[part 2 of 2: packages /E40_Platform_System_SystemPackage/Components to /E40_Platform_System_SystemPackage/Types/DataConstrs]
AUTOSAR XML (schema 4-2-1)
package /E40_Platform_System_SystemPackage/Components  (continued)
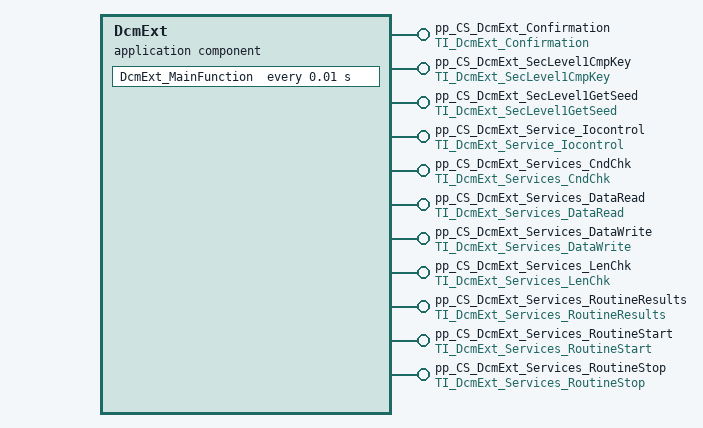
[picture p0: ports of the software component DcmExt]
  application sw component type DcmExt
    11 x provide port:
      pp_CS_DcmExt_Confirmation: server-com-spec{operation=DcmExt_Confirmation, queue-length=1}, provided-interface=TI_DcmExt_Confirmation
      pp_CS_DcmExt_SecLevel1CmpKey: server-com-spec{operation=DcmExt_SecLevel1CmpKey, queue-length=1}, provided-interface=TI_DcmExt_SecLevel1CmpKey
      pp_CS_DcmExt_SecLevel1GetSeed: server-com-spec{operation=DcmExt_SecLevel1GetSeed, queue-length=1}, provided-interface=TI_DcmExt_SecLevel1GetSeed
      pp_CS_DcmExt_Service_Iocontrol: server-com-spec{operation=DcmExt_Service_Iocontrol, queue-length=1}, provided-interface=TI_DcmExt_Service_Iocontrol
      pp_CS_DcmExt_Services_CndChk: server-com-spec{operation=DcmExt_Services_CndChk, queue-length=1}, provided-interface=TI_DcmExt_Services_CndChk
      pp_CS_DcmExt_Services_DataRead: server-com-spec{operation=DcmExt_Services_DataRead, queue-length=1}, provided-interface=TI_DcmExt_Services_DataRead
      pp_CS_DcmExt_Services_DataWrite: server-com-spec{operation=DcmExt_Services_DataWrite, queue-length=1}, provided-interface=TI_DcmExt_Services_DataWrite
      pp_CS_DcmExt_Services_LenChk: server-com-spec{operation=DcmExt_Services_LenChk, queue-length=1}, provided-interface=TI_DcmExt_Services_LenChk
      pp_CS_DcmExt_Services_RoutineResults: server-com-spec{operation=DcmExt_Services_RoutineResults, queue-length=1}, provided-interface=TI_DcmExt_Services_RoutineResults
      pp_CS_DcmExt_Services_RoutineStart: server-com-spec{operation=DcmExt_Services_RoutineStart, queue-length=1}, provided-interface=TI_DcmExt_Services_RoutineStart
      pp_CS_DcmExt_Services_RoutineStop: server-com-spec{operation=DcmExt_Services_RoutineStop, queue-length=1}, provided-interface=TI_DcmExt_Services_RoutineStop
    behavior IB_DcmExt
      11 x operation invoked event:
        OIE_pp_CS_DcmExt_Confirmation_DcmExt_ConfirmationTrigByDcmExt_Confirmation: start-on-event=DcmExt_Confirmation, operation=pp_CS_DcmExt_Confirmation.DcmExt_Confirmation
        OIE_pp_CS_DcmExt_SecLevel1CmpKey_DcmExt_SecLevel1CmpKeyTrigByDcmExt_SecLevel1CmpKey: start-on-event=DcmExt_SecLevel1CmpKey, operation=pp_CS_DcmExt_SecLevel1CmpKey.DcmExt_SecLevel1CmpKey
        OIE_pp_CS_DcmExt_SecLevel1GetSeed_DcmExt_SecLevel1GetSeedTrigByDcmExt_SecLevel1GetSeed: start-on-event=DcmExt_SecLevel1GetSeed, operation=pp_CS_DcmExt_SecLevel1GetSeed.DcmExt_SecLevel1GetSeed
        OIE_pp_CS_DcmExt_Service_Iocontrol_DcmExt_Service_IocontrolTrigByDcmExt_Service_Iocontrol: start-on-event=DcmExt_Service_Iocontrol, operation=pp_CS_DcmExt_Service_Iocontrol.DcmExt_Service_Iocontrol
        OIE_pp_CS_DcmExt_Services_CndChk_DcmExt_Services_CndChkTrigByDcmExt_Services_CndChk: start-on-event=DcmExt_Services_CndChk, operation=pp_CS_DcmExt_Services_CndChk.DcmExt_Services_CndChk
        OIE_pp_CS_DcmExt_Services_DataRead_DcmExt_Services_DataReadTrigByDcmExt_Services_DataRead: start-on-event=DcmExt_Services_DataRead, operation=pp_CS_DcmExt_Services_DataRead.DcmExt_Services_DataRead
        OIE_pp_CS_DcmExt_Services_DataWrite_DcmExt_Services_DataWriteTrigByDcmExt_Services_DataWrite: start-on-event=DcmExt_Services_DataWrite, operation=pp_CS_DcmExt_Services_DataWrite.DcmExt_Services_DataWrite
        OIE_pp_CS_DcmExt_Services_LenChk_DcmExt_Services_LenChkTrigByDcmExt_Services_LenChk: start-on-event=DcmExt_Services_LenChk, operation=pp_CS_DcmExt_Services_LenChk.DcmExt_Services_LenChk
        OIE_pp_CS_DcmExt_Services_RoutineResults_DcmExt_Services_RoutineResultsTrigByDcmExt_Services_RoutineResults: start-on-event=DcmExt_Services_RoutineResults, operation=pp_CS_DcmExt_Services_RoutineResults.DcmExt_Services_RoutineResults
        OIE_pp_CS_DcmExt_Services_RoutineStart_DcmExt_Services_RoutineStartTrigByDcmExt_Services_RoutineStart: start-on-event=DcmExt_Services_RoutineStart, operation=pp_CS_DcmExt_Services_RoutineStart.DcmExt_Services_RoutineStart
        OIE_pp_CS_DcmExt_Services_RoutineStop_DcmExt_Services_RoutineStopTrigByDcmExt_Services_RoutineStop: start-on-event=DcmExt_Services_RoutineStop, operation=pp_CS_DcmExt_Services_RoutineStop.DcmExt_Services_RoutineStop
      timing event TEDcmExt_MainFunction: start-on-event=DcmExt_MainFunction, period=0.01
      port-api-options:
        enable-take-address=false, indirect-api=false, port=pp_CS_DcmExt_Confirmation
        enable-take-address=false, indirect-api=false, port=pp_CS_DcmExt_SecLevel1CmpKey
        enable-take-address=false, indirect-api=false, port=pp_CS_DcmExt_SecLevel1GetSeed
        enable-take-address=false, indirect-api=false, port=pp_CS_DcmExt_Service_Iocontrol
        enable-take-address=false, indirect-api=false, port=pp_CS_DcmExt_Services_CndChk
        enable-take-address=false, indirect-api=false, port=pp_CS_DcmExt_Services_DataRead
        enable-take-address=false, indirect-api=false, port=pp_CS_DcmExt_Services_DataWrite
        enable-take-address=false, indirect-api=false, port=pp_CS_DcmExt_Services_LenChk
        enable-take-address=false, indirect-api=false, port=pp_CS_DcmExt_Services_RoutineResults
        enable-take-address=false, indirect-api=false, port=pp_CS_DcmExt_Services_RoutineStart
        enable-take-address=false, indirect-api=false, port=pp_CS_DcmExt_Services_RoutineStop
      12 x runnable, all with can-be-invoked-concurrently=true:
        DcmExt_Confirmation
        DcmExt_SecLevel1CmpKey
        DcmExt_SecLevel1GetSeed
        DcmExt_Service_Iocontrol
        DcmExt_Services_CndChk
        DcmExt_Services_DataRead
        DcmExt_Services_DataWrite
        DcmExt_Services_LenChk
        DcmExt_Services_RoutineResults
        DcmExt_Services_RoutineStart
        DcmExt_Services_RoutineStop
        DcmExt_MainFunction
  swc implementation IMPL_DcmExt: programming-language=C, behavior=IB_DcmExt
    code-descriptors:
      code CodeDescriptor
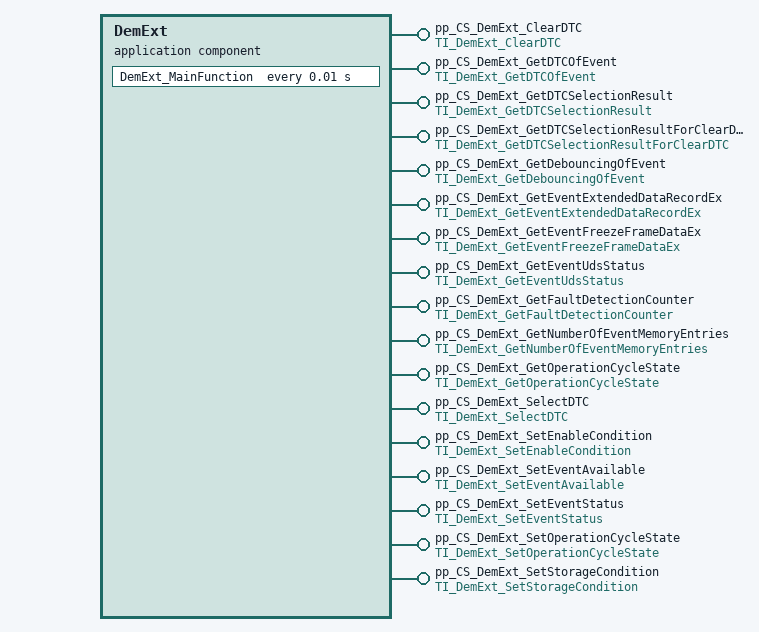
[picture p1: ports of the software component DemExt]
  application sw component type DemExt
    17 x provide port:
      pp_CS_DemExt_ClearDTC: server-com-spec{operation=DemExt_ClearDTC, queue-length=1}, provided-interface=TI_DemExt_ClearDTC
      pp_CS_DemExt_GetDTCOfEvent: server-com-spec{operation=DemExt_GetDTCOfEvent, queue-length=1}, provided-interface=TI_DemExt_GetDTCOfEvent
      pp_CS_DemExt_GetDTCSelectionResult: server-com-spec{operation=DemExt_GetDTCSelectionResult, queue-length=1}, provided-interface=TI_DemExt_GetDTCSelectionResult
      pp_CS_DemExt_GetDTCSelectionResultForClearDTC: server-com-spec{operation=DemExt_GetDTCSelectionResultForClearDTC, queue-length=1}, provided-interface=TI_DemExt_GetDTCSelectionResultForClearDTC
      pp_CS_DemExt_GetDebouncingOfEvent: server-com-spec{operation=DemExt_GetDebouncingOfEvent, queue-length=1}, provided-interface=TI_DemExt_GetDebouncingOfEvent
      pp_CS_DemExt_GetEventExtendedDataRecordEx: server-com-spec{operation=DemExt_GetEventExtendedDataRecordEx, queue-length=1}, provided-interface=TI_DemExt_GetEventExtendedDataRecordEx
      pp_CS_DemExt_GetEventFreezeFrameDataEx: server-com-spec{operation=DemExt_GetEventFreezeFrameDataEx, queue-length=1}, provided-interface=TI_DemExt_GetEventFreezeFrameDataEx
      pp_CS_DemExt_GetEventUdsStatus: server-com-spec{operation=DemExt_GetEventUdsStatus, queue-length=1}, provided-interface=TI_DemExt_GetEventUdsStatus
      pp_CS_DemExt_GetFaultDetectionCounter: server-com-spec{operation=DemExt_GetFaultDetectionCounter, queue-length=1}, provided-interface=TI_DemExt_GetFaultDetectionCounter
      pp_CS_DemExt_GetNumberOfEventMemoryEntries: server-com-spec{operation=DemExt_GetNumberOfEventMemoryEntries, queue-length=1}, provided-interface=TI_DemExt_GetNumberOfEventMemoryEntries
      pp_CS_DemExt_GetOperationCycleState: server-com-spec{operation=DemExt_GetOperationCycleState, queue-length=1}, provided-interface=TI_DemExt_GetOperationCycleState
      pp_CS_DemExt_SelectDTC: server-com-spec{operation=DemExt_SelectDTC, queue-length=1}, provided-interface=TI_DemExt_SelectDTC
      pp_CS_DemExt_SetEnableCondition: server-com-spec{operation=DemExt_SetEnableCondition, queue-length=1}, provided-interface=TI_DemExt_SetEnableCondition
      pp_CS_DemExt_SetEventAvailable: server-com-spec{operation=DemExt_SetEventAvailable, queue-length=1}, provided-interface=TI_DemExt_SetEventAvailable
      pp_CS_DemExt_SetEventStatus: server-com-spec{operation=DemExt_SetEventStatus, queue-length=1}, provided-interface=TI_DemExt_SetEventStatus
      pp_CS_DemExt_SetOperationCycleState: server-com-spec{operation=DemExt_SetOperationCycleState, queue-length=1}, provided-interface=TI_DemExt_SetOperationCycleState
      pp_CS_DemExt_SetStorageCondition: server-com-spec{operation=DemExt_SetStorageCondition, queue-length=1}, provided-interface=TI_DemExt_SetStorageCondition
    behavior IB_DemExt
      17 x operation invoked event:
        OIE_pp_CS_DemExt_ClearDTC_DemExt_ClearDTCTrigByDemExt_ClearDTC: start-on-event=DemExt_ClearDTC, operation=pp_CS_DemExt_ClearDTC.DemExt_ClearDTC
        OIE_pp_CS_DemExt_GetDTCOfEvent_DemExt_GetDTCOfEventTrigByDemExt_GetDTCOfEvent: start-on-event=DemExt_GetDTCOfEvent, operation=pp_CS_DemExt_GetDTCOfEvent.DemExt_GetDTCOfEvent
        OIE_pp_CS_DemExt_GetDTCSelectionResult_DemExt_GetDTCSelectionResultTrigByDemExt_GetDTCSelectionResult: start-on-event=DemExt_GetDTCSelectionResult, operation=pp_CS_DemExt_GetDTCSelectionResult.DemExt_GetDTCSelectionResult
        OperationInvokeEvent_1: start-on-event=DemExt_GetDTCSelectionResultForClearDTC, operation=pp_CS_DemExt_GetDTCSelectionResultForClearDTC.DemExt_GetDTCSelectionResultForClearDTC
        OIE_pp_CS_DemExt_GetDebouncingOfEvent_DemExt_GetDebouncingOfEventTrigByDemExt_GetDebouncingOfEvent: start-on-event=DemExt_GetDebouncingOfEvent, operation=pp_CS_DemExt_GetDebouncingOfEvent.DemExt_GetDebouncingOfEvent
        OIE_pp_CS_DemExt_GetEventExtendedDataRecordEx_DemExt_GetEventExtendedDataRecordExTrigByDemExt_GetEventExtendedDataRecordEx: start-on-event=DemExt_GetEventExtendedDataRecordEx, operation=pp_CS_DemExt_GetEventExtendedDataRecordEx.DemExt_GetEventExtendedDataRecordEx
        OIE_pp_CS_DemExt_GetEventFreezeFrameDataEx_DemExt_GetEventFreezeFrameDataExTrigByDemExt_GetEventFreezeFrameDataEx: start-on-event=DemExt_GetEventFreezeFrameDataEx, operation=pp_CS_DemExt_GetEventFreezeFrameDataEx.DemExt_GetEventFreezeFrameDataEx
        OIE_pp_CS_DemExt_GetEventUdsStatus_DemExt_GetEventUdsStatusTrigByDemExt_GetEventUdsStatus: start-on-event=DemExt_GetEventUdsStatus, operation=pp_CS_DemExt_GetEventUdsStatus.DemExt_GetEventUdsStatus
        OIE_pp_CS_DemExt_GetFaultDetectionCounter_DemExt_GetFaultDetectionCounterTrigByDemExt_GetFaultDetectionCounter: start-on-event=DemExt_GetFaultDetectionCounter, operation=pp_CS_DemExt_GetFaultDetectionCounter.DemExt_GetFaultDetectionCounter
        OIE_pp_CS_DemExt_GetNumberOfEventMemoryEntries_DemExt_GetNumberOfEventMemoryEntriesTrigByDemExt_GetNumberOfEventMemoryEntries: start-on-event=DemExt_GetNumberOfEventMemoryEntries, operation=pp_CS_DemExt_GetNumberOfEventMemoryEntries.DemExt_GetNumberOfEventMemoryEntries
        OIE_pp_CS_DemExt_GetOperationCycleState_DemExt_GetOperationCycleStateTrigByDemExt_GetOperationCycleState: start-on-event=DemExt_GetOperationCycleState, operation=pp_CS_DemExt_GetOperationCycleState.DemExt_GetOperationCycleState
        OIE_pp_CS_DemExt_SelectDTC_DemExt_SelectDTCTrigByDemExt_SelectDTC: start-on-event=DemExt_SelectDTC, operation=pp_CS_DemExt_SelectDTC.DemExt_SelectDTC
        OIE_pp_CS_DemExt_SetEnableCondition_DemExt_SetEnableConditionTrigByDemExt_SetEnableCondition: start-on-event=DemExt_SetEnableCondition, operation=pp_CS_DemExt_SetEnableCondition.DemExt_SetEnableCondition
        OIE_pp_CS_DemExt_SetEventAvailable_DemExt_SetEventAvailableTrigByDemExt_SetEventAvailable: start-on-event=DemExt_SetEventAvailable, operation=pp_CS_DemExt_SetEventAvailable.DemExt_SetEventAvailable
        OIE_pp_CS_DemExt_SetEventStatus_DemExt_SetEventStatusTrigByDemExt_SetEventStatus: start-on-event=DemExt_SetEventStatus, operation=pp_CS_DemExt_SetEventStatus.DemExt_SetEventStatus
        OIE_pp_CS_DemExt_SetOperationCycleState_DemExt_SetOperationCycleStateTrigByDemExt_SetOperationCycleState: start-on-event=DemExt_SetOperationCycleState, operation=pp_CS_DemExt_SetOperationCycleState.DemExt_SetOperationCycleState
        OIE_pp_CS_DemExt_SetStorageCondition_DemExt_SetStorageConditionTrigByDemExt_SetStorageCondition: start-on-event=DemExt_SetStorageCondition, operation=pp_CS_DemExt_SetStorageCondition.DemExt_SetStorageCondition
      timing event TEDemExt_MainFunction: start-on-event=DemExt_MainFunction, period=0.01
      port-api-options:
        enable-take-address=false, indirect-api=false, port=pp_CS_DemExt_ClearDTC
        enable-take-address=false, indirect-api=false, port=pp_CS_DemExt_GetDTCOfEvent
        enable-take-address=false, indirect-api=false, port=pp_CS_DemExt_GetDTCSelectionResult
        enable-take-address=false, indirect-api=false, port=pp_CS_DemExt_GetDTCSelectionResultForClearDTC
        enable-take-address=false, indirect-api=false, port=pp_CS_DemExt_GetDebouncingOfEvent
        enable-take-address=false, indirect-api=false, port=pp_CS_DemExt_GetEventExtendedDataRecordEx
        enable-take-address=false, indirect-api=false, port=pp_CS_DemExt_GetEventFreezeFrameDataEx
        enable-take-address=false, indirect-api=false, port=pp_CS_DemExt_GetEventUdsStatus
        enable-take-address=false, indirect-api=false, port=pp_CS_DemExt_GetFaultDetectionCounter
        enable-take-address=false, indirect-api=false, port=pp_CS_DemExt_GetNumberOfEventMemoryEntries
        enable-take-address=false, indirect-api=false, port=pp_CS_DemExt_GetOperationCycleState
        enable-take-address=false, indirect-api=false, port=pp_CS_DemExt_SelectDTC
        enable-take-address=false, indirect-api=false, port=pp_CS_DemExt_SetEnableCondition
        enable-take-address=false, indirect-api=false, port=pp_CS_DemExt_SetEventAvailable
        enable-take-address=false, indirect-api=false, port=pp_CS_DemExt_SetEventStatus
        enable-take-address=false, indirect-api=false, port=pp_CS_DemExt_SetOperationCycleState
        enable-take-address=false, indirect-api=false, port=pp_CS_DemExt_SetStorageCondition
      18 x runnable, all with can-be-invoked-concurrently=true:
        DemExt_ClearDTC
        DemExt_GetDTCOfEvent
        DemExt_GetDTCSelectionResult
        DemExt_GetDTCSelectionResultForClearDTC
        DemExt_GetDebouncingOfEvent
        DemExt_GetEventExtendedDataRecordEx
        DemExt_GetEventFreezeFrameDataEx
        DemExt_GetEventUdsStatus
        DemExt_GetFaultDetectionCounter
        DemExt_GetNumberOfEventMemoryEntries
        DemExt_GetOperationCycleState
        DemExt_SelectDTC
        DemExt_SetEnableCondition
        DemExt_SetEventAvailable
        DemExt_SetEventStatus
        DemExt_SetOperationCycleState
        DemExt_SetStorageCondition
        DemExt_MainFunction
  swc implementation IMPL_DemExt: programming-language=C, behavior=IB_DemExt
    code-descriptors:
      code CodeDescriptor
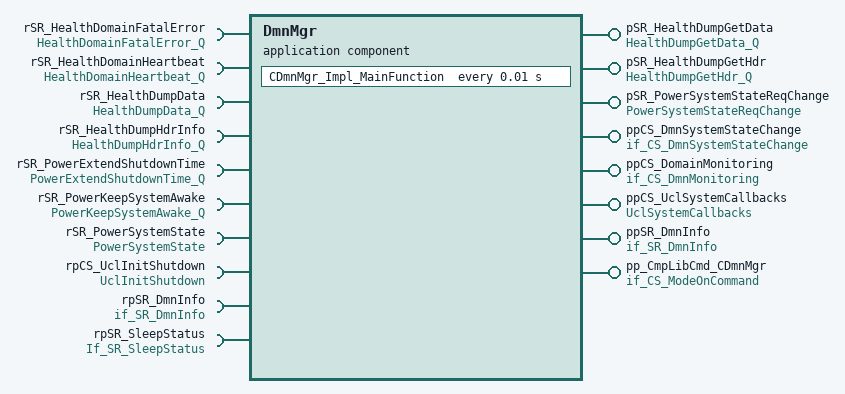
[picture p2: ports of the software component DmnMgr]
  application sw component type DmnMgr
    8 x provide port:
      pSR_HealthDumpGetData: queued-sender-com-spec=HealthDumpGetDataData, provided-interface=HealthDumpGetData_Q
      pSR_HealthDumpGetHdr: queued-sender-com-spec=HealthDumpGetHdrData, provided-interface=HealthDumpGetHdr_Q
      pSR_PowerSystemStateReqChange: nonqueued-sender-com-spec{data-element=PowerSystemStateReqChangeData, init-value=constant-reference=DmnMgrPowerSystemStateReqChangeDataValue0}, provided-interface=PowerSystemStateReqChange
      ppCS_DmnSystemStateChange: provided-interface=if_CS_DmnSystemStateChange
        provided-com-specs:
          operation=DmnSystemStateChangeReq, queue-length=1
          operation=DmnSystemStateChangeStatus, queue-length=1
      ppCS_DomainMonitoring: provided-com-specs=[{operation=StartDomainMonitoring, queue-length=1}, {operation=StopDomainMonitoring, queue-length=1}], provided-interface=if_CS_DmnMonitoring
      ppCS_UclSystemCallbacks: provided-com-specs=[{operation=ErrorNotification, queue-length=1}, {operation=LinkStatusChanged, queue-length=1}], provided-interface=UclSystemCallbacks
      ppSR_DmnInfo: nonqueued-sender-com-spec{data-element=SDmnStatus, init-value=constant-reference=DmnMgrSDmnStatusValue0}, provided-interface=if_SR_DmnInfo
      pp_CmpLibCmd_CDmnMgr: server-com-spec{operation=Impl_OnCommand, queue-length=1}, provided-interface=if_CS_ModeOnCommand
    10 x require port:
      rSR_HealthDomainFatalError: queued-receiver-com-spec{data-element=HealthDomainFatalErrorData, queue-length=2}, required-interface=HealthDomainFatalError_Q
      rSR_HealthDomainHeartbeat: queued-receiver-com-spec{data-element=HealthDomainHeartbeatData, queue-length=5}, required-interface=HealthDomainHeartbeat_Q
      rSR_HealthDumpData: queued-receiver-com-spec{data-element=HealthDumpDataData, queue-length=1}, required-interface=HealthDumpData_Q
      rSR_HealthDumpHdrInfo: queued-receiver-com-spec{data-element=HealthDumpHdrInfoData, queue-length=1}, required-interface=HealthDumpHdrInfo_Q
      rSR_PowerExtendShutdownTime: queued-receiver-com-spec{data-element=PowerExtendShutdownTimeData, queue-length=5}, required-interface=PowerExtendShutdownTime_Q
      rSR_PowerKeepSystemAwake: queued-receiver-com-spec{data-element=PowerKeepSystemAwakeData, queue-length=5}, required-interface=PowerKeepSystemAwake_Q
      rSR_PowerSystemState: nonqueued-receiver-com-spec{data-element=PowerSystemStateData, init-value=constant-reference=DmnMgrPowerSystemStateDataValue0}, required-interface=PowerSystemState
      rpCS_UclInitShutdown: required-interface=UclInitShutdown
      rpSR_DmnInfo: nonqueued-receiver-com-spec{data-element=SDmnStatus, init-value=constant-reference=DmnMgrSDmnStatusValue0}, required-interface=if_SR_DmnInfo
      rpSR_SleepStatus: nonqueued-receiver-com-spec{data-element=SleepManager_SleepStatus, init-value=constant-reference=DmnMgrSleepManager_SleepStatusValue0}, required-interface=If_SR_SleepStatus
    behavior IB_DmnMgr
      timing event TECDmnMgr_Impl_MainFunction: start-on-event=CDmnMgr_Impl_MainFunction, period=0.01
      5 x operation invoked event:
        OIE_pp_CmpLibCmd_CDmnMgr_CDmnMgr_Impl_OnCommandTrigByImpl_OnCommand: start-on-event=CDmnMgr_Impl_OnCommand, operation=pp_CmpLibCmd_CDmnMgr.Impl_OnCommand
        OIE_ppCS_DmnSystemStateChange_DmnMgr_DmnSystemStateChangeReqTrigByDmnSystemStateChangeReq: start-on-event=DmnMgr_DmnSystemStateChangeReq, operation=ppCS_DmnSystemStateChange.DmnSystemStateChangeReq
        OIE_ppCS_DmnSystemStateChange_DmnMgr_DmnSystemStateChangeStatusTrigByDmnSystemStateChangeStatus: start-on-event=DmnMgr_DmnSystemStateChangeStatus, operation=ppCS_DmnSystemStateChange.DmnSystemStateChangeStatus
        OIE_ppCS_UclSystemCallbacks_DmnMgr_ErrorNotificationTrigByErrorNotification: start-on-event=DmnMgr_ErrorNotification, operation=ppCS_UclSystemCallbacks.ErrorNotification
        OIE_ppCS_UclSystemCallbacks_DmnMgr_LinkStatusChangedTrigByLinkStatusChanged: start-on-event=DmnMgr_LinkStatusChanged, operation=ppCS_UclSystemCallbacks.LinkStatusChanged
      7 x data received event:
        DREDmnMgr_MonitorDmnExtendShutdownTimeTrigByPowerExtendShutdownTimeData: start-on-event=DmnMgr_MonitorDmnExtendShutdownTime, data=rSR_PowerExtendShutdownTime.PowerExtendShutdownTimeData
        DREDmnMgr_MonitorDmnHealthDumpDataTrigByHealthDumpDataData: start-on-event=DmnMgr_MonitorDmnHealthDumpData, data=rSR_HealthDumpData.HealthDumpDataData
        DREDmnMgr_MonitorDmnHealthDumpHdrInfoTrigByHealthDumpHdrInfoData: start-on-event=DmnMgr_MonitorDmnHealthDumpHdrInfo, data=rSR_HealthDumpHdrInfo.HealthDumpHdrInfoData
        DREDmnMgr_MonitorDmnHealthFatalErrorTrigByHealthDomainFatalErrorData: start-on-event=DmnMgr_MonitorDmnHealthFatalError, data=rSR_HealthDomainFatalError.HealthDomainFatalErrorData
        DREDmnMgr_MonitorDmnHeartBeatTrigByHealthDomainHeartbeatData: start-on-event=DmnMgr_MonitorDmnHeartBeat, data=rSR_HealthDomainHeartbeat.HealthDomainHeartbeatData
        DREDmnMgr_MonitorDmnKeepSystemAwakeTrigByPowerKeepSystemAwakeData: start-on-event=DmnMgr_MonitorDmnKeepSystemAwake, data=rSR_PowerKeepSystemAwake.PowerKeepSystemAwakeData
        DREDmnMgr_MonitorDmnPowerSystemStateTrigByPowerSystemStateData: start-on-event=DmnMgr_MonitorDmnPowerSystemState, data=rSR_PowerSystemState.PowerSystemStateData
      operation invoked event OIE_ppCS_DomainMonitoring_DmnMgr_StartDomainMonitoringTrigByStartDomainMonitoring: start-on-event=DmnMgr_StartDomainMonitoring, operation=ppCS_DomainMonitoring.StartDomainMonitoring
      operation invoked event OIE_ppCS_DomainMonitoring_DmnMgr_StopDomainMonitoringTrigByStopDomainMonitoring: start-on-event=DmnMgr_StopDomainMonitoring, operation=ppCS_DomainMonitoring.StopDomainMonitoring
      port-api-options:
        enable-take-address=false, indirect-api=false, port=pSR_HealthDumpGetData
        enable-take-address=false, indirect-api=false, port=pSR_HealthDumpGetHdr
        enable-take-address=false, indirect-api=false, port=pSR_PowerSystemStateReqChange
        enable-take-address=false, indirect-api=false, port=ppCS_DmnSystemStateChange
        enable-take-address=false, indirect-api=false, port=ppCS_DomainMonitoring
        enable-take-address=false, indirect-api=false, port=ppCS_UclSystemCallbacks
        enable-take-address=false, indirect-api=false, port=ppSR_DmnInfo
        enable-take-address=false, indirect-api=false, port=pp_CmpLibCmd_CDmnMgr
        enable-take-address=false, indirect-api=false, port=rSR_HealthDomainFatalError
        enable-take-address=false, indirect-api=false, port=rSR_HealthDomainHeartbeat
        enable-take-address=false, indirect-api=false, port=rSR_HealthDumpData
        enable-take-address=false, indirect-api=false, port=rSR_HealthDumpHdrInfo
        enable-take-address=false, indirect-api=false, port=rSR_PowerExtendShutdownTime
        enable-take-address=false, indirect-api=false, port=rSR_PowerKeepSystemAwake
        enable-take-address=false, indirect-api=false, port=rSR_PowerSystemState
        enable-take-address=false, indirect-api=false, port=rpCS_UclInitShutdown
        enable-take-address=false, indirect-api=false, port=rpSR_DmnInfo
        enable-take-address=false, indirect-api=false, port=DmnMgr/rpSR_SleepStatus
      15 x runnable, all with can-be-invoked-concurrently=true:
        CDmnMgr_Impl_MainFunction
          data-receive-point-by-arguments:
            9 x access:
              DRP_rSR_HealthDomainFatalError_HealthDomainFatalErrorData: accessed-variable=rSR_HealthDomainFatalError.HealthDomainFatalErrorData
              DRP_rSR_HealthDomainHeartbeat_HealthDomainHeartbeatData: accessed-variable=rSR_HealthDomainHeartbeat.HealthDomainHeartbeatData
              DRP_rSR_HealthDumpData_HealthDumpDataData: accessed-variable=rSR_HealthDumpData.HealthDumpDataData
              DRP_rSR_HealthDumpHdrInfo_HealthDumpHdrInfoData: accessed-variable=rSR_HealthDumpHdrInfo.HealthDumpHdrInfoData
              DRP_rSR_PowerExtendShutdownTime_PowerExtendShutdownTimeData: accessed-variable=rSR_PowerExtendShutdownTime.PowerExtendShutdownTimeData
              DRP_rSR_PowerKeepSystemAwake_PowerKeepSystemAwakeData: accessed-variable=rSR_PowerKeepSystemAwake.PowerKeepSystemAwakeData
              DRA_rSR_PowerSystemState_PowerSystemStateData: accessed-variable=rSR_PowerSystemState.PowerSystemStateData
              DRA_rpSR_DmnInfo_SDmnStatus: accessed-variable=rpSR_DmnInfo.SDmnStatus
              DRA_rpSR_SleepStatus_SleepManager_SleepStatus: accessed-variable=rpSR_SleepStatus.SleepManager_SleepStatus
          data-send-points:
            4 x access:
              DSP_pSR_HealthDumpGetData_HealthDumpGetDataData: accessed-variable=pSR_HealthDumpGetData.HealthDumpGetDataData
              DSP_pSR_HealthDumpGetHdr_HealthDumpGetHdrData: accessed-variable=pSR_HealthDumpGetHdr.HealthDumpGetHdrData
              DWA_pSR_PowerSystemStateReqChange_PowerSystemStateReqChangeData: accessed-variable=pSR_PowerSystemStateReqChange.PowerSystemStateReqChangeData
              DWA_ppSR_DmnInfo_SDmnStatus: accessed-variable=ppSR_DmnInfo.SDmnStatus
          sync call OA_rpCS_UclInitShutdown_Impl_Shutdown: operation=rpCS_UclInitShutdown.Impl_Shutdown, timeout=0.0
          sync call OA_rpCS_UclInitShutdown_Impl_Initialize: operation=rpCS_UclInitShutdown.Impl_Initialize, timeout=0.0
        CDmnMgr_Impl_OnCommand
        DmnMgr_DmnSystemStateChangeReq
        DmnMgr_DmnSystemStateChangeStatus
        DmnMgr_ErrorNotification
        DmnMgr_LinkStatusChanged
        DmnMgr_MonitorDmnExtendShutdownTime
        DmnMgr_MonitorDmnHealthDumpData
        DmnMgr_MonitorDmnHealthDumpHdrInfo
        DmnMgr_MonitorDmnHealthFatalError
        DmnMgr_MonitorDmnHeartBeat
        DmnMgr_MonitorDmnKeepSystemAwake
        DmnMgr_MonitorDmnPowerSystemState
        DmnMgr_StartDomainMonitoring
        DmnMgr_StopDomainMonitoring
  4 x constant specification:
    DmnMgrPowerSystemStateReqChangeDataValue0: value-spec={short-label=DmnMgrPowerSystemStateReqChangeDataValue0, fields=[DmnMgrPowerSystemStateReqChangeDataValue_0:0, DmnMgrPowerSystemStateReqChangeDataValue_1:0]}
    DmnMgrSDmnStatusValue0: value-spec={short-label=DmnMgrSDmnStatusValue0, fields=[DmnMgrSDmnStatusValue_0:0, DmnMgrSDmnStatusValue_1:0, DmnMgrSDmnStatusValue_2:0, DmnMgrSDmnStatusValue_3:0, DmnMgrSDmnStatusValue_4:0, DmnMgrSDmnStatusValue_5:0]}
    DmnMgrPowerSystemStateDataValue0: value-spec={short-label=DmnMgrPowerSystemStateDataValue0, fields=[DmnMgrPowerSystemStateDataValue_0:0, DmnMgrPowerSystemStateDataValue_1:0]}
    DmnMgrSleepManager_SleepStatusValue0: value-spec=DmnMgrSleepManager_SleepStatusValue0:0
  swc implementation IMPL_DmnMgr: programming-language=C, behavior=IB_DmnMgr
    code-descriptors:
      code CodeDescriptor
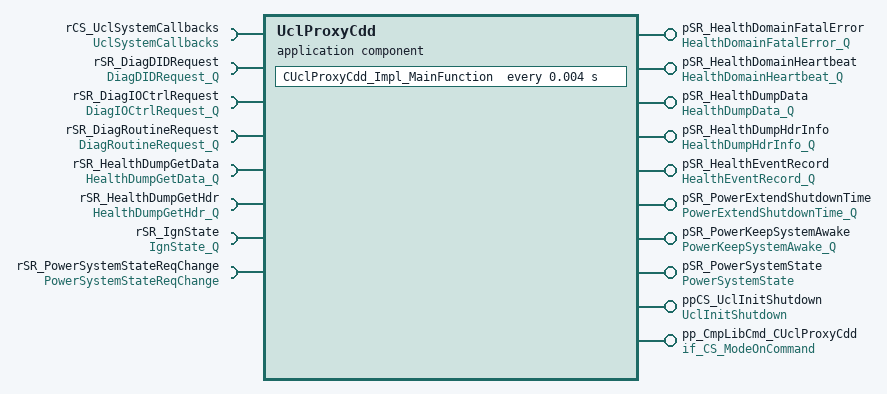
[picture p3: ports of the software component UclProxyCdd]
  application sw component type UclProxyCdd
    10 x provide port:
      pSR_HealthDomainFatalError: queued-sender-com-spec=HealthDomainFatalErrorData, provided-interface=HealthDomainFatalError_Q
      pSR_HealthDomainHeartbeat: queued-sender-com-spec=HealthDomainHeartbeatData, provided-interface=HealthDomainHeartbeat_Q
      pSR_HealthDumpData: queued-sender-com-spec=HealthDumpDataData, provided-interface=HealthDumpData_Q
      pSR_HealthDumpHdrInfo: queued-sender-com-spec=HealthDumpHdrInfoData, provided-interface=HealthDumpHdrInfo_Q
      pSR_HealthEventRecord: queued-sender-com-spec=HealthEventRecordData, provided-interface=HealthEventRecord_Q
      pSR_PowerExtendShutdownTime: queued-sender-com-spec=PowerExtendShutdownTimeData, provided-interface=PowerExtendShutdownTime_Q
      pSR_PowerKeepSystemAwake: queued-sender-com-spec=PowerKeepSystemAwakeData, provided-interface=PowerKeepSystemAwake_Q
      pSR_PowerSystemState: nonqueued-sender-com-spec{data-element=PowerSystemStateData, init-value=constant-reference=UclProxyCddPowerSystemStateDataValue0}, provided-interface=PowerSystemState
      ppCS_UclInitShutdown: provided-com-specs=[{operation=Impl_Initialize, queue-length=1}, {operation=Impl_Shutdown, queue-length=1}], provided-interface=UclInitShutdown
      pp_CmpLibCmd_CUclProxyCdd: server-com-spec{operation=Impl_OnCommand, queue-length=1}, provided-interface=if_CS_ModeOnCommand
    8 x require port:
      rCS_UclSystemCallbacks: required-interface=UclSystemCallbacks
      rSR_DiagDIDRequest: queued-receiver-com-spec{data-element=DiagDIDRequestData, queue-length=2}, required-interface=DiagDIDRequest_Q
      rSR_DiagIOCtrlRequest: queued-receiver-com-spec{data-element=DiagIOCtrlRequestData, queue-length=2}, required-interface=DiagIOCtrlRequest_Q
      rSR_DiagRoutineRequest: queued-receiver-com-spec{data-element=DiagRoutineRequestData, queue-length=2}, required-interface=DiagRoutineRequest_Q
      rSR_HealthDumpGetData: queued-receiver-com-spec{data-element=HealthDumpGetDataData, queue-length=1}, required-interface=HealthDumpGetData_Q
      rSR_HealthDumpGetHdr: queued-receiver-com-spec{data-element=HealthDumpGetHdrData, queue-length=1}, required-interface=HealthDumpGetHdr_Q
      rSR_IgnState: queued-receiver-com-spec{data-element=IgnStateData, queue-length=5}, required-interface=IgnState_Q
      rSR_PowerSystemStateReqChange: nonqueued-receiver-com-spec{data-element=PowerSystemStateReqChangeData, init-value=constant-reference=UclProxyCddPowerSystemStateReqChangeDataValue0}, required-interface=PowerSystemStateReqChange
    behavior IB_UclProxyCdd
      operation invoked event OIE_ppCS_UclInitShutdown_CUclProxyCdd_Impl_InitializeTrigByImpl_Initialize: start-on-event=CUclProxyCdd_Impl_Initialize, operation=ppCS_UclInitShutdown.Impl_Initialize
      timing event TECUclProxyCdd_Impl_MainFunction: start-on-event=CUclProxyCdd_Impl_MainFunction, period=0.004
      operation invoked event OIE_pp_CmpLibCmd_CUclProxyCdd_CUclProxyCdd_Impl_OnCommandTrigByImpl_OnCommand: start-on-event=CUclProxyCdd_Impl_OnCommand, operation=pp_CmpLibCmd_CUclProxyCdd.Impl_OnCommand
      operation invoked event OIE_ppCS_UclInitShutdown_CUclProxyCdd_Impl_ShutdownTrigByImpl_Shutdown: start-on-event=CUclProxyCdd_Impl_Shutdown, operation=ppCS_UclInitShutdown.Impl_Shutdown
      data received event DREOnDre_HealthDumpGetDataTrigByHealthDumpGetDataData: start-on-event=OnDre_HealthDumpGetData, data=rSR_HealthDumpGetData.HealthDumpGetDataData
      data received event DREOnDre_HealthDumpGetHdrTrigByHealthDumpGetHdrData: start-on-event=OnDre_HealthDumpGetHdr, data=rSR_HealthDumpGetHdr.HealthDumpGetHdrData
      data received event DREOnDre_PowerSystemStateReqChangeTrigByPowerSystemStateReqChangeData: start-on-event=OnDre_PowerSystemStateReqChange, data=rSR_PowerSystemStateReqChange.PowerSystemStateReqChangeData
      port-api-options:
        enable-take-address=false, indirect-api=false, port=pSR_HealthDomainFatalError
        enable-take-address=false, indirect-api=false, port=pSR_HealthDomainHeartbeat
        enable-take-address=false, indirect-api=false, port=pSR_HealthDumpData
        enable-take-address=false, indirect-api=false, port=pSR_HealthDumpHdrInfo
        enable-take-address=false, indirect-api=false, port=pSR_HealthEventRecord
        enable-take-address=false, indirect-api=false, port=pSR_PowerExtendShutdownTime
        enable-take-address=false, indirect-api=false, port=pSR_PowerKeepSystemAwake
        enable-take-address=false, indirect-api=false, port=pSR_PowerSystemState
        enable-take-address=false, indirect-api=false, port=ppCS_UclInitShutdown
        enable-take-address=false, indirect-api=false, port=pp_CmpLibCmd_CUclProxyCdd
        enable-take-address=false, indirect-api=false, port=rCS_UclSystemCallbacks
        enable-take-address=false, indirect-api=false, port=rSR_DiagDIDRequest
        enable-take-address=false, indirect-api=false, port=rSR_DiagIOCtrlRequest
        enable-take-address=false, indirect-api=false, port=rSR_DiagRoutineRequest
        enable-take-address=false, indirect-api=false, port=rSR_HealthDumpGetData
        enable-take-address=false, indirect-api=false, port=rSR_HealthDumpGetHdr
        enable-take-address=false, indirect-api=false, port=rSR_IgnState
        enable-take-address=false, indirect-api=false, port=rSR_PowerSystemStateReqChange
      7 x runnable, all with can-be-invoked-concurrently=true:
        CUclProxyCdd_Impl_Initialize
        CUclProxyCdd_Impl_MainFunction
          data-receive-point-by-arguments:
            7 x access:
              DRP_rSR_DiagDIDRequest_DiagDIDRequestData: accessed-variable=rSR_DiagDIDRequest.DiagDIDRequestData
              DRP_rSR_DiagIOCtrlRequest_DiagIOCtrlRequestData: accessed-variable=rSR_DiagIOCtrlRequest.DiagIOCtrlRequestData
              DRP_rSR_DiagRoutineRequest_DiagRoutineRequestData: accessed-variable=rSR_DiagRoutineRequest.DiagRoutineRequestData
              DRP_rSR_HealthDumpGetData_HealthDumpGetDataData: accessed-variable=rSR_HealthDumpGetData.HealthDumpGetDataData
              DRP_rSR_HealthDumpGetHdr_HealthDumpGetHdrData: accessed-variable=rSR_HealthDumpGetHdr.HealthDumpGetHdrData
              DRP_rSR_IgnState_IgnStateData: accessed-variable=rSR_IgnState.IgnStateData
              DRA_rSR_PowerSystemStateReqChange_PowerSystemStateReqChangeData: accessed-variable=rSR_PowerSystemStateReqChange.PowerSystemStateReqChangeData
          data-send-points:
            8 x access:
              DSP_pSR_HealthDomainFatalError_HealthDomainFatalErrorData: accessed-variable=pSR_HealthDomainFatalError.HealthDomainFatalErrorData
              DSP_pSR_HealthDomainHeartbeat_HealthDomainHeartbeatData: accessed-variable=pSR_HealthDomainHeartbeat.HealthDomainHeartbeatData
              DSP_pSR_HealthDumpData_HealthDumpDataData: accessed-variable=pSR_HealthDumpData.HealthDumpDataData
              DSP_pSR_HealthDumpHdrInfo_HealthDumpHdrInfoData: accessed-variable=pSR_HealthDumpHdrInfo.HealthDumpHdrInfoData
              DSP_pSR_HealthEventRecord_HealthEventRecordData: accessed-variable=pSR_HealthEventRecord.HealthEventRecordData
              DSP_pSR_PowerExtendShutdownTime_PowerExtendShutdownTimeData: accessed-variable=pSR_PowerExtendShutdownTime.PowerExtendShutdownTimeData
              DSP_pSR_PowerKeepSystemAwake_PowerKeepSystemAwakeData: accessed-variable=pSR_PowerKeepSystemAwake.PowerKeepSystemAwakeData
              DWA_pSR_PowerSystemState_PowerSystemStateData: accessed-variable=pSR_PowerSystemState.PowerSystemStateData
          sync call OA_rCS_UclSystemCallbacks_ErrorNotification: operation=rCS_UclSystemCallbacks.ErrorNotification, timeout=0.0
          sync call OA_rCS_UclSystemCallbacks_LinkStatusChanged: operation=rCS_UclSystemCallbacks.LinkStatusChanged, timeout=0.0
        CUclProxyCdd_Impl_OnCommand
        CUclProxyCdd_Impl_Shutdown
        OnDre_HealthDumpGetData
          data-receive-point-by-arguments:
            7 x access:
              DRP_rSR_DiagDIDRequest_DiagDIDRequestData: accessed-variable=rSR_DiagDIDRequest.DiagDIDRequestData
              DRP_rSR_DiagIOCtrlRequest_DiagIOCtrlRequestData: accessed-variable=rSR_DiagIOCtrlRequest.DiagIOCtrlRequestData
              DRP_rSR_DiagRoutineRequest_DiagRoutineRequestData: accessed-variable=rSR_DiagRoutineRequest.DiagRoutineRequestData
              DRP_rSR_HealthDumpGetData_HealthDumpGetDataData: accessed-variable=rSR_HealthDumpGetData.HealthDumpGetDataData
              DRP_rSR_HealthDumpGetHdr_HealthDumpGetHdrData: accessed-variable=rSR_HealthDumpGetHdr.HealthDumpGetHdrData
              DRP_rSR_IgnState_IgnStateData: accessed-variable=rSR_IgnState.IgnStateData
              DRA_rSR_PowerSystemStateReqChange_PowerSystemStateReqChangeData: accessed-variable=rSR_PowerSystemStateReqChange.PowerSystemStateReqChangeData
          data-send-points:
            8 x access:
              DSP_pSR_HealthDomainFatalError_HealthDomainFatalErrorData: accessed-variable=pSR_HealthDomainFatalError.HealthDomainFatalErrorData
              DSP_pSR_HealthDomainHeartbeat_HealthDomainHeartbeatData: accessed-variable=pSR_HealthDomainHeartbeat.HealthDomainHeartbeatData
              DSP_pSR_HealthDumpData_HealthDumpDataData: accessed-variable=pSR_HealthDumpData.HealthDumpDataData
              DSP_pSR_HealthDumpHdrInfo_HealthDumpHdrInfoData: accessed-variable=pSR_HealthDumpHdrInfo.HealthDumpHdrInfoData
              DSP_pSR_HealthEventRecord_HealthEventRecordData: accessed-variable=pSR_HealthEventRecord.HealthEventRecordData
              DSP_pSR_PowerExtendShutdownTime_PowerExtendShutdownTimeData: accessed-variable=pSR_PowerExtendShutdownTime.PowerExtendShutdownTimeData
              DSP_pSR_PowerKeepSystemAwake_PowerKeepSystemAwakeData: accessed-variable=pSR_PowerKeepSystemAwake.PowerKeepSystemAwakeData
              DWA_pSR_PowerSystemState_PowerSystemStateData: accessed-variable=pSR_PowerSystemState.PowerSystemStateData
          sync call OA_rCS_UclSystemCallbacks_ErrorNotification: operation=rCS_UclSystemCallbacks.ErrorNotification, timeout=0.0
          sync call OA_rCS_UclSystemCallbacks_LinkStatusChanged: operation=rCS_UclSystemCallbacks.LinkStatusChanged, timeout=0.0
        OnDre_HealthDumpGetHdr
          data-receive-point-by-arguments:
            7 x access:
              DRP_rSR_DiagDIDRequest_DiagDIDRequestData: accessed-variable=rSR_DiagDIDRequest.DiagDIDRequestData
              DRP_rSR_DiagIOCtrlRequest_DiagIOCtrlRequestData: accessed-variable=rSR_DiagIOCtrlRequest.DiagIOCtrlRequestData
              DRP_rSR_DiagRoutineRequest_DiagRoutineRequestData: accessed-variable=rSR_DiagRoutineRequest.DiagRoutineRequestData
              DRP_rSR_HealthDumpGetData_HealthDumpGetDataData: accessed-variable=rSR_HealthDumpGetData.HealthDumpGetDataData
              DRP_rSR_HealthDumpGetHdr_HealthDumpGetHdrData: accessed-variable=rSR_HealthDumpGetHdr.HealthDumpGetHdrData
              DRP_rSR_IgnState_IgnStateData: accessed-variable=rSR_IgnState.IgnStateData
              DRA_rSR_PowerSystemStateReqChange_PowerSystemStateReqChangeData: accessed-variable=rSR_PowerSystemStateReqChange.PowerSystemStateReqChangeData
          data-send-points:
            8 x access:
              DSP_pSR_HealthDomainFatalError_HealthDomainFatalErrorData: accessed-variable=pSR_HealthDomainFatalError.HealthDomainFatalErrorData
              DSP_pSR_HealthDomainHeartbeat_HealthDomainHeartbeatData: accessed-variable=pSR_HealthDomainHeartbeat.HealthDomainHeartbeatData
              DSP_pSR_HealthDumpData_HealthDumpDataData: accessed-variable=pSR_HealthDumpData.HealthDumpDataData
              DSP_pSR_HealthDumpHdrInfo_HealthDumpHdrInfoData: accessed-variable=pSR_HealthDumpHdrInfo.HealthDumpHdrInfoData
              DSP_pSR_HealthEventRecord_HealthEventRecordData: accessed-variable=pSR_HealthEventRecord.HealthEventRecordData
              DSP_pSR_PowerExtendShutdownTime_PowerExtendShutdownTimeData: accessed-variable=pSR_PowerExtendShutdownTime.PowerExtendShutdownTimeData
              DSP_pSR_PowerKeepSystemAwake_PowerKeepSystemAwakeData: accessed-variable=pSR_PowerKeepSystemAwake.PowerKeepSystemAwakeData
              DWA_pSR_PowerSystemState_PowerSystemStateData: accessed-variable=pSR_PowerSystemState.PowerSystemStateData
          sync call OA_rCS_UclSystemCallbacks_ErrorNotification: operation=rCS_UclSystemCallbacks.ErrorNotification, timeout=0.0
          sync call OA_rCS_UclSystemCallbacks_LinkStatusChanged: operation=rCS_UclSystemCallbacks.LinkStatusChanged, timeout=0.0
        OnDre_PowerSystemStateReqChange
          data-receive-point-by-arguments:
            7 x access:
              DRP_rSR_DiagDIDRequest_DiagDIDRequestData: accessed-variable=rSR_DiagDIDRequest.DiagDIDRequestData
              DRP_rSR_DiagIOCtrlRequest_DiagIOCtrlRequestData: accessed-variable=rSR_DiagIOCtrlRequest.DiagIOCtrlRequestData
              DRP_rSR_DiagRoutineRequest_DiagRoutineRequestData: accessed-variable=rSR_DiagRoutineRequest.DiagRoutineRequestData
              DRP_rSR_HealthDumpGetData_HealthDumpGetDataData: accessed-variable=rSR_HealthDumpGetData.HealthDumpGetDataData
              DRP_rSR_HealthDumpGetHdr_HealthDumpGetHdrData: accessed-variable=rSR_HealthDumpGetHdr.HealthDumpGetHdrData
              DRP_rSR_IgnState_IgnStateData: accessed-variable=rSR_IgnState.IgnStateData
              DRA_rSR_PowerSystemStateReqChange_PowerSystemStateReqChangeData: accessed-variable=rSR_PowerSystemStateReqChange.PowerSystemStateReqChangeData
          data-send-points:
            8 x access:
              DSP_pSR_HealthDomainFatalError_HealthDomainFatalErrorData: accessed-variable=pSR_HealthDomainFatalError.HealthDomainFatalErrorData
              DSP_pSR_HealthDomainHeartbeat_HealthDomainHeartbeatData: accessed-variable=pSR_HealthDomainHeartbeat.HealthDomainHeartbeatData
              DSP_pSR_HealthDumpData_HealthDumpDataData: accessed-variable=pSR_HealthDumpData.HealthDumpDataData
              DSP_pSR_HealthDumpHdrInfo_HealthDumpHdrInfoData: accessed-variable=pSR_HealthDumpHdrInfo.HealthDumpHdrInfoData
              DSP_pSR_HealthEventRecord_HealthEventRecordData: accessed-variable=pSR_HealthEventRecord.HealthEventRecordData
              DSP_pSR_PowerExtendShutdownTime_PowerExtendShutdownTimeData: accessed-variable=pSR_PowerExtendShutdownTime.PowerExtendShutdownTimeData
              DSP_pSR_PowerKeepSystemAwake_PowerKeepSystemAwakeData: accessed-variable=pSR_PowerKeepSystemAwake.PowerKeepSystemAwakeData
              DWA_pSR_PowerSystemState_PowerSystemStateData: accessed-variable=pSR_PowerSystemState.PowerSystemStateData
          sync call OA_rCS_UclSystemCallbacks_ErrorNotification: operation=rCS_UclSystemCallbacks.ErrorNotification, timeout=0.0
          sync call OA_rCS_UclSystemCallbacks_LinkStatusChanged: operation=rCS_UclSystemCallbacks.LinkStatusChanged, timeout=0.0
  constant specification UclProxyCddPowerSystemStateDataValue0: value-spec={short-label=UclProxyCddPowerSystemStateDataValue0, fields=[UclProxyCddPowerSystemStateDataValue_0:0, UclProxyCddPowerSystemStateDataValue_1:0]}
  constant specification UclProxyCddPowerSystemStateReqChangeDataValue0: value-spec={short-label=UclProxyCddPowerSystemStateReqChangeDataValue0, fields=[UclProxyCddPowerSystemStateReqChangeDataValue_0:0, UclProxyCddPowerSystemStateReqChangeDataValue_1:0]}
  swc implementation IMPL_UclProxyCdd: programming-language=C, behavior=IB_UclProxyCdd
    code-descriptors:
      code CodeDescriptor
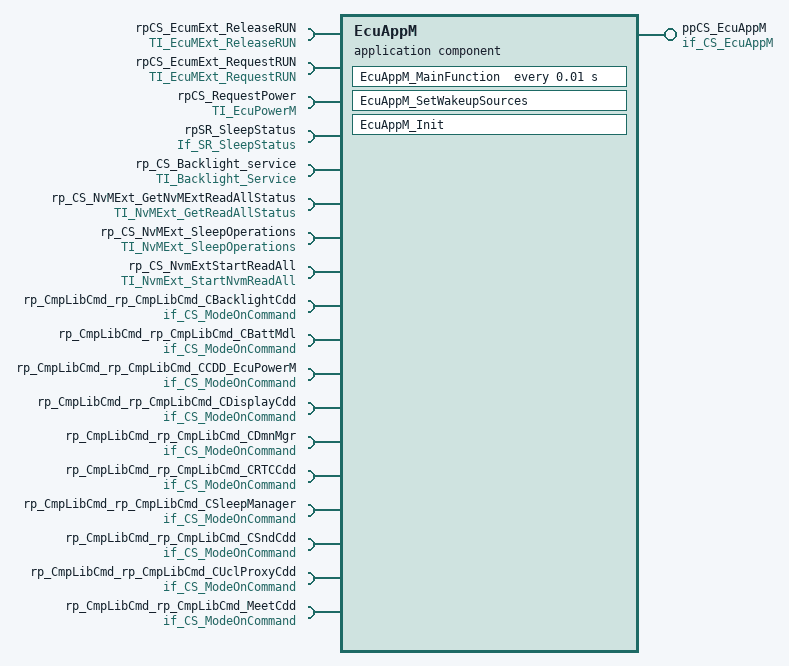
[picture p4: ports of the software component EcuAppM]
  application sw component type EcuAppM
    provide port ppCS_EcuAppM: provided-com-specs=[{operation=EcuAppM_SetWakeupSources, queue-length=1}, {operation=Init, queue-length=1}], provided-interface=if_CS_EcuAppM
    18 x require port:
      rpCS_EcumExt_ReleaseRUN: required-interface=TI_EcuMExt_ReleaseRUN
      rpCS_EcumExt_RequestRUN: required-interface=TI_EcuMExt_RequestRUN
      rpCS_RequestPower: required-interface=TI_EcuPowerM
      rpSR_SleepStatus: nonqueued-receiver-com-spec{data-element=SleepManager_SleepStatus, init-value=constant-reference=EcuAppMSleepManager_SleepStatusValue0}, required-interface=If_SR_SleepStatus
      rp_CS_Backlight_service: required-interface=TI_Backlight_Service
      rp_CS_NvMExt_GetNvMExtReadAllStatus: required-interface=TI_NvMExt_GetReadAllStatus
      rp_CS_NvMExt_SleepOperations: required-interface=TI_NvMExt_SleepOperations
      rp_CS_NvmExtStartReadAll: required-interface=TI_NvmExt_StartNvmReadAll
      rp_CmpLibCmd_rp_CmpLibCmd_CBacklightCdd: required-interface=if_CS_ModeOnCommand
      rp_CmpLibCmd_rp_CmpLibCmd_CBattMdl: required-interface=if_CS_ModeOnCommand
      rp_CmpLibCmd_rp_CmpLibCmd_CCDD_EcuPowerM: required-interface=if_CS_ModeOnCommand
      rp_CmpLibCmd_rp_CmpLibCmd_CDisplayCdd: required-interface=if_CS_ModeOnCommand
      rp_CmpLibCmd_rp_CmpLibCmd_CDmnMgr: required-interface=if_CS_ModeOnCommand
      rp_CmpLibCmd_rp_CmpLibCmd_CRTCCdd: required-interface=if_CS_ModeOnCommand
      rp_CmpLibCmd_rp_CmpLibCmd_CSleepManager: required-interface=if_CS_ModeOnCommand
      rp_CmpLibCmd_rp_CmpLibCmd_CSndCdd: required-interface=if_CS_ModeOnCommand
      rp_CmpLibCmd_rp_CmpLibCmd_CUclProxyCdd: required-interface=if_CS_ModeOnCommand
      rp_CmpLibCmd_rp_CmpLibCmd_MeetCdd: required-interface=if_CS_ModeOnCommand
    behavior IB_EcuAppM
      operation invoked event OIE_ppCS_EcuAppM_EcuAppM_SetWakeupSourcesTrigByEcuAppM_SetWakeupSources: start-on-event=EcuAppM_SetWakeupSources, operation=ppCS_EcuAppM.EcuAppM_SetWakeupSources
      operation invoked event OIE_ppCS_EcuAppM_EcuAppM_InitTrigByInit: start-on-event=EcuAppM_Init, operation=ppCS_EcuAppM.Init
      timing event TEEcuAppM_MainFunction: start-on-event=EcuAppM_MainFunction, period=0.01
      port-api-options:
        enable-take-address=false, indirect-api=false, port=ppCS_EcuAppM
        enable-take-address=false, indirect-api=false, port=rpCS_EcumExt_ReleaseRUN
        enable-take-address=false, indirect-api=false, port=rpCS_EcumExt_RequestRUN
        enable-take-address=false, indirect-api=false, port=rpCS_RequestPower
        enable-take-address=false, indirect-api=false, port=EcuAppM/rpSR_SleepStatus
        enable-take-address=false, indirect-api=false, port=rp_CS_Backlight_service
        enable-take-address=false, indirect-api=false, port=rp_CS_NvMExt_GetNvMExtReadAllStatus
        enable-take-address=false, indirect-api=false, port=rp_CS_NvMExt_SleepOperations
        enable-take-address=false, indirect-api=false, port=rp_CS_NvmExtStartReadAll
        enable-take-address=false, indirect-api=false, port=rp_CmpLibCmd_rp_CmpLibCmd_CBacklightCdd
        enable-take-address=false, indirect-api=false, port=rp_CmpLibCmd_rp_CmpLibCmd_CBattMdl
        enable-take-address=false, indirect-api=false, port=rp_CmpLibCmd_rp_CmpLibCmd_CCDD_EcuPowerM
        enable-take-address=false, indirect-api=false, port=rp_CmpLibCmd_rp_CmpLibCmd_CDisplayCdd
        enable-take-address=false, indirect-api=false, port=rp_CmpLibCmd_rp_CmpLibCmd_CDmnMgr
        enable-take-address=false, indirect-api=false, port=rp_CmpLibCmd_rp_CmpLibCmd_CRTCCdd
        enable-take-address=false, indirect-api=false, port=rp_CmpLibCmd_rp_CmpLibCmd_CSleepManager
        enable-take-address=false, indirect-api=false, port=rp_CmpLibCmd_rp_CmpLibCmd_CSndCdd
        enable-take-address=false, indirect-api=false, port=rp_CmpLibCmd_rp_CmpLibCmd_CUclProxyCdd
        enable-take-address=false, indirect-api=false, port=rp_CmpLibCmd_rp_CmpLibCmd_MeetCdd
      runnable EcuAppM_SetWakeupSources: can-be-invoked-concurrently=true
        data-receive-point-by-arguments:
          access DRA_rpSR_SleepStatus_SleepManager_SleepStatus: accessed-variable=rpSR_SleepStatus.SleepManager_SleepStatus
        22 x sync call, all with timeout=0.0:
          OA_rpCS_EcumExt_ReleaseRUN_ReleaseRUN: operation=rpCS_EcumExt_ReleaseRUN.ReleaseRUN
          OA_rpCS_EcumExt_RequestRUN_RequestRUN: operation=rpCS_EcumExt_RequestRUN.RequestRUN
          OA_rpCS_RequestPower_EcuPowerM_RequestPower: operation=rpCS_RequestPower.EcuPowerM_RequestPower
          OA_rpCS_RequestPower_EcuPowerM_GetDeviceStatus: operation=rpCS_RequestPower.EcuPowerM_GetDeviceStatus
          OA_rp_CS_Backlight_service_SetBrightnessValue: operation=rp_CS_Backlight_service.SetBrightnessValue
          OA_rp_CS_Backlight_service_GetBrightnessValue: operation=rp_CS_Backlight_service.GetBrightnessValue
          OA_rp_CS_Backlight_service_GetThermalValue: operation=rp_CS_Backlight_service.GetThermalValue
          OA_rp_CS_NvMExt_GetNvMExtReadAllStatus_NvmExt_GetNvMReadAllStatus: operation=rp_CS_NvMExt_GetNvMExtReadAllStatus.NvmExt_GetNvMReadAllStatus
          OA_rp_CS_NvMExt_SleepOperations_NvMExt_ReadytoSleep: operation=rp_CS_NvMExt_SleepOperations.NvMExt_ReadytoSleep
          OA_rp_CS_NvMExt_SleepOperations_NvMExt_RequestSleep: operation=rp_CS_NvMExt_SleepOperations.NvMExt_RequestSleep
          OA_rp_CS_NvMExt_SleepOperations_NvMExt_CancelSleep: operation=rp_CS_NvMExt_SleepOperations.NvMExt_CancelSleep
          OA_rp_CS_NvmExtStartReadAll_NvMExt_ReadAll: operation=rp_CS_NvmExtStartReadAll.NvMExt_ReadAll
          OA_rp_CmpLibCmd_rp_CmpLibCmd_CBacklightCdd_Impl_OnCommand: operation=rp_CmpLibCmd_rp_CmpLibCmd_CBacklightCdd.Impl_OnCommand
          OA_rp_CmpLibCmd_rp_CmpLibCmd_CBattMdl_Impl_OnCommand: operation=rp_CmpLibCmd_rp_CmpLibCmd_CBattMdl.Impl_OnCommand
          OA_rp_CmpLibCmd_rp_CmpLibCmd_CCDD_EcuPowerM_Impl_OnCommand: operation=rp_CmpLibCmd_rp_CmpLibCmd_CCDD_EcuPowerM.Impl_OnCommand
          OA_rp_CmpLibCmd_rp_CmpLibCmd_CDisplayCdd_Impl_OnCommand: operation=rp_CmpLibCmd_rp_CmpLibCmd_CDisplayCdd.Impl_OnCommand
          OA_rp_CmpLibCmd_rp_CmpLibCmd_CDmnMgr_Impl_OnCommand: operation=rp_CmpLibCmd_rp_CmpLibCmd_CDmnMgr.Impl_OnCommand
          OA_rp_CmpLibCmd_rp_CmpLibCmd_CRTCCdd_Impl_OnCommand: operation=rp_CmpLibCmd_rp_CmpLibCmd_CRTCCdd.Impl_OnCommand
          OA_rp_CmpLibCmd_rp_CmpLibCmd_CSleepManager_Impl_OnCommand: operation=rp_CmpLibCmd_rp_CmpLibCmd_CSleepManager.Impl_OnCommand
          OA_rp_CmpLibCmd_rp_CmpLibCmd_CSndCdd_Impl_OnCommand: operation=rp_CmpLibCmd_rp_CmpLibCmd_CSndCdd.Impl_OnCommand
          OA_rp_CmpLibCmd_rp_CmpLibCmd_CUclProxyCdd_Impl_OnCommand: operation=rp_CmpLibCmd_rp_CmpLibCmd_CUclProxyCdd.Impl_OnCommand
          OA_rp_CmpLibCmd_rp_CmpLibCmd_MeetCdd_Impl_OnCommand: operation=rp_CmpLibCmd_rp_CmpLibCmd_MeetCdd.Impl_OnCommand
      runnable EcuAppM_Init: can-be-invoked-concurrently=true
        data-receive-point-by-arguments:
          access DRA_rpSR_SleepStatus_SleepManager_SleepStatus: accessed-variable=rpSR_SleepStatus.SleepManager_SleepStatus
        22 x sync call, all with timeout=0.0:
          OA_rpCS_EcumExt_ReleaseRUN_ReleaseRUN: operation=rpCS_EcumExt_ReleaseRUN.ReleaseRUN
          OA_rpCS_EcumExt_RequestRUN_RequestRUN: operation=rpCS_EcumExt_RequestRUN.RequestRUN
          OA_rpCS_RequestPower_EcuPowerM_RequestPower: operation=rpCS_RequestPower.EcuPowerM_RequestPower
          OA_rpCS_RequestPower_EcuPowerM_GetDeviceStatus: operation=rpCS_RequestPower.EcuPowerM_GetDeviceStatus
          OA_rp_CS_Backlight_service_SetBrightnessValue: operation=rp_CS_Backlight_service.SetBrightnessValue
          OA_rp_CS_Backlight_service_GetBrightnessValue: operation=rp_CS_Backlight_service.GetBrightnessValue
          OA_rp_CS_Backlight_service_GetThermalValue: operation=rp_CS_Backlight_service.GetThermalValue
          OA_rp_CS_NvMExt_GetNvMExtReadAllStatus_NvmExt_GetNvMReadAllStatus: operation=rp_CS_NvMExt_GetNvMExtReadAllStatus.NvmExt_GetNvMReadAllStatus
          OA_rp_CS_NvMExt_SleepOperations_NvMExt_ReadytoSleep: operation=rp_CS_NvMExt_SleepOperations.NvMExt_ReadytoSleep
          OA_rp_CS_NvMExt_SleepOperations_NvMExt_RequestSleep: operation=rp_CS_NvMExt_SleepOperations.NvMExt_RequestSleep
          OA_rp_CS_NvMExt_SleepOperations_NvMExt_CancelSleep: operation=rp_CS_NvMExt_SleepOperations.NvMExt_CancelSleep
          OA_rp_CS_NvmExtStartReadAll_NvMExt_ReadAll: operation=rp_CS_NvmExtStartReadAll.NvMExt_ReadAll
          OA_rp_CmpLibCmd_rp_CmpLibCmd_CBacklightCdd_Impl_OnCommand: operation=rp_CmpLibCmd_rp_CmpLibCmd_CBacklightCdd.Impl_OnCommand
          OA_rp_CmpLibCmd_rp_CmpLibCmd_CBattMdl_Impl_OnCommand: operation=rp_CmpLibCmd_rp_CmpLibCmd_CBattMdl.Impl_OnCommand
          OA_rp_CmpLibCmd_rp_CmpLibCmd_CCDD_EcuPowerM_Impl_OnCommand: operation=rp_CmpLibCmd_rp_CmpLibCmd_CCDD_EcuPowerM.Impl_OnCommand
          OA_rp_CmpLibCmd_rp_CmpLibCmd_CDisplayCdd_Impl_OnCommand: operation=rp_CmpLibCmd_rp_CmpLibCmd_CDisplayCdd.Impl_OnCommand
          OA_rp_CmpLibCmd_rp_CmpLibCmd_CDmnMgr_Impl_OnCommand: operation=rp_CmpLibCmd_rp_CmpLibCmd_CDmnMgr.Impl_OnCommand
          OA_rp_CmpLibCmd_rp_CmpLibCmd_CRTCCdd_Impl_OnCommand: operation=rp_CmpLibCmd_rp_CmpLibCmd_CRTCCdd.Impl_OnCommand
          OA_rp_CmpLibCmd_rp_CmpLibCmd_CSleepManager_Impl_OnCommand: operation=rp_CmpLibCmd_rp_CmpLibCmd_CSleepManager.Impl_OnCommand
          OA_rp_CmpLibCmd_rp_CmpLibCmd_CSndCdd_Impl_OnCommand: operation=rp_CmpLibCmd_rp_CmpLibCmd_CSndCdd.Impl_OnCommand
          OA_rp_CmpLibCmd_rp_CmpLibCmd_CUclProxyCdd_Impl_OnCommand: operation=rp_CmpLibCmd_rp_CmpLibCmd_CUclProxyCdd.Impl_OnCommand
          OA_rp_CmpLibCmd_rp_CmpLibCmd_MeetCdd_Impl_OnCommand: operation=rp_CmpLibCmd_rp_CmpLibCmd_MeetCdd.Impl_OnCommand
      runnable EcuAppM_MainFunction: can-be-invoked-concurrently=true
        data-receive-point-by-arguments:
          access DRA_rpSR_SleepStatus_SleepManager_SleepStatus: accessed-variable=rpSR_SleepStatus.SleepManager_SleepStatus
        22 x sync call, all with timeout=0.0:
          OA_rpCS_EcumExt_ReleaseRUN_ReleaseRUN: operation=rpCS_EcumExt_ReleaseRUN.ReleaseRUN
          OA_rpCS_EcumExt_RequestRUN_RequestRUN: operation=rpCS_EcumExt_RequestRUN.RequestRUN
          OA_rpCS_RequestPower_EcuPowerM_RequestPower: operation=rpCS_RequestPower.EcuPowerM_RequestPower
          OA_rpCS_RequestPower_EcuPowerM_GetDeviceStatus: operation=rpCS_RequestPower.EcuPowerM_GetDeviceStatus
          OA_rp_CS_Backlight_service_SetBrightnessValue: operation=rp_CS_Backlight_service.SetBrightnessValue
          OA_rp_CS_Backlight_service_GetBrightnessValue: operation=rp_CS_Backlight_service.GetBrightnessValue
          OA_rp_CS_Backlight_service_GetThermalValue: operation=rp_CS_Backlight_service.GetThermalValue
          OA_rp_CS_NvMExt_GetNvMExtReadAllStatus_NvmExt_GetNvMReadAllStatus: operation=rp_CS_NvMExt_GetNvMExtReadAllStatus.NvmExt_GetNvMReadAllStatus
          OA_rp_CS_NvMExt_SleepOperations_NvMExt_ReadytoSleep: operation=rp_CS_NvMExt_SleepOperations.NvMExt_ReadytoSleep
          OA_rp_CS_NvMExt_SleepOperations_NvMExt_RequestSleep: operation=rp_CS_NvMExt_SleepOperations.NvMExt_RequestSleep
          OA_rp_CS_NvMExt_SleepOperations_NvMExt_CancelSleep: operation=rp_CS_NvMExt_SleepOperations.NvMExt_CancelSleep
          OA_rp_CS_NvmExtStartReadAll_NvMExt_ReadAll: operation=rp_CS_NvmExtStartReadAll.NvMExt_ReadAll
          OA_rp_CmpLibCmd_rp_CmpLibCmd_CBacklightCdd_Impl_OnCommand: operation=rp_CmpLibCmd_rp_CmpLibCmd_CBacklightCdd.Impl_OnCommand
          OA_rp_CmpLibCmd_rp_CmpLibCmd_CBattMdl_Impl_OnCommand: operation=rp_CmpLibCmd_rp_CmpLibCmd_CBattMdl.Impl_OnCommand
          OA_rp_CmpLibCmd_rp_CmpLibCmd_CCDD_EcuPowerM_Impl_OnCommand: operation=rp_CmpLibCmd_rp_CmpLibCmd_CCDD_EcuPowerM.Impl_OnCommand
          OA_rp_CmpLibCmd_rp_CmpLibCmd_CDisplayCdd_Impl_OnCommand: operation=rp_CmpLibCmd_rp_CmpLibCmd_CDisplayCdd.Impl_OnCommand
          OA_rp_CmpLibCmd_rp_CmpLibCmd_CDmnMgr_Impl_OnCommand: operation=rp_CmpLibCmd_rp_CmpLibCmd_CDmnMgr.Impl_OnCommand
          OA_rp_CmpLibCmd_rp_CmpLibCmd_CRTCCdd_Impl_OnCommand: operation=rp_CmpLibCmd_rp_CmpLibCmd_CRTCCdd.Impl_OnCommand
          OA_rp_CmpLibCmd_rp_CmpLibCmd_CSleepManager_Impl_OnCommand: operation=rp_CmpLibCmd_rp_CmpLibCmd_CSleepManager.Impl_OnCommand
          OA_rp_CmpLibCmd_rp_CmpLibCmd_CSndCdd_Impl_OnCommand: operation=rp_CmpLibCmd_rp_CmpLibCmd_CSndCdd.Impl_OnCommand
          OA_rp_CmpLibCmd_rp_CmpLibCmd_CUclProxyCdd_Impl_OnCommand: operation=rp_CmpLibCmd_rp_CmpLibCmd_CUclProxyCdd.Impl_OnCommand
          OA_rp_CmpLibCmd_rp_CmpLibCmd_MeetCdd_Impl_OnCommand: operation=rp_CmpLibCmd_rp_CmpLibCmd_MeetCdd.Impl_OnCommand
  constant specification EcuAppMSleepManager_SleepStatusValue0: value-spec=EcuAppMSleepManager_SleepStatusValue0:0
  swc implementation IMPL_EcuAppM: programming-language=C, behavior=IB_EcuAppM
    code-descriptors:
      code CodeDescriptor
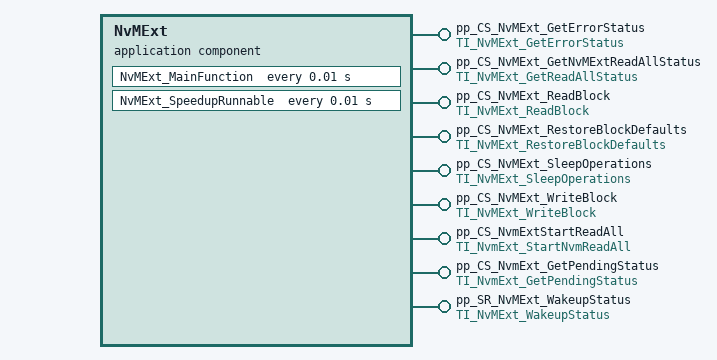
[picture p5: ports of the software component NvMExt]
  application sw component type NvMExt
    9 x provide port:
      pp_CS_NvMExt_GetErrorStatus: server-com-spec{operation=NvMExt_GetErrorStatus, queue-length=1}, provided-interface=TI_NvMExt_GetErrorStatus
      pp_CS_NvMExt_GetNvMExtReadAllStatus: server-com-spec{operation=NvmExt_GetNvMReadAllStatus, queue-length=1}, provided-interface=TI_NvMExt_GetReadAllStatus
      pp_CS_NvMExt_ReadBlock: server-com-spec{operation=NvMExt_ReadBlock, queue-length=1}, provided-interface=TI_NvMExt_ReadBlock
      pp_CS_NvMExt_RestoreBlockDefaults: server-com-spec{operation=NvMExt_RestoreBlockDefaults, queue-length=1}, provided-interface=TI_NvMExt_RestoreBlockDefaults
      pp_CS_NvMExt_SleepOperations: provided-interface=TI_NvMExt_SleepOperations
        provided-com-specs:
          operation=NvMExt_CancelSleep, queue-length=1
          operation=NvMExt_ReadytoSleep, queue-length=1
          operation=NvMExt_RequestSleep, queue-length=1
      pp_CS_NvMExt_WriteBlock: server-com-spec{operation=NvMExt_WriteBlock, queue-length=1}, provided-interface=TI_NvMExt_WriteBlock
      pp_CS_NvmExtStartReadAll: server-com-spec{operation=NvMExt_ReadAll, queue-length=1}, provided-interface=TI_NvmExt_StartNvmReadAll
      pp_CS_NvmExt_GetPendingStatus: server-com-spec{operation=NvMExt_GetPendingStatus, queue-length=1}, provided-interface=TI_NvmExt_GetPendingStatus
      pp_SR_NvMExt_WakeupStatus: nonqueued-sender-com-spec{data-element=WakeupFlag, uses-end-to-end-protection=0, init-value=constant-reference=NvMExtWakeupFlagValue0}, provided-interface=TI_NvMExt_WakeupStatus
    behavior IB_NvMExt
      timing event TENvMExt_MainFunction: start-on-event=NvMExt_MainFunction, period=0.01
      10 x operation invoked event:
        OIE_pp_CS_NvMExt_SleepOperations_NvMExt_CancelSleepTrigByNvMExt_CancelSleep: start-on-event=NvMExt_CancelSleep, operation=pp_CS_NvMExt_SleepOperations.NvMExt_CancelSleep
        OIE_pp_CS_NvMExt_GetErrorStatus_NvMExt_GetErrorStatusTrigByNvMExt_GetErrorStatus: start-on-event=NvMExt_GetErrorStatus, operation=pp_CS_NvMExt_GetErrorStatus.NvMExt_GetErrorStatus
        OIE_pp_CS_NvmExt_GetPendingStatus_NvMExt_GetPendingStatusTrigByNvMExt_GetPendingStatus: start-on-event=NvMExt_GetPendingStatus, operation=pp_CS_NvmExt_GetPendingStatus.NvMExt_GetPendingStatus
        OIE_pp_CS_NvmExtStartReadAll_NvMExt_ReadAllTrigByNvMExt_ReadAll: start-on-event=NvMExt_ReadAll, operation=pp_CS_NvmExtStartReadAll.NvMExt_ReadAll
        OIE_pp_CS_NvMExt_ReadBlock_NvMExt_ReadBlockTrigByNvMExt_ReadBlock: start-on-event=NvMExt_ReadBlock, operation=pp_CS_NvMExt_ReadBlock.NvMExt_ReadBlock
        OIE_pp_CS_NvMExt_SleepOperations_NvMExt_ReadytoSleepTrigByNvMExt_ReadytoSleep: start-on-event=NvMExt_ReadytoSleep, operation=pp_CS_NvMExt_SleepOperations.NvMExt_ReadytoSleep
        OIE_pp_CS_NvMExt_SleepOperations_NvMExt_RequestSleepTrigByNvMExt_RequestSleep: start-on-event=NvMExt_RequestSleep, operation=pp_CS_NvMExt_SleepOperations.NvMExt_RequestSleep
        OIE_pp_CS_NvMExt_RestoreBlockDefaults_NvMExt_RestoreBlockDefaultsTrigByNvMExt_RestoreBlockDefaults: start-on-event=NvMExt_RestoreBlockDefaults, operation=pp_CS_NvMExt_RestoreBlockDefaults.NvMExt_RestoreBlockDefaults
        OIE_pp_CS_NvMExt_WriteBlock_NvMExt_WriteBlockTrigByNvMExt_WriteBlock: start-on-event=NvMExt_WriteBlock, operation=pp_CS_NvMExt_WriteBlock.NvMExt_WriteBlock
        OIE_pp_CS_NvMExt_GetNvMExtReadAllStatus_NvmExt_GetNvMReadAllStatusTrigByNvmExt_GetNvMReadAllStatus: start-on-event=NvmExt_GetNvMReadAllStatus, operation=pp_CS_NvMExt_GetNvMExtReadAllStatus.NvmExt_GetNvMReadAllStatus
      timing event TENvMExt_SpeedupRunnable: start-on-event=NvMExt_SpeedupRunnable, period=0.01
      port-api-options:
        enable-take-address=false, indirect-api=false, port=pp_CS_NvMExt_GetErrorStatus
        enable-take-address=false, indirect-api=false, port=pp_CS_NvMExt_GetNvMExtReadAllStatus
        enable-take-address=false, indirect-api=false, port=pp_CS_NvMExt_ReadBlock
        enable-take-address=false, indirect-api=false, port=pp_CS_NvMExt_RestoreBlockDefaults
        enable-take-address=false, indirect-api=false, port=pp_CS_NvMExt_SleepOperations
        enable-take-address=false, indirect-api=false, port=pp_CS_NvMExt_WriteBlock
        enable-take-address=false, indirect-api=false, port=pp_CS_NvmExtStartReadAll
        enable-take-address=false, indirect-api=false, port=pp_CS_NvmExt_GetPendingStatus
        enable-take-address=false, indirect-api=false, port=pp_SR_NvMExt_WakeupStatus
      12 x runnable, all with can-be-invoked-concurrently=true:
        NvMExt_MainFunction
          data-send-points:
            access DWA_pp_SR_NvMExt_WakeupStatus_WakeupFlag: accessed-variable=pp_SR_NvMExt_WakeupStatus.WakeupFlag
        NvMExt_CancelSleep
        NvMExt_GetErrorStatus
          data-send-points:
            access DWA_pp_SR_NvMExt_WakeupStatus_WakeupFlag: accessed-variable=pp_SR_NvMExt_WakeupStatus.WakeupFlag
        NvMExt_GetPendingStatus
        NvMExt_ReadAll
        NvMExt_ReadBlock
          data-send-points:
            access DWA_pp_SR_NvMExt_WakeupStatus_WakeupFlag: accessed-variable=pp_SR_NvMExt_WakeupStatus.WakeupFlag
        NvMExt_ReadytoSleep
        NvMExt_RequestSleep
        NvMExt_RestoreBlockDefaults
          data-send-points:
            access DWA_pp_SR_NvMExt_WakeupStatus_WakeupFlag: accessed-variable=pp_SR_NvMExt_WakeupStatus.WakeupFlag
        NvMExt_WriteBlock
          data-send-points:
            access DWA_pp_SR_NvMExt_WakeupStatus_WakeupFlag: accessed-variable=pp_SR_NvMExt_WakeupStatus.WakeupFlag
        NvmExt_GetNvMReadAllStatus
        NvMExt_SpeedupRunnable
  constant specification NvMExtWakeupFlagValue0: value-spec=NvMExtWakeupFlagValue0:false
  swc implementation IMPL_NvMExt: programming-language=C, behavior=IB_NvMExt
    code-descriptors:
      code CodeDescriptor
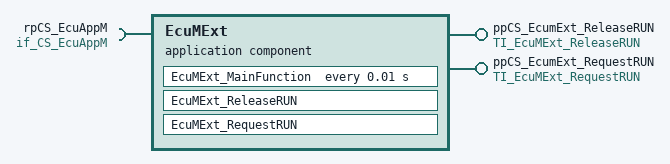
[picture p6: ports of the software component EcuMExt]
  application sw component type EcuMExt
    provide port ppCS_EcumExt_ReleaseRUN: server-com-spec{operation=ReleaseRUN, queue-length=1}, provided-interface=TI_EcuMExt_ReleaseRUN
    provide port ppCS_EcumExt_RequestRUN: server-com-spec{operation=RequestRUN, queue-length=1}, provided-interface=TI_EcuMExt_RequestRUN
    require port rpCS_EcuAppM: required-interface=if_CS_EcuAppM
    behavior IB_EcuMExt
      timing event TEEcuMExt_MainFunction: start-on-event=EcuMExt_MainFunction, period=0.01
      operation invoked event OIE_ppCS_EcumExt_ReleaseRUN_EcuMExt_ReleaseRUNTrigByReleaseRUN: start-on-event=EcuMExt_ReleaseRUN, operation=ppCS_EcumExt_ReleaseRUN.ReleaseRUN
      operation invoked event OIE_ppCS_EcumExt_RequestRUN_EcuMExt_RequestRUNTrigByRequestRUN: start-on-event=EcuMExt_RequestRUN, operation=ppCS_EcumExt_RequestRUN.RequestRUN
      port-api-options:
        enable-take-address=false, indirect-api=false, port=ppCS_EcumExt_ReleaseRUN
        enable-take-address=false, indirect-api=false, port=ppCS_EcumExt_RequestRUN
        enable-take-address=false, indirect-api=false, port=rpCS_EcuAppM
      runnable EcuMExt_MainFunction: can-be-invoked-concurrently=true
        sync call OA_rpCS_EcuAppM_Init: operation=rpCS_EcuAppM.Init, timeout=0.0
        sync call OA_rpCS_EcuAppM_EcuAppM_SetWakeupSources: operation=rpCS_EcuAppM.EcuAppM_SetWakeupSources, timeout=0.0
      runnable EcuMExt_ReleaseRUN: can-be-invoked-concurrently=true
        sync call OA_rpCS_EcuAppM_Init: operation=rpCS_EcuAppM.Init, timeout=0.0
        sync call OA_rpCS_EcuAppM_EcuAppM_SetWakeupSources: operation=rpCS_EcuAppM.EcuAppM_SetWakeupSources, timeout=0.0
      runnable EcuMExt_RequestRUN: can-be-invoked-concurrently=true
        sync call OA_rpCS_EcuAppM_Init: operation=rpCS_EcuAppM.Init, timeout=0.0
        sync call OA_rpCS_EcuAppM_EcuAppM_SetWakeupSources: operation=rpCS_EcuAppM.EcuAppM_SetWakeupSources, timeout=0.0
  swc implementation IMPL_EcuMExt: programming-language=C, behavior=IB_EcuMExt
    code-descriptors:
      code CodeDescriptor
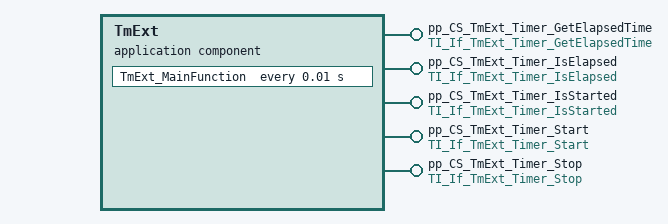
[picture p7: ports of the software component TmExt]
  application sw component type TmExt
    5 x provide port:
      pp_CS_TmExt_Timer_GetElapsedTime: server-com-spec{operation=Timer_GetElapsedTime, queue-length=1}, provided-interface=TI_If_TmExt_Timer_GetElapsedTime
      pp_CS_TmExt_Timer_IsElapsed: server-com-spec{operation=Timer_IsElapsed, queue-length=1}, provided-interface=TI_If_TmExt_Timer_IsElapsed
      pp_CS_TmExt_Timer_IsStarted: server-com-spec{operation=Timer_IsStarted, queue-length=1}, provided-interface=TI_If_TmExt_Timer_IsStarted
      pp_CS_TmExt_Timer_Start: server-com-spec{operation=Timer_Start, queue-length=1}, provided-interface=TI_If_TmExt_Timer_Start
      pp_CS_TmExt_Timer_Stop: server-com-spec{operation=Timer_Stop, queue-length=1}, provided-interface=TI_If_TmExt_Timer_Stop
    behavior IB_TmExt
      timing event TETmExt_MainFunction: start-on-event=TmExt_MainFunction, period=0.01
      5 x operation invoked event:
        OIE_pp_CS_TmExt_Timer_GetElapsedTime_TmExt_Timer_GetElapsedTimeTrigByTimer_GetElapsedTime: start-on-event=TmExt_Timer_GetElapsedTime, operation=pp_CS_TmExt_Timer_GetElapsedTime.Timer_GetElapsedTime
        OIE_pp_CS_TmExt_Timer_IsElapsed_TmExt_Timer_IsElapsedTrigByTimer_IsElapsed: start-on-event=TmExt_Timer_IsElapsed, operation=pp_CS_TmExt_Timer_IsElapsed.Timer_IsElapsed
        OIE_pp_CS_TmExt_Timer_IsStarted_TmExt_Timer_IsStartedTrigByTimer_IsStarted: start-on-event=TmExt_Timer_IsStarted, operation=pp_CS_TmExt_Timer_IsStarted.Timer_IsStarted
        OIE_pp_CS_TmExt_Timer_Start_TmExt_Timer_StartTrigByTimer_Start: start-on-event=TmExt_Timer_Start, operation=pp_CS_TmExt_Timer_Start.Timer_Start
        OIE_pp_CS_TmExt_Timer_Stop_TmExt_Timer_StopTrigByTimer_Stop: start-on-event=TmExt_Timer_Stop, operation=pp_CS_TmExt_Timer_Stop.Timer_Stop
      port-api-options:
        enable-take-address=false, indirect-api=false, port=pp_CS_TmExt_Timer_GetElapsedTime
        enable-take-address=false, indirect-api=false, port=pp_CS_TmExt_Timer_IsElapsed
        enable-take-address=false, indirect-api=false, port=pp_CS_TmExt_Timer_IsStarted
        enable-take-address=false, indirect-api=false, port=pp_CS_TmExt_Timer_Start
        enable-take-address=false, indirect-api=false, port=pp_CS_TmExt_Timer_Stop
      6 x runnable, all with can-be-invoked-concurrently=true:
        TmExt_MainFunction
        TmExt_Timer_GetElapsedTime
        TmExt_Timer_IsElapsed
        TmExt_Timer_IsStarted
        TmExt_Timer_Start
        TmExt_Timer_Stop
  swc implementation IMPL_TmExt: programming-language=C, behavior=IB_TmExt
    code-descriptors:
      code CodeDescriptor
package /E40_Platform_System_SystemPackage/Compositions
  composition sw component type E40_Platform_System
    18 x component:
      CBacklightCdd: type=CBacklightCdd
      CBattMdl: type=CBattMdl
      CCDD_EcuPowerM: type=CCDD_EcuPowerM
      CDisplayCdd: type=CDisplayCdd
      CMeetCdd: type=CMeetCdd
      RtcCdd: type=RtcCdd
      CSleepManager: type=CSleepManager
      CSndCdd: type=CSndCdd
      DcmExt: type=DcmExt
      DemExt: type=DemExt
      DmnMgr: type=DmnMgr
      EcuAppM: type=EcuAppM
      EcuMExt: type=EcuMExt
      IoHwAb: type=IoHwAb
      MemAbstractMdl: type=MemAbstractMdl
      NvMExt: type=NvMExt
      TmExt: type=TmExt
      UclProxyCdd: type=UclProxyCdd
    connect IoHwAb.ppIoHwAb_Din -> CBacklightCdd.rpIoHwAb_Din
    connect IoHwAb.ppIoHwAb_DOut -> CBacklightCdd.rpIoHwAb_DOut
    connect IoHwAb.ppIoHwAb_PWM -> CBacklightCdd.rpIoHwAb_PWM
    connect IoHwAb.ppIoHwAb_Din -> CBattMdl.rpIoHwAb_Din
    connect IoHwAb.ppIoHwAb_DOut -> CBattMdl.rpIoHwAb_DOut
    connect IoHwAb.ppIoHwAb_ADC -> CBattMdl.rpIoHwAb_ADC
    connect IoHwAb.ppIoHwAb_Din -> CCDD_EcuPowerM.rpIoHwAb_Din
    connect IoHwAb.ppIoHwAb_DOut -> CCDD_EcuPowerM.rpIoHwAb_DOut
    connect IoHwAb.ppIoHwAb_PWM -> CCDD_EcuPowerM.rpIoHwAb_PWM
    connect IoHwAb.ppIoHwAb_ADC -> CCDD_EcuPowerM.rpIoHwAb_ADC
    connect CBacklightCdd.pp_CS_Backlight_Status -> CDisplayCdd.rp_CS_Backlight_Status
    connect CBacklightCdd.pp_CS_Backlight_Notify -> CDisplayCdd.rp_CS_Backlight_Notify
    connect IoHwAb.ppIoHwAb_DOut -> CDisplayCdd.rpIoHwAb_SetDout
    connect IoHwAb.ppIoHwAb_ADC -> CMeetCdd.rpIoHwAb_ADC
    connect IoHwAb.ppIoHwAb_Din -> CMeetCdd.rpIoHwAb_Din
    connect IoHwAb.ppIoHwAb_DOut -> CMeetCdd.rpIoHwAb_DOut
    connect IoHwAb.ppIoHwAb_PWM -> CMeetCdd.rpIoHwAb_PWM
    connect MemAbstractMdl.pp_CS_MemAbsGet -> CMeetCdd.rp_CS_MemAbsGet
    connect MemAbstractMdl.pp_CS_MemAbsSet -> CMeetCdd.rp_CS_MemAbsSet
    connect MemAbstractMdl.pp_SR_JobStatus -> CMeetCdd.rp_SR_JobStatus
    connect IoHwAb.ppIoHwAb_ADC -> RtcCdd.rp_CS_IoHwAb_ADC
    connect IoHwAb.ppIoHwAb_Din -> RtcCdd.rp_IoHwAb_Din
    connect IoHwAb.ppIoHwAb_DOut -> RtcCdd.rp_IoHwAb_DOut
    connect DmnMgr.ppCS_UclSystemCallbacks -> UclProxyCdd.rCS_UclSystemCallbacks
    connect DmnMgr.pSR_HealthDumpGetHdr -> UclProxyCdd.rSR_HealthDumpGetHdr
    connect DmnMgr.pSR_HealthDumpGetData -> UclProxyCdd.rSR_HealthDumpGetData
    connect DmnMgr.pSR_PowerSystemStateReqChange -> UclProxyCdd.rSR_PowerSystemStateReqChange
    connect UclProxyCdd.pSR_HealthDomainFatalError -> DmnMgr.rSR_HealthDomainFatalError
    connect UclProxyCdd.pSR_HealthDomainHeartbeat -> DmnMgr.rSR_HealthDomainHeartbeat
    connect UclProxyCdd.pSR_HealthDumpData -> DmnMgr.rSR_HealthDumpData
    connect UclProxyCdd.pSR_HealthDumpHdrInfo -> DmnMgr.rSR_HealthDumpHdrInfo
    connect UclProxyCdd.pSR_PowerExtendShutdownTime -> DmnMgr.rSR_PowerExtendShutdownTime
    connect UclProxyCdd.pSR_PowerKeepSystemAwake -> DmnMgr.rSR_PowerKeepSystemAwake
    connect UclProxyCdd.pSR_PowerSystemState -> DmnMgr.rSR_PowerSystemState
    connect UclProxyCdd.ppCS_UclInitShutdown -> DmnMgr.rpCS_UclInitShutdown
    connect DmnMgr.ppSR_DmnInfo -> DmnMgr.rpSR_DmnInfo
    connect CSleepManager.ppSR_SleepStatus -> DmnMgr.rpSR_SleepStatus
    connect CBacklightCdd.pp_CmpLibCmd_CBacklightCdd -> EcuAppM.rp_CmpLibCmd_rp_CmpLibCmd_CBacklightCdd
    connect CBattMdl.pp_CmpLibCmd_CBattMdl -> EcuAppM.rp_CmpLibCmd_rp_CmpLibCmd_CBattMdl
    connect CCDD_EcuPowerM.pp_CmpLibCmd -> EcuAppM.rp_CmpLibCmd_rp_CmpLibCmd_CCDD_EcuPowerM
    connect CDisplayCdd.pp_CmpLibCmd_CDisplayCdd -> EcuAppM.rp_CmpLibCmd_rp_CmpLibCmd_CDisplayCdd
    connect DmnMgr.pp_CmpLibCmd_CDmnMgr -> EcuAppM.rp_CmpLibCmd_rp_CmpLibCmd_CDmnMgr
    connect RtcCdd.pp_CmpLibCmd_CRTCCdd -> EcuAppM.rp_CmpLibCmd_rp_CmpLibCmd_CRTCCdd
    connect CSleepManager.pp_CmpLibCmd -> EcuAppM.rp_CmpLibCmd_rp_CmpLibCmd_CSleepManager
    connect CSndCdd.pp_CmpLibCmd_CSndCdd -> EcuAppM.rp_CmpLibCmd_rp_CmpLibCmd_CSndCdd
    connect UclProxyCdd.pp_CmpLibCmd_CUclProxyCdd -> EcuAppM.rp_CmpLibCmd_rp_CmpLibCmd_CUclProxyCdd
    connect CMeetCdd.pp_CmpLibCmd_MeetCdd -> EcuAppM.rp_CmpLibCmd_rp_CmpLibCmd_MeetCdd
    connect CBacklightCdd.pp_CS_Backlight_service -> EcuAppM.rp_CS_Backlight_service
    connect CSleepManager.ppSR_SleepStatus -> EcuAppM.rpSR_SleepStatus
    connect CCDD_EcuPowerM.ppCS_RequestPower -> EcuAppM.rpCS_RequestPower
    connect NvMExt.pp_CS_NvmExtStartReadAll -> EcuAppM.rp_CS_NvmExtStartReadAll
    connect NvMExt.pp_CS_NvMExt_SleepOperations -> EcuAppM.rp_CS_NvMExt_SleepOperations
    connect NvMExt.pp_CS_NvMExt_GetNvMExtReadAllStatus -> EcuAppM.rp_CS_NvMExt_GetNvMExtReadAllStatus
    connect EcuAppM.ppCS_EcuAppM -> EcuMExt.rpCS_EcuAppM
    connect EcuMExt.ppCS_EcumExt_ReleaseRUN -> EcuAppM.rpCS_EcumExt_ReleaseRUN
    connect EcuMExt.ppCS_EcumExt_RequestRUN -> EcuAppM.rpCS_EcumExt_RequestRUN
package /E40_Platform_System_SystemPackage/Types
  impl type EDisplayType: category=VALUE, base-type=uint8, compu {0=e_Display10Inch, 1=e_DisplayMaxDevice}, range raw 0..1
  impl type EDisplayPowerState: category=VALUE, base-type=uint8, compu {0=eDisplayIdle, 1=eDisplayPowerON, 2=eDisplayNormal, 3=eDisplayPowerOFF, 4=eDisplayFault_Handle, 5=eDisplayMaxPowerState}, range raw 0..5
  client server interface TI_Backlight_NotifyDispaly
    operation NotifyDisplayPowerState: possible-error=TI_Backlight_NotifyDispaly/E_NOT_OK
      arg DeviceId: implementation-data-type=EDisplayType, type=EDisplayType, direction=IN
      arg CompletedPowerState: implementation-data-type=EDisplayPowerState, type=EDisplayPowerState, direction=IN
    error E_NOT_OK: error-code=1
  impl type EDeviceStatus: category=VALUE, base-type=uint8, compu {0=eDeviceNotReady, 1=eDeviceInitialized, 2=eDeviceReady, 3=eDeviceBusy, 4=eDeviceFault, 5=eDeviceMaxState}, range raw 0..5
  client server interface TI_Backlight_Status
    operation GetStatus: possible-error=TI_Backlight_Status/E_NOT_OK
      arg DeviceName: implementation-data-type=EDisplayType, type=EDisplayType, direction=IN
      arg DeviceStatus: implementation-data-type=EDeviceStatus, type=EDeviceStatus, direction=OUT
    error E_NOT_OK: error-code=1
  client server interface TI_Backlight_Service
    operation GetBrightnessValue: possible-error=TI_Backlight_Service/E_NOT_OK
      arg DeviceName: implementation-data-type=EDisplayType, type=EDisplayType, direction=IN
      arg BrightnessPercentValue: implementation-data-type=UInt16, type=UInt16, direction=OUT
    operation GetThermalValue: possible-error=TI_Backlight_Service/E_NOT_OK
      arg DeviceName: implementation-data-type=EDisplayType, type=EDisplayType, direction=IN
      arg TempValueInMilliCelsius: implementation-data-type=UInt32, type=UInt32, direction=OUT
    operation SetBrightnessValue: possible-error=TI_Backlight_Service/E_NOT_OK
      arg DeviceName: implementation-data-type=EDisplayType, type=EDisplayType, direction=IN
      arg BrightnessPercentValue: implementation-data-type=UInt16, type=UInt16, direction=IN
    error E_NOT_OK: error-code=1
  impl type ECmpCmd: category=VALUE, base-type=uint8, compu {0=eCmpCmd_Init, 1=eCmpCmd_DeInit, 2=eCmpCmd_Activate, 3=eCmpCmd_DeActivate}, range raw 0..3
  client server interface if_CS_ModeOnCommand
    operation Impl_OnCommand: possible-error=if_CS_ModeOnCommand/E_NOT_OK
      arg cmdP: implementation-data-type=ECmpCmd, type=ECmpCmd, direction=IN
    error E_NOT_OK: error-code=1
  impl type IoHwAb_DOutGroupIdType: category=VALUE, base-type=sint32, compu {0=eIO_DOutGroupIdCount}, range raw -2147483647..2147483647
  impl type IoHwAb_ErrorType: category=VALUE, base-type=uint8, compu {2=E_NO_ERROR, 3=E_ERROR, 4=E_ADC_ERROR, 5=E_DOUT_ID_INVALID, 6=E_DIN_ID_INVALID, 7=E_ADC_ID_INVALID, 8=IOHWAB_E_ADC_ERROR, 9=IOHWAB_E_ADC_ID_INVALID, 10=IOHWAB_E_ERROR, 11=IOHWAB_E_DOUT_ID_INVALID, 12=IOHWAB_E_NO_ERROR, 13=IOHWAB_E_DIN_ID_INVALID}, range raw 2..13
  impl type IoHwAb_DOutSignalIdType:
    category=VALUE
    base-type=uint8
    compu {0=eIO_DOUT_DO_5VSW2_3V3_EN, 1=eIO_DOUT_PARK_BRAKE_TT_OUT, 2=eIO_DOUT_DO_SYC1, 3=eIO_DOUT_SEAT_BELT_TT_MCUOUT, 4=eIO_DOUT_TURN_LEFT_TT_MCUOUT, 5=eIO_DOUT_DO_LCD_BL_PWR_EN, 6=eIO_DOUT_DO_3V3_DISP_SW_EN, 7=eIO_DOUT_AMP_SHTD, 8=eIO_DOUT_FUEL_RHEO_SUP_EN, 9=eIO_DOUT_DO_LCD_STBYB, 10=eIO_DOUT_SBATT2_EN, 11=eIO_DOUT_BRAKE_TT_MCUOUT, 12=eIO_DOUT_AIRBAG_TT_MCUOUT, 13=eIO_DOUT_TURN_RIGHT_TT_MCUOUT, 14=eIO_DOUT_DO_SMPS_5V_SW_EN, 15=eIO_DOUT_PCS_OFF_TT_MCUOUT, 16=eIO_DOUT_ABS_TT_MCUOUT, 17=eIO_DOUT_SLIP_TT_MCUOUT, 18=eIO_DOUT_VCS_OFF_TT_MCUOUT, 19=eIO_DOUT_ECB_EPB_TT_MCUOUT, 20=eIO_DOUT_Flasher_FL_RL_OUT, 21=eIO_DOUT_Flasher_DEN1, 22=eIO_DOUT_Flasher_DSEL1, 23=eIO_DOUT_Flasher_FR_RR_OUT, 24=eIO_DOUT_DO_LCD_RST, 25=eIO_DOUT_DO_SMPS_1V2_EN, 26=eIO_DO_MAX, 27=eIO_DOUT_DO_DISP_RESET, 28=eIO_DOUT_DO_DISP_STBY, 29=eIO_DOUT_DO_TFT_BL_EN, 30=eIO_DOUT_DO_PWM_DIMMING, 31=eIO_DOUT_DO_RTC_INTN, 32=eIO_DOUT_DO_SOC_PWR_LATCH, 33=eIO_DOUT_DO_1V2_EN, 34=eIO_DOUT_DO_EN_5V, 35=eIO_DOUT_DO_ENET_EN, 36=eIO_DOUT_DO_LIN_NSLP, 37=eIO_DOUT_DO_MCU_CMIC_PHOLD, 38=eIO_DOUT_DO_MCU_CMIC_RES, 39=eIO_DOUT_DO_MD_SMPS_FALD_6V_EN, 40=eIO_DOUT_DO_MD_VPP_1V8_EN, 41=eIO_DOUT_DO_MD_TFT_RST, 42=eIO_DOUT_DO_MD_DISP_3V3_EN, 43=eIO_DOUT_DO_MD_TCON_GRBN, 44=eIO_DOUT_DO_MD_TFT_STBYB, 45=eIO_DOUT_DO_MD_TCON_STBN, 46=eIO_DOUT_DO_SOC_OSPI0_RSTN, 47=eIO_DOUT_DO_SOC_EMMC_RESET, 48=eIO_DOUT_DO_MD_GNSS_RESETP, 49=eIO_DOUT_DO_MD_GNSS_3V3_EN, 50=eIO_DOUT_DO_SOC_ETHPHY_RESETN}
    range raw 0..50
  client server interface TI_IOHWAB_SetDout
    operation SetOutputGroup: possible-error=TI_IOHWAB_SetDout/E_NOT_OK
      arg InputId: implementation-data-type=IoHwAb_DOutGroupIdType, type=IoHwAb_DOutGroupIdType, direction=IN
      arg OutputGroup: implementation-data-type=UInt32, type=UInt32, direction=IN
      arg ErrorStatus: implementation-data-type=IoHwAb_ErrorType, type=IoHwAb_ErrorType, direction=OUT
    operation SetOutputPin: possible-error=TI_IOHWAB_SetDout/E_NOT_OK
      arg InputId: implementation-data-type=IoHwAb_DOutSignalIdType, type=IoHwAb_DOutSignalIdType, direction=IN
      arg OutputSignal: implementation-data-type=Boolean, type=Boolean, direction=IN
      arg ErrorStatus: implementation-data-type=IoHwAb_ErrorType, type=IoHwAb_ErrorType, direction=OUT
    error E_NOT_OK: error-code=1
  impl type IoHwAb_DInSignalIdType:
    category=VALUE
    base-type=uint8
    compu {0=eIO_DIN_DI_AL_HAZARD, 1=eIO_DIN_DI_AH_IGNITION, 2=eIO_DIN_DI_SMPS_3V3_PG, 3=eIO_DIN_STOP_LAMP_MCU, 4=eIO_DIN_DI_AL_BRAKE_LEVEL, 5=eIO_DIN_DI_AL_OIL_W, 6=eIO_DIN_DI_AL_DRV_SEAT_BUCKLE, 7=eIO_DIN_DI_AL_WASHER_LEVEL_SW, 8=eIO_DIN_ODO_TripKnobInput, 9=eIO_DIN_DI_AL_VACUUM, 10=eIO_DIN_DI_LCD_BL_PWR_FAULT, 11=eIO_DIN_DI_AL_FUEL_LID_EFI_ECU, 12=eIO_DIN_DI_TT_SHIFT_ERR, 13=eIO_DIN_MAX, 14=eIO_DIN_DI_PMIC_INTN, 15=eIO_DIN_DI_MCU_PORZ, 16=eIO_DIN_DI_MCU_CMIC_PBSTATE, 17=eIO_DIN_DI_SOC_OSPI0_INTN, 18=eIO_DIN_DI_MD_FALD_SMPS_6V_PG, 19=eIO_DIN_DI_MD_TFT_FAILT, 20=eIO_DIN_DI_MD_ETHPHY_RXER, 21=eIO_DIN_DI_MD_TCON_IND_OUT, 22=eIO_DIN_DI_SOC_ETHPHY_RST_CHK, 23=eIO_DIN_DI_MCU_PMIC_INTN, 24=eIO_DIN_DI_MCU_FALD_CONN_CHK}
    range raw 0..24
  impl type IoHwAb_DInGroupIdType: category=VALUE, base-type=sint32, compu {0=eIO_DInGroupIdCount}, range raw -2147483647..2147483647
  client server interface TI_IOHWAB_GetDIn
    4 x operation, all with possible-error=TI_IOHWAB_GetDIn/E_NOT_OK:
      GetAsyncRawInput
        arg InputId: implementation-data-type=IoHwAb_DInSignalIdType, type=IoHwAb_DInSignalIdType, direction=IN
        arg AsyncInput: implementation-data-type=Boolean, type=Boolean, direction=OUT
        arg ErrorStatus: implementation-data-type=IoHwAb_ErrorType, type=IoHwAb_ErrorType, direction=OUT
      GetInputGroup
        arg InputId: implementation-data-type=IoHwAb_DInGroupIdType, type=IoHwAb_DInGroupIdType, direction=IN
        arg SyncInput: implementation-data-type=UInt32, type=UInt32, direction=OUT
        arg ErrorStatus: implementation-data-type=IoHwAb_ErrorType, type=IoHwAb_ErrorType, direction=OUT
      GetProcessedInput
        arg InputId: implementation-data-type=IoHwAb_DInSignalIdType, type=IoHwAb_DInSignalIdType, direction=IN
        arg InputSignal: implementation-data-type=Boolean, type=Boolean, direction=OUT
        arg ErrorStatus: implementation-data-type=IoHwAb_ErrorType, type=IoHwAb_ErrorType, direction=OUT
      GetSyncRawInput
        arg InputId: implementation-data-type=IoHwAb_DInSignalIdType, type=IoHwAb_DInSignalIdType, direction=IN
        arg SyncInput: implementation-data-type=Boolean, type=Boolean, direction=OUT
        arg ErrorStatus: implementation-data-type=IoHwAb_ErrorType, type=IoHwAb_ErrorType, direction=OUT
    error E_NOT_OK: error-code=1
  impl type IoHwAb_PwmSignalIdType: category=VALUE, base-type=uint8, compu {0=eIO_PWM_MCU_BUZZER_AMPLCTRL, 1=eIO_PWM_HIGH_BEAM_TT_MCUOUT, 2=eIO_PWM_FUEL_TEMP_GAUG_TEXT_PWM_OUT, 3=eIO_PWM_PWM_OUT_ILL2, 4=eIO_PWM_PWM_OUT_ILL1, 5=eIO_PWM_BG_Dimming_PWM, 6=eIO_PWM_PWM_GREEN_TT_DIMMING, 7=eIO_PWM_CXPI_CLK, 8=eIO_PWM_PWM_LCD_BL_DIMMING, 9=eIO_PWM_MAX}, range raw 0..9
  client server interface TI_IOHWAB_PWM
    operation PwmSetDuty: possible-error=TI_IOHWAB_PWM/E_NOT_OK
      arg PwmId: implementation-data-type=IoHwAb_PwmSignalIdType, type=IoHwAb_PwmSignalIdType, direction=IN
      arg Pwm_Duty: implementation-data-type=UInt16, type=UInt16, direction=IN
      arg ErrorStatus: implementation-data-type=IoHwAb_ErrorType, type=IoHwAb_ErrorType, direction=OUT
    operation PwmSetDutyAndPeriod: possible-error=TI_IOHWAB_PWM/E_NOT_OK
      4 x arg:
        PwmId: implementation-data-type=IoHwAb_PwmSignalIdType, type=IoHwAb_PwmSignalIdType, direction=IN
        Pwm_Period: implementation-data-type=UInt32, type=UInt32, direction=IN
        Pwm_Duty: implementation-data-type=UInt16, type=UInt16, direction=IN
        ErrorStatus: implementation-data-type=IoHwAb_ErrorType, type=IoHwAb_ErrorType, direction=OUT
    operation PwmSetIdeal: possible-error=TI_IOHWAB_PWM/E_NOT_OK
      arg PwmId: implementation-data-type=IoHwAb_PwmSignalIdType, type=IoHwAb_PwmSignalIdType, direction=IN
      arg ErrorStatus: implementation-data-type=IoHwAb_ErrorType, type=IoHwAb_ErrorType, direction=OUT
    error E_NOT_OK: error-code=1
  impl type IoHwAb_AdcSignalIdType:
    category=VALUE
    base-type=uint8
    compu {16=eIO_ADC_ADC_FUEL_5V_MON, 17=eIO_ADC_ADC_FUEL_MAIN, 2=eIO_ADC_IGN_AD, 3=eIO_ADC_FUEL_SEND_SUB_MICRO_AD, 4=eIO_ADC_AI_BATTERY, 5=eIO_ADC_AI_LCD_NTC, 6=eIO_ADC_AI_TEMP_RTC, 7=eIO_ADC_Flasher_Diag_sense_1, 8=eIO_ADC_STR_SW2_ADIN, 9=eIO_ADC_STR_SW1_ADIN, 10=eIO_ADC_RHEO_SW_IN_ADIN, 11=eIO_ADC_ADC_RHEO_5V_MON_ADIN, 12=eIO_ADC_Flasher_Diag_sense_2, 13=eIO_ADC_AdcChannel_Vdb, 14=eIO_ADC_AdcChannel_Vtemp, 15=eIO_ADC_MAX, 0=eIO_ADC_AI_SAMPLE_1, 1=eIO_ADC_AI_SAMPLE_2}
    range raw 0..17
  client server interface TI_IOHWAB_GetAdc
    operation GetAsyncRawAdc: possible-error=TI_IOHWAB_GetAdc/E_NOT_OK
      arg AdcId: implementation-data-type=IoHwAb_AdcSignalIdType, type=IoHwAb_AdcSignalIdType, direction=IN
      arg AsyncRawAdc: implementation-data-type=UInt16, type=UInt16, direction=OUT
      arg ErrorStatus: implementation-data-type=IoHwAb_ErrorType, type=IoHwAb_ErrorType, direction=OUT
    operation GetProcessedAdc: possible-error=TI_IOHWAB_GetAdc/E_NOT_OK
      arg AdcId: implementation-data-type=IoHwAb_AdcSignalIdType, type=IoHwAb_AdcSignalIdType, direction=IN
      arg ProcessedAdc: implementation-data-type=SInt32, type=SInt32, direction=OUT
      arg ErrorStatus: implementation-data-type=IoHwAb_ErrorType, type=IoHwAb_ErrorType, direction=OUT
    operation GetSyncRawAdc: possible-error=TI_IOHWAB_GetAdc/E_NOT_OK
      arg AdcId: implementation-data-type=IoHwAb_AdcSignalIdType, type=IoHwAb_AdcSignalIdType, direction=IN
      arg SyncRawAdc: implementation-data-type=UInt16, type=UInt16, direction=OUT
      arg ErrorStatus: implementation-data-type=IoHwAb_ErrorType, type=IoHwAb_ErrorType, direction=OUT
    error E_NOT_OK: error-code=1
  impl type eIOPulseInputId: category=VALUE, base-type=sint32, compu {0=eIOPulseInputIdCount}, range raw -2147483647..2147483647
  impl type SPulseInputConfigParam: category=STRUCTURE
    16 x element, all with category=TYPE_REFERENCE:
      MissingRecoveryTimeoutInMicroSec: implementation-data-type=UInt32
      ValidPeriodMinInMicroSec: implementation-data-type=UInt32
      ValidPeriodMaxInMicroSec: implementation-data-type=UInt32
      HystLimitForPeriodMinInMicroSec: implementation-data-type=UInt32
      HystRcvryForPeriodMinInMicroSec: implementation-data-type=UInt32
      HystLimitForPeriodMaxInMicroSec: implementation-data-type=UInt32
      HystRcvryForPeriodMaxInMicroSec: implementation-data-type=UInt32
      ValidDutyMinInPercentage: implementation-data-type=UInt16
      ValidDutyMaxInPercentage: implementation-data-type=UInt16
      HystLimitForDutyMinInPercentage: implementation-data-type=UInt16
      HystRcvryForDutyMinInPercentage: implementation-data-type=UInt16
      HystLimitForDutyMaxInPercentage: implementation-data-type=UInt16
      HystRcvryForDutyMaxInPercentage: implementation-data-type=UInt16
      InValidTimeoutInMilliSec: implementation-data-type=UInt16
      InValidRecoveryTimeoutInMilliSec: implementation-data-type=UInt16
      MissingTimeoutInMilliSec: implementation-data-type=UInt16
  impl type SSpeedCalcParam: category=STRUCTURE
    element Pulses_Per_Revolution: implementation-data-type=UInt32
    element Revolutions_Per_Unit: implementation-data-type=UInt32
    element Tuning_Factor: implementation-data-type=UInt32
  client server interface TI_IOHWAB_Pulse
    7 x operation, all with possible-error=TI_IOHWAB_Pulse/E_NOT_OK:
      GetCurrentSignalStatus_PulseInput
        arg PulseInputId: implementation-data-type=eIOPulseInputId, type=eIOPulseInputId, direction=IN
        arg SignalStatus: implementation-data-type=UInt16, type=UInt16, direction=OUT
        arg ErrorStatus: implementation-data-type=IoHwAb_ErrorType, type=IoHwAb_ErrorType, direction=OUT
      GetCurrentSpeed_PulseInput
        arg PulseInputId: implementation-data-type=eIOPulseInputId, type=eIOPulseInputId, direction=IN
        arg SpeedVal: implementation-data-type=UInt32, type=UInt32, direction=OUT
        arg ErrorStatus: implementation-data-type=IoHwAb_ErrorType, type=IoHwAb_ErrorType, direction=OUT
      GetRollingCount_PulseInput
        arg PulseInputId: implementation-data-type=eIOPulseInputId, type=eIOPulseInputId, direction=IN
        arg EdgeCount: implementation-data-type=DataTypes/UInt8, type=DataTypes/UInt8, direction=OUT
        arg ErrorStatus: implementation-data-type=IoHwAb_ErrorType, type=IoHwAb_ErrorType, direction=OUT
      ResetRollingCount_PulseInput
        arg PulseInputId: implementation-data-type=eIOPulseInputId, type=eIOPulseInputId, direction=IN
        arg ErrorStatus: implementation-data-type=IoHwAb_ErrorType, type=IoHwAb_ErrorType, direction=OUT
      Start_Signal_Measurement_PulseInput
        4 x arg:
          PulseInputId: implementation-data-type=eIOPulseInputId, type=eIOPulseInputId, direction=IN
          PulseInputChnlCfgParam: implementation-data-type=SPulseInputConfigParam, type=SPulseInputConfigParam, direction=OUT
          SpdCalParam: implementation-data-type=SSpeedCalcParam, type=SSpeedCalcParam, direction=OUT
          ErrorStatus: implementation-data-type=IoHwAb_ErrorType, type=IoHwAb_ErrorType, direction=OUT
      Stop_Signal_Measurement_PulseInput
        arg PulseInputId: implementation-data-type=eIOPulseInputId, type=eIOPulseInputId, direction=IN
        arg ErrorStatus: implementation-data-type=IoHwAb_ErrorType, type=IoHwAb_ErrorType, direction=OUT
      Update_CalibParam_PulseInput
        arg PulseInputId: implementation-data-type=eIOPulseInputId, type=eIOPulseInputId, direction=IN
        arg SpdCalParam: implementation-data-type=SSpeedCalcParam, type=SSpeedCalcParam, direction=OUT
        arg ErrorStatus: implementation-data-type=IoHwAb_ErrorType, type=IoHwAb_ErrorType, direction=OUT
    error E_NOT_OK: error-code=1
  sender receiver interface TI_BattMdl_AVP
    14 x data, all with implementation-data-type=Boolean, type=Boolean:
      HVP0Flag
      HVSD{0..4}Flag
      LVP0Flag
      LVP1Flag
      LVSD{0..4}Flag
      SVPFlag
    invalidation-policys:
      data-element=HVP0Flag, handle-invalid=DONT-INVALIDATE
      data-element=HVSD{0..4}Flag, handle-invalid=DONT-INVALIDATE
      data-element=LVP0Flag, handle-invalid=DONT-INVALIDATE
      data-element=LVP1Flag, handle-invalid=DONT-INVALIDATE
      data-element=LVSD{0..4}Flag, handle-invalid=DONT-INVALIDATE
      data-element=SVPFlag, handle-invalid=DONT-INVALIDATE
  sender receiver interface TI_BattMdl_Voltage: invalidation-policy{data-element=OverVoltageInterruptFlag, handle-invalid=DONT-INVALIDATE}
    data OverVoltageInterruptFlag: implementation-data-type=Boolean, type=Boolean
  client server interface TI_EcuPowerM
    operation EcuPowerM_GetDeviceStatus: possible-error=TI_EcuPowerM/E_NOT_OK
      arg device: implementation-data-type=DataTypes/UInt8, type=DataTypes/UInt8, direction=IN
      arg status: implementation-data-type=DataTypes/UInt8, type=DataTypes/UInt8, direction=OUT
    operation EcuPowerM_RequestPower: possible-error=TI_EcuPowerM/E_NOT_OK
      arg device: implementation-data-type=DataTypes/UInt8, type=DataTypes/UInt8, direction=IN
      arg request: implementation-data-type=DataTypes/UInt8, type=DataTypes/UInt8, direction=IN
    error E_NOT_OK: error-code=1
  client server interface TI_Display_I2cSeqCallback
    operation I2cSeqEndCallback
  impl type EGammaCorrectionStatus: category=VALUE, base-type=uint8, compu {0=eDisplayCdd_GammaCorrection_None, 1=eDisplayCdd_GammaCorrection_OnGoing, 2=eDisplayCdd_GammaCorrection_Success, 3=eDisplayCdd_GammaCorrection_Failure}, range raw 0..3
  client server interface TI_Display_GammaCorrection
    operation GetGammaCorrectionStatus
      arg GmaCrStatus: implementation-data-type=EGammaCorrectionStatus, type=EGammaCorrectionStatus, direction=OUT
    operation SetGammaCorrection: possible-error=TI_Display_GammaCorrection/E_NOT_OK
      arg GmaSetPtr: implementation-data-type=DataTypes/UInt8, type=DataTypes/UInt8, direction=OUT
      arg datalength: implementation-data-type=DataTypes/UInt8, type=DataTypes/UInt8, direction=IN
    error E_NOT_OK: error-code=1
  impl type EDisplayCddStatus: category=VALUE, base-type=uint8, compu {0=eDisplayNotReady, 1=eDisplayReady, 2=eDisplayBusy, 3=eDisplayFaultHandle, 4=eDisplayMaxStatus}, range raw 0..4
  client server interface TI_Display_Status
    operation GetStatus: possible-error=TI_Display_Status/E_NOT_OK
      arg DeviceId: implementation-data-type=EDisplayType, type=EDisplayType, direction=IN
      arg DeviceStatus: implementation-data-type=EDisplayCddStatus, type=EDisplayCddStatus, direction=OUT
      arg DisplayPowerState: implementation-data-type=EDisplayPowerState, type=EDisplayPowerState, direction=OUT
    operation SetState: possible-error=TI_Display_Status/E_NOT_OK
      arg DeviceID: implementation-data-type=EDisplayType, type=EDisplayType, direction=IN
      arg PowerState: implementation-data-type=EDisplayPowerState, type=EDisplayPowerState, direction=IN
    error E_NOT_OK: error-code=1
  impl type teDiagOpStatus: category=VALUE, base-type=uint8, compu {0=DIAG_INITIAL, 1=DIAG_PENDING, 2=DIAG_CANCEL, 3=DIAG_FORCE_RCRRP_OK, 64=DIAG_FORCE_RCRRP_NOT_OK}, range raw 0..64
  impl type teDIDOperation: category=VALUE, base-type=uint8, compu {0=eRead, 1=eWrite, 2=eSTA, 3=eRTCtrl, 4=eCheckConditions}, range raw 0..4
  client server interface TI_DID_DiagAction
    operation DID_DiagAction: possible-error=TI_DID_DiagAction/E_NOT_OK
      5 x arg:
        OpStatus: implementation-data-type=teDiagOpStatus, type=teDiagOpStatus, direction=IN
        DIDNum: implementation-data-type=UInt16, type=UInt16, direction=IN
        Data: implementation-data-type=DataTypes/UInt8, type=DataTypes/UInt8, direction=OUT
        pNrc: implementation-data-type=DataTypes/UInt8, type=DataTypes/UInt8, direction=OUT
        eOperation: implementation-data-type=teDIDOperation, type=teDIDOperation, direction=IN
    error E_NOT_OK: error-code=1
  impl type EDcmExtAction: category=VALUE, base-type=uint8, compu {0=eDcmExtAction_Read, 1=eDcmExtAction_Write, 2=eDcmExtAction_IOCtrl, 3=eDcmExtAction_RetCtrlEcu, 4=eDcmExtAction_RoutineStart, 5=eDcmExtAction_RoutineStop, 6=eDcmExtAction__RoutineResult, 7=eDcmExtAction_CheckConditions, 8=eDcmExtAction_Reset}, range raw 0..8
  client server interface TI_Meet_Mgrdiagcdd_Action
    operation Meet_Mgrdiagcdd_Action: possible-error=TI_Meet_Mgrdiagcdd_Action/E_NOT_OK
      4 x arg, all with direction=OUT:
        Action: implementation-data-type=EDcmExtAction, type=EDcmExtAction
        Data: implementation-data-type=DataTypes/UInt8, type=DataTypes/UInt8
        Length: implementation-data-type=DataTypes/UInt8, type=DataTypes/UInt8
        DID: implementation-data-type=UInt32, type=UInt32
    error E_NOT_OK: error-code=1
  impl type teRoutineOperation: category=VALUE, base-type=uint8, compu {0=eRoutineStart, 1=eRoutineStop, 2=eRoutineResult}, range raw 0..2
  client server interface TI_RID_DiagAction
    operation RID_DiagAction: possible-error=TI_RID_DiagAction/E_NOT_OK
      7 x arg:
        OpStatus: implementation-data-type=teDiagOpStatus, type=teDiagOpStatus, direction=IN
        RIDNum: implementation-data-type=UInt16, type=UInt16, direction=IN
        Out_RoutineInfo: implementation-data-type=DataTypes/UInt8, type=DataTypes/UInt8, direction=OUT
        Data: implementation-data-type=DataTypes/UInt8, type=DataTypes/UInt8, direction=OUT
        DataLength: implementation-data-type=DataTypes/UInt8, type=DataTypes/UInt8, direction=OUT
        pNrc: implementation-data-type=DataTypes/UInt8, type=DataTypes/UInt8, direction=OUT
        eOperation: implementation-data-type=teRoutineOperation, type=teRoutineOperation, direction=IN
    error E_NOT_OK: error-code=1
  impl type EMeetModeStatus: category=VALUE, base-type=uint8, compu {0=eManufModeActive, 1=eManufModeInActive}, range raw 0..1
  client server interface TI_Read_ManufModeStatus
    operation Read_ManufModeStatus: possible-error=TI_Read_ManufModeStatus/E_NOT_OK
      arg currentstate: implementation-data-type=EMeetModeStatus, type=EMeetModeStatus, direction=OUT
    error E_NOT_OK: error-code=1
  client server interface TI_Write_Mfg_Flag
    operation Write_Mfg_Flag: possible-error=TI_Write_Mfg_Flag/E_NOT_OK
      arg pdata: implementation-data-type=UInt16, type=UInt16, direction=OUT
    error E_NOT_OK: error-code=1
  sender receiver interface TI_SleepReq: invalidation-policy{data-element=SleepReqData, handle-invalid=DONT-INVALIDATE}
    data SleepReqData: implementation-data-type=Boolean, type=Boolean
  10 x impl type, all with category=ARRAY:
    Arr_u8_128
      element ArrayElement: category=VALUE, array-size=128, array-size-semantics=FIXED-SIZE, base-type=uint8
    Arr_u8_64
      element ArrayElement: category=VALUE, array-size=64, array-size-semantics=FIXED-SIZE, base-type=uint8
    Arr_u8_32
      element ArrayElement: category=VALUE, array-size=32, array-size-semantics=FIXED-SIZE, base-type=uint8
    Arr_u8_48
      element ArrayElement: category=VALUE, array-size=48, array-size-semantics=FIXED-SIZE, base-type=uint8
    Arr_u8_2048
      element ArrayElement: category=VALUE, array-size=2048, array-size-semantics=FIXED-SIZE, base-type=uint8
    Arr_u8_1024
      element ArrayElement: category=VALUE, array-size=1024, array-size-semantics=FIXED-SIZE, base-type=uint8
    Arr_u8_16
      element ArrayElement: category=VALUE, array-size=16, array-size-semantics=FIXED-SIZE, base-type=uint8
    Arr_u8_100
      element ArrayElement: category=VALUE, array-size=100, array-size-semantics=FIXED-SIZE, base-type=uint8
    Arr_u8_256
      element ArrayElement: category=VALUE, array-size=256, array-size-semantics=FIXED-SIZE, base-type=uint8
    Arr_u8_8
      element ArrayElement: category=VALUE, array-size=8, array-size-semantics=FIXED-SIZE, base-type=uint8
  client server interface if_CS_MemAbsGet
    60 x operation, all with possible-error=if_CS_MemAbsGet/E_NOT_OK:
      Get_BsConst_Audio_Element
        arg Ptr: implementation-data-type=Arr_u8_128, type=Arr_u8_128, direction=OUT
      Get_BsConst_Communication_Element
        arg Ptr: implementation-data-type=Arr_u8_64, type=Arr_u8_64, direction=OUT
      Get_BsConst_EngOffTimer_Element
        arg Ptr: implementation-data-type=Arr_u8_32, type=Arr_u8_32, direction=OUT
      Get_BsConst_FuelGauge_Element
        arg Ptr: implementation-data-type=Arr_u8_128, type=Arr_u8_128, direction=OUT
      Get_BsConst_Illumination_Element
        arg Ptr: implementation-data-type=Arr_u8_128, type=Arr_u8_128, direction=OUT
      Get_BsConst_OilGauge_Element
        arg Ptr: implementation-data-type=Arr_u8_64, type=Arr_u8_64, direction=OUT
      Get_BsConst_PowerGauge_Element
        arg Ptr: implementation-data-type=Arr_u8_64, type=Arr_u8_64, direction=OUT
      Get_BsConst_Power_Element
        arg Ptr: implementation-data-type=Arr_u8_32, type=Arr_u8_32, direction=OUT
      Get_BsConst_RealTimeClock_Element
        arg Ptr: implementation-data-type=Arr_u8_48, type=Arr_u8_48, direction=OUT
      Get_BsConst_ServiceReminder_Element
        arg Ptr: implementation-data-type=Arr_u8_48, type=Arr_u8_48, direction=OUT
      Get_BsConst_SpeedoGauge_Element
        arg Ptr: implementation-data-type=Arr_u8_64, type=Arr_u8_64, direction=OUT
      Get_BsConst_TachoGauge_Element
        arg Ptr: implementation-data-type=Arr_u8_64, type=Arr_u8_64, direction=OUT
      Get_BsConst_TempGauge_Element
        arg Ptr: implementation-data-type=Arr_u8_64, type=Arr_u8_64, direction=OUT
      Get_BsConst_TripComputer_Element
        arg Ptr: implementation-data-type=Arr_u8_64, type=Arr_u8_64, direction=OUT
      Get_BsConst_Warning_Element
        arg Ptr: implementation-data-type=Arr_u8_64, type=Arr_u8_64, direction=OUT
      Get_BsCys_Certicificate_Element
        arg Ptr: implementation-data-type=Arr_u8_64, type=Arr_u8_64, direction=OUT
      Get_BsDiag_Dtc_Element
        arg Ptr: implementation-data-type=Arr_u8_2048, type=Arr_u8_2048, direction=OUT
      Get_BsDiag_ErrorRecord_Element
        arg Ptr: implementation-data-type=Arr_u8_1024, type=Arr_u8_1024, direction=OUT
      Get_BsFuSa_Audio_Element
        arg Ptr: implementation-data-type=Arr_u8_32, type=Arr_u8_32, direction=OUT
      Get_BsFuSa_Communication_Element
        arg Ptr: implementation-data-type=Arr_u8_16, type=Arr_u8_16, direction=OUT
      Get_BsFuSa_Config_Element
        arg Ptr: implementation-data-type=Arr_u8_16, type=Arr_u8_16, direction=OUT
      Get_BsFuSa_Display_Element
        arg Ptr: implementation-data-type=Arr_u8_64, type=Arr_u8_64, direction=OUT
      Get_BsFuSa_Power_Element
        arg Ptr: implementation-data-type=Arr_u8_48, type=Arr_u8_48, direction=OUT
      Get_BsFuSa_Warning_Element
        arg Ptr: implementation-data-type=Arr_u8_32, type=Arr_u8_32, direction=OUT
      Get_BsFusa_Fota_Element
        arg Ptr: implementation-data-type=Arr_u8_32, type=Arr_u8_32, direction=OUT
      Get_BsReten_Audio_Element
        arg Ptr: implementation-data-type=Arr_u8_100, type=Arr_u8_100, direction=OUT
      Get_BsReten_Communication_Element
        arg Ptr: implementation-data-type=Arr_u8_100, type=Arr_u8_100, direction=OUT
      Get_BsReten_Display_Element
        arg Ptr: implementation-data-type=Arr_u8_100, type=Arr_u8_100, direction=OUT
      Get_BsReten_Gauges_Element
        arg Ptr: implementation-data-type=Arr_u8_100, type=Arr_u8_100, direction=OUT
      Get_BsReten_Illumination_Element
        arg Ptr: implementation-data-type=Arr_u8_100, type=Arr_u8_100, direction=OUT
      Get_BsReten_Odometer_Element
        arg Ptr: implementation-data-type=Arr_u8_100, type=Arr_u8_100, direction=OUT
      Get_BsReten_Personalization_Element
        arg Ptr: implementation-data-type=Arr_u8_100, type=Arr_u8_100, direction=OUT
      Get_BsReten_Power_Element
        arg Ptr: implementation-data-type=Arr_u8_100, type=Arr_u8_100, direction=OUT
      Get_BsReten_RealTimeClock_Element
        arg Ptr: implementation-data-type=Arr_u8_100, type=Arr_u8_100, direction=OUT
      Get_BsReten_Tripcomputer_Element
        arg Ptr: implementation-data-type=Arr_u8_100, type=Arr_u8_100, direction=OUT
      Get_BsReten_VisDlt_Element
        arg Ptr: implementation-data-type=Arr_u8_256, type=Arr_u8_256, direction=OUT
      Get_BsReten_Warning_Element
        arg Ptr: implementation-data-type=Arr_u8_100, type=Arr_u8_100, direction=OUT
      Get_BsRt_CusDlt_Element
        arg Ptr: implementation-data-type=Arr_u8_128, type=Arr_u8_128, direction=OUT
      Get_BsRt_FuelGauge_Element
        arg Ptr: implementation-data-type=Arr_u8_32, type=Arr_u8_32, direction=OUT
      Get_BsRt_Illumination_Element
        arg Ptr: implementation-data-type=Arr_u8_100, type=Arr_u8_100, direction=OUT
      Get_BsRt_Odometer_Element
        arg Ptr: implementation-data-type=Arr_u8_128, type=Arr_u8_128, direction=OUT
      Get_BsRt_OilGauge_Element
        arg Ptr: implementation-data-type=Arr_u8_8, type=Arr_u8_8, direction=OUT
      Get_BsRt_Personalization_Element
        arg Ptr: implementation-data-type=Arr_u8_128, type=Arr_u8_128, direction=OUT
      Get_BsRt_PowerGauge_Element
        arg Ptr: implementation-data-type=Arr_u8_32, type=Arr_u8_32, direction=OUT
      Get_BsRt_RealTimeClock_Element
        arg Ptr: implementation-data-type=Arr_u8_48, type=Arr_u8_48, direction=OUT
      Get_BsRt_SpeedoGauge_Element
        arg Ptr: implementation-data-type=Arr_u8_8, type=Arr_u8_8, direction=OUT
      Get_BsRt_TachoGauge_Element
        arg Ptr: implementation-data-type=Arr_u8_16, type=Arr_u8_16, direction=OUT
      Get_BsRt_TempGauge_Element
        arg Ptr: implementation-data-type=Arr_u8_32, type=Arr_u8_32, direction=OUT
      Get_BsRt_TripComputer_Element
        arg Ptr: implementation-data-type=Arr_u8_64, type=Arr_u8_64, direction=OUT
      Get_BsRt_Warning_Element
        arg Ptr: implementation-data-type=Arr_u8_32, type=Arr_u8_32, direction=OUT
      Get_BsShare_EcuPartNumber_Element
        arg Ptr: implementation-data-type=Arr_u8_128, type=Arr_u8_128, direction=OUT
      Get_BsShare_SwUpdFotaFinPrint_Element
        arg Ptr: implementation-data-type=Arr_u8_32, type=Arr_u8_32, direction=OUT
      Get_BsShare_SwUpdFotaMode_Element
        arg Ptr: implementation-data-type=Arr_u8_16, type=Arr_u8_16, direction=OUT
      Get_BsShare_SwUpdFotaStatus_Element
        arg Ptr: implementation-data-type=Arr_u8_48, type=Arr_u8_48, direction=OUT
      Get_BsShare_SwUpdFotadecrypt_Element
        arg Ptr: implementation-data-type=Arr_u8_64, type=Arr_u8_64, direction=OUT
      Get_BsShare_SwUpdReflash_Element
        arg Ptr: implementation-data-type=Arr_u8_8, type=Arr_u8_8, direction=OUT
      Get_BsShare_VehicleConfig_Element
        arg Ptr: implementation-data-type=Arr_u8_256, type=Arr_u8_256, direction=OUT
      Get_BsShare_VisMeet_Element
        arg Ptr: implementation-data-type=Arr_u8_48, type=Arr_u8_48, direction=OUT
      Get_RefCys_Certicificate1_Element
        arg Ptr: implementation-data-type=Arr_u8_64, type=Arr_u8_64, direction=OUT
      Get_RefCys_Certicificate_Element
        arg Ptr: implementation-data-type=Arr_u8_64, type=Arr_u8_64, direction=OUT
    error E_NOT_OK: error-code=1
  client server interface if_CS_MemAbsSet
    60 x operation:
      Set_BsConst_Audio_Element
        arg BsConst_Audio_Element: implementation-data-type=Arr_u8_128, type=Arr_u8_128, direction=IN
      Set_BsConst_Communication_Element
        arg BsConst_Communication_Element: implementation-data-type=Arr_u8_64, type=Arr_u8_64, direction=IN
      Set_BsConst_EngOffTimer_Element
        arg BsConst_EngOffTimer_Element: implementation-data-type=Arr_u8_32, type=Arr_u8_32, direction=IN
      Set_BsConst_FuelGauge_Element
        arg BsConst_FuelGauge_Element: implementation-data-type=Arr_u8_128, type=Arr_u8_128, direction=IN
      Set_BsConst_Illumination_Element
        arg BsConst_Illumination_Element: implementation-data-type=Arr_u8_128, type=Arr_u8_128, direction=IN
      Set_BsConst_OilGauge_Element
        arg BsConst_OilGauge_Element: implementation-data-type=Arr_u8_64, type=Arr_u8_64, direction=IN
      Set_BsConst_PowerGauge_Element
        arg BsConst_PowerGauge_Element: implementation-data-type=Arr_u8_64, type=Arr_u8_64, direction=IN
      Set_BsConst_Power_Element
        arg BsConst_Power_Element: implementation-data-type=Arr_u8_32, type=Arr_u8_32, direction=IN
      Set_BsConst_RealTimeClock_Element
        arg BsConst_RealTimeClock_Element: implementation-data-type=Arr_u8_48, type=Arr_u8_48, direction=IN
      Set_BsConst_ServiceReminder_Element
        arg BsConst_ServiceReminder_Element: implementation-data-type=Arr_u8_48, type=Arr_u8_48, direction=IN
      Set_BsConst_SpeedoGauge_Element
        arg BsConst_SpeedoGauge_Element: implementation-data-type=Arr_u8_64, type=Arr_u8_64, direction=IN
      Set_BsConst_TachoGauge_Element
        arg BsConst_TachoGauge_Element: implementation-data-type=Arr_u8_64, type=Arr_u8_64, direction=IN
      Set_BsConst_TempGauge_Element
        arg BsConst_TempGauge_Element: implementation-data-type=Arr_u8_64, type=Arr_u8_64, direction=IN
      Set_BsConst_TripComputer_Element
        arg BsConst_TripComputer_Element: implementation-data-type=Arr_u8_64, type=Arr_u8_64, direction=IN
      Set_BsConst_Warning_Element
        arg BsConst_Warning_Element: implementation-data-type=Arr_u8_64, type=Arr_u8_64, direction=IN
      Set_BsCys_Certicificate_Element
        arg BsCys_Certicificate_Element: implementation-data-type=Arr_u8_64, type=Arr_u8_64, direction=IN
      Set_BsDiag_Dtc_Element
        arg BsDiag_Dtc_Element: implementation-data-type=Arr_u8_2048, type=Arr_u8_2048, direction=IN
      Set_BsDiag_ErrorRecord_Element
        arg BsDiag_ErrorRecord_Element: implementation-data-type=Arr_u8_1024, type=Arr_u8_1024, direction=IN
      Set_BsFuSa_Audio_Element
        arg BsFuSa_Audio_Element: implementation-data-type=Arr_u8_32, type=Arr_u8_32, direction=IN
      Set_BsFuSa_Communication_Element
        arg BsFuSa_Communication_Element: implementation-data-type=Arr_u8_16, type=Arr_u8_16, direction=IN
      Set_BsFuSa_Config_Element
        arg BsFuSa_Config_Element: implementation-data-type=Arr_u8_16, type=Arr_u8_16, direction=IN
      Set_BsFuSa_Display_Element
        arg BsFuSa_Display_Element: implementation-data-type=Arr_u8_64, type=Arr_u8_64, direction=IN
      Set_BsFuSa_Power_Element
        arg BsFuSa_Power_Element: implementation-data-type=Arr_u8_48, type=Arr_u8_48, direction=IN
      Set_BsFuSa_Warning_Element
        arg BsFuSa_Warning_Element: implementation-data-type=Arr_u8_32, type=Arr_u8_32, direction=IN
      Set_BsFusa_Fota_Element
        arg BsFusa_Fota_Element: implementation-data-type=Arr_u8_32, type=Arr_u8_32, direction=IN
      Set_BsReten_Audio_Element
        arg BsReten_Audio_Element: implementation-data-type=Arr_u8_100, type=Arr_u8_100, direction=IN
      Set_BsReten_Communication_Element
        arg BsReten_Communication_Element: implementation-data-type=Arr_u8_100, type=Arr_u8_100, direction=IN
      Set_BsReten_Display_Element
        arg BsReten_Display_Element: implementation-data-type=Arr_u8_100, type=Arr_u8_100, direction=IN
      Set_BsReten_Gauges_Element
        arg BsReten_Gauges_Element: implementation-data-type=Arr_u8_100, type=Arr_u8_100, direction=IN
      Set_BsReten_Illumination_Element
        arg BsReten_Illumination_Element: implementation-data-type=Arr_u8_100, type=Arr_u8_100, direction=IN
      Set_BsReten_Odometer_Element
        arg BsReten_Odometer_Element: implementation-data-type=Arr_u8_100, type=Arr_u8_100, direction=IN
      Set_BsReten_Personalization_Element
        arg BsReten_Personalization_Element: implementation-data-type=Arr_u8_100, type=Arr_u8_100, direction=IN
      Set_BsReten_Power_Element
        arg BsReten_Power_Element: implementation-data-type=Arr_u8_100, type=Arr_u8_100, direction=IN
      Set_BsReten_RealTimeClock_Element
        arg BsReten_RealTimeClock_Element: implementation-data-type=Arr_u8_100, type=Arr_u8_100, direction=IN
      Set_BsReten_Tripcomputer_Element
        arg BsReten_Tripcomputer_Element: implementation-data-type=Arr_u8_100, type=Arr_u8_100, direction=IN
      Set_BsReten_VisDlt_Element
        arg BsReten_VisDlt_Element: implementation-data-type=Arr_u8_256, type=Arr_u8_256, direction=IN
      Set_BsReten_Warning_Element
        arg BsReten_Warning_Element: implementation-data-type=Arr_u8_100, type=Arr_u8_100, direction=IN
      Set_BsRt_CusDlt_Element
        arg BsRt_CusDlt_Element: implementation-data-type=Arr_u8_128, type=Arr_u8_128, direction=IN
      Set_BsRt_FuelGauge_Element
        arg BsRt_FuelGauge_Element: implementation-data-type=Arr_u8_32, type=Arr_u8_32, direction=IN
      Set_BsRt_Illumination_Element
        arg BsRt_Illumination_Element: implementation-data-type=Arr_u8_100, type=Arr_u8_100, direction=IN
      Set_BsRt_Odometer_Element
        arg BsRt_Odometer_Element: implementation-data-type=Arr_u8_128, type=Arr_u8_128, direction=IN
      Set_BsRt_OilGauge_Element
        arg BsRt_OilGauge_Element: implementation-data-type=Arr_u8_8, type=Arr_u8_8, direction=IN
      Set_BsRt_Personalization_Element
        arg BsRt_Personalization_Element: implementation-data-type=Arr_u8_128, type=Arr_u8_128, direction=IN
      Set_BsRt_PowerGauge_Element
        arg BsRt_PowerGauge_Element: implementation-data-type=Arr_u8_32, type=Arr_u8_32, direction=IN
      Set_BsRt_RealTimeClock_Element
        arg BsRt_RealTimeClock_Element: implementation-data-type=Arr_u8_48, type=Arr_u8_48, direction=IN
      Set_BsRt_SpeedoGauge_Element
        arg BsRt_SpeedoGauge_Element: implementation-data-type=Arr_u8_8, type=Arr_u8_8, direction=IN
      Set_BsRt_TachoGauge_Element
        arg BsRt_TachoGauge_Element: implementation-data-type=Arr_u8_16, type=Arr_u8_16, direction=IN
      Set_BsRt_TempGauge_Element
        arg BsRt_TempGauge_Element: implementation-data-type=Arr_u8_32, type=Arr_u8_32, direction=IN
      Set_BsRt_TripComputer_Element
        arg BsRt_TripComputer_Element: implementation-data-type=Arr_u8_64, type=Arr_u8_64, direction=IN
      Set_BsRt_Warning_Element
        arg BsRt_Warning_Element: implementation-data-type=Arr_u8_32, type=Arr_u8_32, direction=IN
      Set_BsShare_EcuPartNumber_Element
        arg BsShare_EcuPartNumber_Element: implementation-data-type=Arr_u8_128, type=Arr_u8_128, direction=IN
      Set_BsShare_SwUpdFotaFinPrint_Element
        arg BsShare_SwUpdFotaFinPrint_Element: implementation-data-type=Arr_u8_32, type=Arr_u8_32, direction=IN
      Set_BsShare_SwUpdFotaMode_Element
        arg BsShare_SwUpdFotaMode_Element: implementation-data-type=Arr_u8_16, type=Arr_u8_16, direction=IN
      Set_BsShare_SwUpdFotaStatus_Element
        arg BsShare_SwUpdFotaStatus_Element: implementation-data-type=Arr_u8_48, type=Arr_u8_48, direction=IN
      Set_BsShare_SwUpdFotadecrypt_Element
        arg BsShare_SwUpdFotadecrypt_Element: implementation-data-type=Arr_u8_64, type=Arr_u8_64, direction=IN
      Set_BsShare_SwUpdReflash_Element
        arg BsShare_SwUpdReflash_Element: implementation-data-type=Arr_u8_8, type=Arr_u8_8, direction=IN
      Set_BsShare_VehicleConfig_Element
        arg BsShare_VehicleConfig_Element: implementation-data-type=Arr_u8_256, type=Arr_u8_256, direction=IN
      Set_BsShare_VisMeet_Element
        arg BsShare_VisMeet_Element: implementation-data-type=Arr_u8_48, type=Arr_u8_48, direction=IN
      Set_RefCys_Certicificate1_Element
        arg RefCys_Certicificate1_Element: implementation-data-type=Arr_u8_64, type=Arr_u8_64, direction=IN
      Set_RefCys_Certicificate_Element
        arg RefCys_Certicificate_Element: implementation-data-type=Arr_u8_64, type=Arr_u8_64, direction=IN
  sender receiver interface if_SR_JobStatus
    60 x data, all with implementation-data-type=DataTypes/UInt8, type=DataTypes/UInt8:
      JobStatus_BsConst_Audio_Element
      JobStatus_BsConst_Communication_Element
      JobStatus_BsConst_EngOffTimer_Element
      JobStatus_BsConst_FuelGauge_Element
      JobStatus_BsConst_Illumination_Element
      JobStatus_BsConst_OilGauge_Element
      JobStatus_BsConst_PowerGauge_Element
      JobStatus_BsConst_Power_Element
      JobStatus_BsConst_RealTimeClock_Element
      JobStatus_BsConst_ServiceReminder_Element
      JobStatus_BsConst_SpeedoGauge_Element
      JobStatus_BsConst_TachoGauge_Element
      JobStatus_BsConst_TempGauge_Element
      JobStatus_BsConst_TripComputer_Element
      JobStatus_BsConst_Warning_Element
      JobStatus_BsCys_Certicificate_Element
      JobStatus_BsDiag_Dtc_Element
      JobStatus_BsDiag_ErrorRecord_Element
      JobStatus_BsFuSa_Audio_Element
      JobStatus_BsFuSa_Communication_Element
      JobStatus_BsFuSa_Config_Element
      JobStatus_BsFuSa_Display_Element
      JobStatus_BsFuSa_Power_Element
      JobStatus_BsFuSa_Warning_Element
      JobStatus_BsFusa_Fota_Element
      JobStatus_BsReten_Audio_Element
      JobStatus_BsReten_Communication_Element
      JobStatus_BsReten_Display_Element
      JobStatus_BsReten_Gauges_Element
      JobStatus_BsReten_Illumination_Element
      JobStatus_BsReten_Odometer_Element
      JobStatus_BsReten_Personalization_Element
      JobStatus_BsReten_Power_Element
      JobStatus_BsReten_RealTimeClock_Element
      JobStatus_BsReten_Tripcomputer_Element
      JobStatus_BsReten_VisDlt_Element
      JobStatus_BsReten_Warning_Element
      JobStatus_BsRt_CusDlt_Element
      JobStatus_BsRt_FuelGauge_Element
      JobStatus_BsRt_Illumination_Element
      JobStatus_BsRt_Odometer_Element
      JobStatus_BsRt_OilGauge_Element
      JobStatus_BsRt_Personalization_Element
      JobStatus_BsRt_PowerGauge_Element
      JobStatus_BsRt_RealTimeClock_Element
      JobStatus_BsRt_SpeedoGauge_Element
      JobStatus_BsRt_TachoGauge_Element
      JobStatus_BsRt_TempGauge_Element
      JobStatus_BsRt_TripComputer_Element
      JobStatus_BsRt_Warning_Element
      JobStatus_BsShare_EcuPartNumber_Element
      JobStatus_BsShare_SwUpdFotaFinPrint_Element
      JobStatus_BsShare_SwUpdFotaMode_Element
      JobStatus_BsShare_SwUpdFotaStatus_Element
      JobStatus_BsShare_SwUpdFotadecrypt_Element
      JobStatus_BsShare_SwUpdReflash_Element
      JobStatus_BsShare_VehicleConfig_Element
      JobStatus_BsShare_VisMeet_Element
      JobStatus_RefCys_Certicificate1_Element
      JobStatus_RefCys_Certicificate_Element
    invalidation-policys:
      data-element=JobStatus_BsConst_Audio_Element, handle-invalid=DONT-INVALIDATE
      data-element=JobStatus_BsConst_Communication_Element, handle-invalid=DONT-INVALIDATE
      data-element=JobStatus_BsConst_EngOffTimer_Element, handle-invalid=DONT-INVALIDATE
      data-element=JobStatus_BsConst_FuelGauge_Element, handle-invalid=DONT-INVALIDATE
      data-element=JobStatus_BsConst_Illumination_Element, handle-invalid=DONT-INVALIDATE
      data-element=JobStatus_BsConst_OilGauge_Element, handle-invalid=DONT-INVALIDATE
      data-element=JobStatus_BsConst_PowerGauge_Element, handle-invalid=DONT-INVALIDATE
      data-element=JobStatus_BsConst_Power_Element, handle-invalid=DONT-INVALIDATE
      data-element=JobStatus_BsConst_RealTimeClock_Element, handle-invalid=DONT-INVALIDATE
      data-element=JobStatus_BsConst_ServiceReminder_Element, handle-invalid=DONT-INVALIDATE
      data-element=JobStatus_BsConst_SpeedoGauge_Element, handle-invalid=DONT-INVALIDATE
      data-element=JobStatus_BsConst_TachoGauge_Element, handle-invalid=DONT-INVALIDATE
      data-element=JobStatus_BsConst_TempGauge_Element, handle-invalid=DONT-INVALIDATE
      data-element=JobStatus_BsConst_TripComputer_Element, handle-invalid=DONT-INVALIDATE
      data-element=JobStatus_BsConst_Warning_Element, handle-invalid=DONT-INVALIDATE
      data-element=JobStatus_BsCys_Certicificate_Element, handle-invalid=DONT-INVALIDATE
      data-element=JobStatus_BsDiag_Dtc_Element, handle-invalid=DONT-INVALIDATE
      data-element=JobStatus_BsDiag_ErrorRecord_Element, handle-invalid=DONT-INVALIDATE
      data-element=JobStatus_BsFuSa_Audio_Element, handle-invalid=DONT-INVALIDATE
      data-element=JobStatus_BsFuSa_Communication_Element, handle-invalid=DONT-INVALIDATE
      data-element=JobStatus_BsFuSa_Config_Element, handle-invalid=DONT-INVALIDATE
      data-element=JobStatus_BsFuSa_Display_Element, handle-invalid=DONT-INVALIDATE
      data-element=JobStatus_BsFuSa_Power_Element, handle-invalid=DONT-INVALIDATE
      data-element=JobStatus_BsFuSa_Warning_Element, handle-invalid=DONT-INVALIDATE
      data-element=JobStatus_BsFusa_Fota_Element, handle-invalid=DONT-INVALIDATE
      data-element=JobStatus_BsReten_Audio_Element, handle-invalid=DONT-INVALIDATE
      data-element=JobStatus_BsReten_Communication_Element, handle-invalid=DONT-INVALIDATE
      data-element=JobStatus_BsReten_Display_Element, handle-invalid=DONT-INVALIDATE
      data-element=JobStatus_BsReten_Gauges_Element, handle-invalid=DONT-INVALIDATE
      data-element=JobStatus_BsReten_Illumination_Element, handle-invalid=DONT-INVALIDATE
      data-element=JobStatus_BsReten_Odometer_Element, handle-invalid=DONT-INVALIDATE
      data-element=JobStatus_BsReten_Personalization_Element, handle-invalid=DONT-INVALIDATE
      data-element=JobStatus_BsReten_Power_Element, handle-invalid=DONT-INVALIDATE
      data-element=JobStatus_BsReten_RealTimeClock_Element, handle-invalid=DONT-INVALIDATE
      data-element=JobStatus_BsReten_Tripcomputer_Element, handle-invalid=DONT-INVALIDATE
      data-element=JobStatus_BsReten_VisDlt_Element, handle-invalid=DONT-INVALIDATE
      data-element=JobStatus_BsReten_Warning_Element, handle-invalid=DONT-INVALIDATE
      data-element=JobStatus_BsRt_CusDlt_Element, handle-invalid=DONT-INVALIDATE
      data-element=JobStatus_BsRt_FuelGauge_Element, handle-invalid=DONT-INVALIDATE
      data-element=JobStatus_BsRt_Illumination_Element, handle-invalid=DONT-INVALIDATE
      data-element=JobStatus_BsRt_Odometer_Element, handle-invalid=DONT-INVALIDATE
      data-element=JobStatus_BsRt_OilGauge_Element, handle-invalid=DONT-INVALIDATE
      data-element=JobStatus_BsRt_Personalization_Element, handle-invalid=DONT-INVALIDATE
      data-element=JobStatus_BsRt_PowerGauge_Element, handle-invalid=DONT-INVALIDATE
      data-element=JobStatus_BsRt_RealTimeClock_Element, handle-invalid=DONT-INVALIDATE
      data-element=JobStatus_BsRt_SpeedoGauge_Element, handle-invalid=DONT-INVALIDATE
      data-element=JobStatus_BsRt_TachoGauge_Element, handle-invalid=DONT-INVALIDATE
      data-element=JobStatus_BsRt_TempGauge_Element, handle-invalid=DONT-INVALIDATE
      data-element=JobStatus_BsRt_TripComputer_Element, handle-invalid=DONT-INVALIDATE
      data-element=JobStatus_BsRt_Warning_Element, handle-invalid=DONT-INVALIDATE
      data-element=JobStatus_BsShare_EcuPartNumber_Element, handle-invalid=DONT-INVALIDATE
      data-element=JobStatus_BsShare_SwUpdFotaFinPrint_Element, handle-invalid=DONT-INVALIDATE
      data-element=JobStatus_BsShare_SwUpdFotaMode_Element, handle-invalid=DONT-INVALIDATE
      data-element=JobStatus_BsShare_SwUpdFotaStatus_Element, handle-invalid=DONT-INVALIDATE
      data-element=JobStatus_BsShare_SwUpdFotadecrypt_Element, handle-invalid=DONT-INVALIDATE
      data-element=JobStatus_BsShare_SwUpdReflash_Element, handle-invalid=DONT-INVALIDATE
      data-element=JobStatus_BsShare_VehicleConfig_Element, handle-invalid=DONT-INVALIDATE
      data-element=JobStatus_BsShare_VisMeet_Element, handle-invalid=DONT-INVALIDATE
      data-element=JobStatus_RefCys_Certicificate1_Element, handle-invalid=DONT-INVALIDATE
      data-element=JobStatus_RefCys_Certicificate_Element, handle-invalid=DONT-INVALIDATE
  client server interface if_CS_MemAbs_NvMWriteStatus
    operation NvmWriteStatus: possible-error=if_CS_MemAbs_NvMWriteStatus/E_NOT_OK
    error E_NOT_OK: error-code=1
  impl type Rtc_TimeType: category=STRUCTURE
    7 x element, all with category=TYPE_REFERENCE:
      year: implementation-data-type=UInt16
      month: implementation-data-type=DataTypes/UInt8
      week: implementation-data-type=DataTypes/UInt8
      day: implementation-data-type=DataTypes/UInt8
      hour: implementation-data-type=DataTypes/UInt8
      minute: implementation-data-type=DataTypes/UInt8
      second: implementation-data-type=DataTypes/UInt8
  impl type Rtc_AlarmType: category=STRUCTURE
    element day: implementation-data-type=DataTypes/UInt8
    element minute: implementation-data-type=DataTypes/UInt8
    element hour: implementation-data-type=DataTypes/UInt8
  client server interface if_CS_TIRtcServices
    4 x operation, all with possible-error=if_CS_TIRtcServices/E_NOT_OK:
      RtcCdd_ClearAlarm
      RtcCdd_GetTime
        arg p_time: implementation-data-type=Rtc_TimeType, type=Rtc_TimeType, direction=OUT
      RtcCdd_SetAlarm
        arg p_alarm: implementation-data-type=Rtc_AlarmType, type=Rtc_AlarmType, direction=IN
      RtcCdd_SetTime
        arg p_time: implementation-data-type=Rtc_TimeType, type=Rtc_TimeType, direction=IN
    error E_NOT_OK: error-code=1
  sender receiver interface If_SR_SleepStatus: invalidation-policy{data-element=SleepManager_SleepStatus, handle-invalid=DONT-INVALIDATE}
    data SleepManager_SleepStatus: implementation-data-type=DataTypes/UInt8, type=DataTypes/UInt8
  client server interface if_CS_SndCdd_AmpDiag
    operation GetSpeaker_status: possible-error=if_CS_SndCdd_AmpDiag/E_NOT_OK
      arg SpkrState: implementation-data-type=DataTypes/UInt8, type=DataTypes/UInt8, direction=OUT
      arg SpkrDiagStatus: implementation-data-type=DataTypes/UInt8, type=DataTypes/UInt8, direction=OUT
    operation SpkrAmp_Recovery: possible-error=if_CS_SndCdd_AmpDiag/E_NOT_OK
    error E_NOT_OK: error-code=1
  impl type EChimeID: category=VALUE, base-type=uint8, compu {0=NO_CHIME_ID, 1=MAX_CHIME_ID}, range raw 0..1
  impl type EChimeStatus: category=VALUE, base-type=uint16, range raw 0..65535
  impl type ELastToneStatus: category=VALUE, base-type=boolean, range raw 0..1
  impl type ESndToneInterruptableType: category=VALUE, base-type=uint8, compu {0=eSndToneInterruptableType_NotInterruptible, 1=eSndToneInterruptableType_Interruptible}, range raw 0..1
  impl type SSndToneDB: category=STRUCTURE
    8 x element, all with category=TYPE_REFERENCE:
      pRawTone_ID: implementation-data-type=UInt32
      ToneDeadTime: implementation-data-type=UInt32
      ToneRepetitions: implementation-data-type=DataTypes/UInt8
      Tone_Mixer_Volume: implementation-data-type=DataTypes/UInt8
      Tone_Mixer_FadeIn_Time: implementation-data-type=DataTypes/UInt8
      Tone_Mixer_FadeOut_Time: implementation-data-type=DataTypes/UInt8
      eToneInterruptible: implementation-data-type=ESndToneInterruptableType
      pLinkedTone: implementation-data-type=SSndToneDB
  impl type SSndChimeDB: category=STRUCTURE
    9 x element, all with category=TYPE_REFERENCE:
      eChimeID: implementation-data-type=EChimeID
      ChimeRepeatCnt: implementation-data-type=DataTypes/UInt8
      pLinkedTone: implementation-data-type=SSndToneDB
      pChimeEndToneID: implementation-data-type=SSndToneDB
      UniqueWaveID: implementation-data-type=DataTypes/UInt8
      ChimeChnlBaseVolume: implementation-data-type=DataTypes/UInt8
      SecondaryLinkedToneID: implementation-data-type=SSndToneDB
      SecondaryLinkedEndToneID: implementation-data-type=SSndToneDB
      SafetyChime: implementation-data-type=DataTypes/UInt8
  impl type EChimeType: category=VALUE, base-type=uint8, compu {0=eChimeEvent, 15=eChimeContinuous}, range raw 0..15
  impl type SSndCddChimeData: category=STRUCTURE
    element ChannelId: implementation-data-type=DataTypes/UInt8
    element ChimeType: implementation-data-type=EChimeType
    element DynamicDeadTime: implementation-data-type=UInt16
  impl type ESndInterruptType: category=VALUE, base-type=uint8, compu {0=eSndCdd_InterruptType_None, 1=eSndCdd_InterruptType_TypeA, 2=eSndCdd_InterruptType_TypeB, 3=eSndCdd_InterruptType_TypeDA, 4=eSndCdd_InterruptType_TypeDB, 5=eSndCdd_InterruptType_Immidiate, 6=eSndCdd_InterruptType_Tone, 7=eSndCdd_InterruptType_SoundUnit, 8=eSndCdd_InterruptType_TypeC, 9=eSndCdd_InterruptType_TypeD}, range raw 0..9
  client server interface if_CS_Sndcdd_Services
    16 x operation, all with possible-error=if_CS_Sndcdd_Services/E_NOT_OK:
      CheckChimeStatus
        arg ChimeId: implementation-data-type=EChimeID, type=EChimeID, direction=IN
        arg pChimeStatus: implementation-data-type=EChimeStatus, type=EChimeStatus, direction=OUT
      CheckLastToneStatus
        arg ChimeId: implementation-data-type=EChimeID, type=EChimeID, direction=IN
        arg pLastToneStatus: implementation-data-type=ELastToneStatus, type=ELastToneStatus, direction=OUT
      ClearChimeResumeInfoBuffer
        arg ChimeId: implementation-data-type=EChimeID, type=EChimeID, direction=IN
      GetChimeResumeInfoBuffer
        arg ChimeId: implementation-data-type=EChimeID, type=EChimeID, direction=IN
        arg Resume_Count: implementation-data-type=DataTypes/UInt8, type=DataTypes/UInt8, direction=OUT
      RequestCustomChime
        arg pCustomChimeDescP: implementation-data-type=SSndChimeDB, type=SSndChimeDB, direction=OUT
      RequestToClear_SafetyChimeErrorStatus
        arg ChimeId: implementation-data-type=EChimeID, type=EChimeID, direction=IN
      RequestToStart
        arg ChimeId: implementation-data-type=EChimeID, type=EChimeID, direction=IN
        arg ChimeDataBase: implementation-data-type=SSndCddChimeData, type=SSndCddChimeData, direction=IN
      RequestToStop
        arg ChannelId: implementation-data-type=DataTypes/UInt8, type=DataTypes/UInt8, direction=IN
        arg StopMethod: implementation-data-type=ESndInterruptType, type=ESndInterruptType, direction=IN
      SetChimeResumeInfoBuffer
        arg ChimeId: implementation-data-type=EChimeID, type=EChimeID, direction=IN
        arg ChimeChannelIdData: implementation-data-type=DataTypes/UInt8, type=DataTypes/UInt8, direction=IN
        arg Resume_Count: implementation-data-type=DataTypes/UInt8, type=DataTypes/UInt8, direction=OUT
      SetDynamicDeadTime
        arg ChannelId: implementation-data-type=DataTypes/UInt8, type=DataTypes/UInt8, direction=IN
        arg DeadTime: implementation-data-type=UInt16, type=UInt16, direction=IN
      SetUserPersonalizationVolume
        arg VolumePercentage: implementation-data-type=DataTypes/UInt8, type=DataTypes/UInt8, direction=IN
      StopCustomChime
        arg pCustomChimeDescP: implementation-data-type=SSndChimeDB, type=SSndChimeDB, direction=OUT
      UpdateChannelVolume
        arg ChannelId: implementation-data-type=DataTypes/UInt8, type=DataTypes/UInt8, direction=IN
        arg VolumePercentage: implementation-data-type=DataTypes/UInt8, type=DataTypes/UInt8, direction=IN
      UpdateChimeInfoBuffer
        arg ChimeId: implementation-data-type=EChimeID, type=EChimeID, direction=IN
        arg ChimeChannelIdData: implementation-data-type=DataTypes/UInt8, type=DataTypes/UInt8, direction=IN
      UpdateChimeVolume
        arg ChimeId: implementation-data-type=DataTypes/UInt8, type=DataTypes/UInt8, direction=IN
        arg VolumeLevel: implementation-data-type=DataTypes/UInt8, type=DataTypes/UInt8, direction=IN
      ischannelavailable
        arg ChannelId: implementation-data-type=DataTypes/UInt8, type=DataTypes/UInt8, direction=IN
    error E_NOT_OK: error-code=1
  client server interface TI_DcmExt_Confirmation
    operation DcmExt_Confirmation
      arg Result: implementation-data-type=DataTypes/UInt8, type=DataTypes/UInt8, direction=IN
  4 x impl type, all with category=VALUE, base-type=uint8, range raw 0..255:
    Dcm_OpStatusType
    Dcm_MsgType
    Dcm_NegativeResponseCodeType
    Dcm_SesCtrlType
  client server interface TI_DcmExt_SecLevel1CmpKey
    operation DcmExt_SecLevel1CmpKey: possible-error=TI_DcmExt_SecLevel1CmpKey/E_NOT_OK
      5 x arg:
        OpStatus: implementation-data-type=Dcm_OpStatusType, type=Dcm_OpStatusType, direction=IN
        Buff: implementation-data-type=Dcm_MsgType, type=Dcm_MsgType, direction=IN
        SubFunction: implementation-data-type=DataTypes/UInt8, type=DataTypes/UInt8, direction=IN
        NegRes: implementation-data-type=Dcm_NegativeResponseCodeType, type=Dcm_NegativeResponseCodeType, direction=INOUT
        session: implementation-data-type=Dcm_SesCtrlType, type=Dcm_SesCtrlType, direction=IN
    error E_NOT_OK: error-code=1
  client server interface TI_DcmExt_SecLevel1GetSeed
    operation DcmExt_SecLevel1GetSeed: possible-error=TI_DcmExt_SecLevel1GetSeed/E_NOT_OK
      5 x arg:
        OpStatus: implementation-data-type=Dcm_OpStatusType, type=Dcm_OpStatusType, direction=IN
        Buff: implementation-data-type=Dcm_MsgType, type=Dcm_MsgType, direction=IN
        SubFunction: implementation-data-type=DataTypes/UInt8, type=DataTypes/UInt8, direction=IN
        NegRes: implementation-data-type=Dcm_NegativeResponseCodeType, type=Dcm_NegativeResponseCodeType, direction=INOUT
        session: implementation-data-type=Dcm_SesCtrlType, type=Dcm_SesCtrlType, direction=IN
    error E_NOT_OK: error-code=1
  impl type Dcm_DspDidIdentifierTableType: category=VALUE, base-type=uint16, range raw 0..65535
  4 x client server interface:
    TI_DcmExt_Service_Iocontrol
      operation DcmExt_Service_Iocontrol: possible-error=TI_DcmExt_Service_Iocontrol/E_NOT_OK
        4 x arg:
          OpStatus: implementation-data-type=Dcm_OpStatusType, type=Dcm_OpStatusType, direction=IN
          DataPointer: implementation-data-type=DataTypes/UInt8, type=DataTypes/UInt8, direction=INOUT
          pNrc: implementation-data-type=Dcm_NegativeResponseCodeType, type=Dcm_NegativeResponseCodeType, direction=INOUT
          did: implementation-data-type=Dcm_DspDidIdentifierTableType, type=Dcm_DspDidIdentifierTableType, direction=IN
      error E_NOT_OK: error-code=1
    TI_DcmExt_Services_CndChk
      operation DcmExt_Services_CndChk: possible-error=TI_DcmExt_Services_CndChk/E_NOT_OK
        arg OpStatus: implementation-data-type=Dcm_OpStatusType, type=Dcm_OpStatusType, direction=IN
        arg pNrc: implementation-data-type=Dcm_NegativeResponseCodeType, type=Dcm_NegativeResponseCodeType, direction=INOUT
        arg did: implementation-data-type=Dcm_DspDidIdentifierTableType, type=Dcm_DspDidIdentifierTableType, direction=IN
      error E_NOT_OK: error-code=1
    TI_DcmExt_Services_DataRead
      operation DcmExt_Services_DataRead: possible-error=TI_DcmExt_Services_DataRead/E_NOT_OK
        4 x arg:
          OpStatus: implementation-data-type=Dcm_OpStatusType, type=Dcm_OpStatusType, direction=IN
          pDataPointer: implementation-data-type=DataTypes/UInt8, type=DataTypes/UInt8, direction=INOUT
          did: implementation-data-type=Dcm_DspDidIdentifierTableType, type=Dcm_DspDidIdentifierTableType, direction=IN
          pNrc: implementation-data-type=Dcm_NegativeResponseCodeType, type=Dcm_NegativeResponseCodeType, direction=INOUT
      error E_NOT_OK: error-code=1
    TI_DcmExt_Services_DataWrite
      operation DcmExt_Services_DataWrite: possible-error=TI_DcmExt_Services_DataWrite/E_NOT_OK
        4 x arg:
          OpStatus: implementation-data-type=Dcm_OpStatusType, type=Dcm_OpStatusType, direction=IN
          DataPointer: implementation-data-type=DataTypes/UInt8, type=DataTypes/UInt8, direction=INOUT
          pNrc: implementation-data-type=Dcm_NegativeResponseCodeType, type=Dcm_NegativeResponseCodeType, direction=INOUT
          did: implementation-data-type=Dcm_DspDidIdentifierTableType, type=Dcm_DspDidIdentifierTableType, direction=IN
      error E_NOT_OK: error-code=1
  impl type Dcm_MsgLenType: category=VALUE, base-type=uint32, range raw 0..4294967295
  client server interface TI_DcmExt_Services_LenChk
    operation DcmExt_Services_LenChk: possible-error=TI_DcmExt_Services_LenChk/E_NOT_OK
      4 x arg:
        OpStatus: implementation-data-type=Dcm_OpStatusType, type=Dcm_OpStatusType, direction=IN
        pNrc: implementation-data-type=Dcm_NegativeResponseCodeType, type=Dcm_NegativeResponseCodeType, direction=INOUT
        Length: implementation-data-type=Dcm_MsgLenType, type=Dcm_MsgLenType, direction=INOUT
        did: implementation-data-type=Dcm_DspDidIdentifierTableType, type=Dcm_DspDidIdentifierTableType, direction=IN
    error E_NOT_OK: error-code=1
  impl type Dcm_DspRidIdentifierTableType: category=VALUE, base-type=uint16, range raw 0..65535
  4 x client server interface:
    TI_DcmExt_Services_RoutineResults
      operation DcmExt_Services_RoutineResults: possible-error=TI_DcmExt_Services_RoutineResults/E_NOT_OK
        6 x arg:
          OpStatus: implementation-data-type=Dcm_OpStatusType, type=Dcm_OpStatusType, direction=IN
          pOut_RoutineInfo: implementation-data-type=DataTypes/UInt8, type=DataTypes/UInt8, direction=INOUT
          Out_Results_Response: implementation-data-type=DataTypes/UInt8, type=DataTypes/UInt8, direction=INOUT
          DataLength: implementation-data-type=UInt32, type=UInt32, direction=INOUT
          pNrc: implementation-data-type=Dcm_NegativeResponseCodeType, type=Dcm_NegativeResponseCodeType, direction=INOUT
          Rid: implementation-data-type=Dcm_DspRidIdentifierTableType, type=Dcm_DspRidIdentifierTableType, direction=IN
      error E_NOT_OK: error-code=1
    TI_DcmExt_Services_RoutineStart
      operation DcmExt_Services_RoutineStart: possible-error=TI_DcmExt_Services_RoutineStart/E_NOT_OK
        5 x arg:
          OpStatus: implementation-data-type=Dcm_OpStatusType, type=Dcm_OpStatusType, direction=IN
          pOut_RoutineInfo: implementation-data-type=DataTypes/UInt8, type=DataTypes/UInt8, direction=INOUT
          DataLength: implementation-data-type=UInt32, type=UInt32, direction=INOUT
          pNrc: implementation-data-type=Dcm_NegativeResponseCodeType, type=Dcm_NegativeResponseCodeType, direction=INOUT
          Rid: implementation-data-type=Dcm_DspRidIdentifierTableType, type=Dcm_DspRidIdentifierTableType, direction=IN
      error E_NOT_OK: error-code=1
    TI_DcmExt_Services_RoutineStop
      operation DcmExt_Services_RoutineStop: possible-error=TI_DcmExt_Services_RoutineStop/E_NOT_OK
        5 x arg:
          OpStatus: implementation-data-type=Dcm_OpStatusType, type=Dcm_OpStatusType, direction=IN
          pOut_RoutineInfo: implementation-data-type=DataTypes/UInt8, type=DataTypes/UInt8, direction=INOUT
          DataLength: implementation-data-type=UInt32, type=UInt32, direction=INOUT
          pNrc: implementation-data-type=Dcm_NegativeResponseCodeType, type=Dcm_NegativeResponseCodeType, direction=INOUT
          Rid: implementation-data-type=Dcm_DspRidIdentifierTableType, type=Dcm_DspRidIdentifierTableType, direction=IN
      error E_NOT_OK: error-code=1
    TI_DemExt_ClearDTC
      operation DemExt_ClearDTC: possible-error=TI_DemExt_ClearDTC/E_NOT_OK
        arg ClientId: implementation-data-type=DataTypes/UInt8, type=DataTypes/UInt8, direction=IN
      error E_NOT_OK: error-code=1
  impl type Dem_EventIdType: category=VALUE, base-type=uint16, range raw 0..65535
  impl type Dem_DTCFormatType: category=VALUE, base-type=uint8, range raw 0..255
  client server interface TI_DemExt_GetDTCOfEvent
    operation DemExt_GetDTCOfEvent: possible-error=TI_DemExt_GetDTCOfEvent/E_NOT_OK
      arg EventId: implementation-data-type=Dem_EventIdType, type=Dem_EventIdType, direction=IN
      arg DTCFormat: implementation-data-type=Dem_DTCFormatType, type=Dem_DTCFormatType, direction=IN
      arg DTCOfEvent: implementation-data-type=UInt32, type=UInt32, direction=OUT
    error E_NOT_OK: error-code=1
  client server interface TI_DemExt_GetDTCSelectionResult
    operation DemExt_GetDTCSelectionResult: possible-error=TI_DemExt_GetDTCSelectionResult/E_NOT_OK
      arg ClientId: implementation-data-type=DataTypes/UInt8, type=DataTypes/UInt8, direction=IN
    error E_NOT_OK: error-code=1
  client server interface TI_DemExt_GetDTCSelectionResultForClearDTC
    operation DemExt_GetDTCSelectionResultForClearDTC: possible-error=TI_DemExt_GetDTCSelectionResultForClearDTC/E_NOT_OK
      arg ClientId: implementation-data-type=DataTypes/UInt8, type=DataTypes/UInt8, direction=IN
    error E_NOT_OK: error-code=1
  impl type Dem_DebouncingStateType: category=VALUE, base-type=uint8, range raw 0..255
  client server interface TI_DemExt_GetDebouncingOfEvent
    operation DemExt_GetDebouncingOfEvent: possible-error=TI_DemExt_GetDebouncingOfEvent/E_NOT_OK
      arg EventId: implementation-data-type=Dem_EventIdType, type=Dem_EventIdType, direction=IN
      arg DebouncingState: implementation-data-type=Dem_DebouncingStateType, type=Dem_DebouncingStateType, direction=OUT
    error E_NOT_OK: error-code=1
  client server interface TI_DemExt_GetEventExtendedDataRecordEx
    operation DemExt_GetEventExtendedDataRecordEx: possible-error=TI_DemExt_GetEventExtendedDataRecordEx/E_NOT_OK
      4 x arg:
        EventId: implementation-data-type=Dem_EventIdType, type=Dem_EventIdType, direction=IN
        RecordNumber: implementation-data-type=DataTypes/UInt8, type=DataTypes/UInt8, direction=IN
        DestBuffer: implementation-data-type=DataTypes/UInt8, type=DataTypes/UInt8, direction=OUT
        BufSize: implementation-data-type=UInt16, type=UInt16, direction=INOUT
    error E_NOT_OK: error-code=1
  client server interface TI_DemExt_GetEventFreezeFrameDataEx
    operation DemExt_GetEventFreezeFrameDataEx: possible-error=TI_DemExt_GetEventFreezeFrameDataEx/E_NOT_OK
      5 x arg:
        EventId: implementation-data-type=Dem_EventIdType, type=Dem_EventIdType, direction=IN
        RecordNumber: implementation-data-type=DataTypes/UInt8, type=DataTypes/UInt8, direction=IN
        DataId: implementation-data-type=UInt16, type=UInt16, direction=IN
        DestBuffer: implementation-data-type=DataTypes/UInt8, type=DataTypes/UInt8, direction=OUT
        BufSize: implementation-data-type=UInt16, type=UInt16, direction=INOUT
    error E_NOT_OK: error-code=1
  impl type Dem_UdsStatusByteType: category=VALUE, base-type=uint8, range raw 0..255
  client server interface TI_DemExt_GetEventUdsStatus
    operation DemExt_GetEventUdsStatus: possible-error=TI_DemExt_GetEventUdsStatus/E_NOT_OK
      arg EventId: implementation-data-type=Dem_EventIdType, type=Dem_EventIdType, direction=IN
      arg UDSStatusByte: implementation-data-type=Dem_UdsStatusByteType, type=Dem_UdsStatusByteType, direction=OUT
    error E_NOT_OK: error-code=1
  client server interface TI_DemExt_GetFaultDetectionCounter
    operation DemExt_GetFaultDetectionCounter: possible-error=TI_DemExt_GetFaultDetectionCounter/E_NOT_OK
      arg EventId: implementation-data-type=Dem_EventIdType, type=Dem_EventIdType, direction=IN
      arg FaultDetectionCounter: implementation-data-type=SInt8, type=SInt8, direction=OUT
    error E_NOT_OK: error-code=1
  impl type Dem_DTCOriginType: category=VALUE, base-type=uint8, range raw 0..255
  client server interface TI_DemExt_GetNumberOfEventMemoryEntries
    operation DemExt_GetNumberOfEventMemoryEntries: possible-error=TI_DemExt_GetNumberOfEventMemoryEntries/E_NOT_OK
      arg ClientId: implementation-data-type=DataTypes/UInt8, type=DataTypes/UInt8, direction=IN
      arg DTCOrigin: implementation-data-type=Dem_DTCOriginType, type=Dem_DTCOriginType, direction=IN
      arg NumberOfEventMemoryEntries: implementation-data-type=DataTypes/UInt8, type=DataTypes/UInt8, direction=OUT
    error E_NOT_OK: error-code=1
  impl type Dem_OperationCycleStateType: category=VALUE, base-type=uint8, range raw 0..255
  4 x client server interface:
    TI_DemExt_GetOperationCycleState
      operation DemExt_GetOperationCycleState: possible-error=TI_DemExt_GetOperationCycleState/E_NOT_OK
        arg OperationCycleId: implementation-data-type=DataTypes/UInt8, type=DataTypes/UInt8, direction=IN
        arg CycleState: implementation-data-type=Dem_OperationCycleStateType, type=Dem_OperationCycleStateType, direction=OUT
      error E_NOT_OK: error-code=1
    TI_DemExt_SelectDTC
      operation DemExt_SelectDTC: possible-error=TI_DemExt_SelectDTC/E_NOT_OK
        4 x arg, all with direction=IN:
          ClientId: implementation-data-type=DataTypes/UInt8, type=DataTypes/UInt8
          DTC: implementation-data-type=UInt32, type=UInt32
          DTCFormat: implementation-data-type=Dem_DTCFormatType, type=Dem_DTCFormatType
          DTCOrigin: implementation-data-type=Dem_DTCOriginType, type=Dem_DTCOriginType
      error E_NOT_OK: error-code=1
    TI_DemExt_SetEnableCondition
      operation DemExt_SetEnableCondition: possible-error=TI_DemExt_SetEnableCondition/E_NOT_OK
        arg EnableConditionID: implementation-data-type=DataTypes/UInt8, type=DataTypes/UInt8, direction=IN
        arg ConditionFulfilled: implementation-data-type=Boolean, type=Boolean, direction=IN
      error E_NOT_OK: error-code=1
    TI_DemExt_SetEventAvailable
      operation DemExt_SetEventAvailable: possible-error=TI_DemExt_SetEventAvailable/E_NOT_OK
        arg EventId: implementation-data-type=Dem_EventIdType, type=Dem_EventIdType, direction=IN
        arg AvailableStatus: implementation-data-type=Boolean, type=Boolean, direction=IN
      error E_NOT_OK: error-code=1
  impl type Dem_EventStatusType: category=VALUE, base-type=uint8, range raw 0..255
  client server interface TI_DemExt_SetEventStatus
    operation DemExt_SetEventStatus: possible-error=TI_DemExt_SetEventStatus/E_NOT_OK
      arg EventId: implementation-data-type=Dem_EventIdType, type=Dem_EventIdType, direction=IN
      arg EventStatus: implementation-data-type=Dem_EventStatusType, type=Dem_EventStatusType, direction=IN
    error E_NOT_OK: error-code=1
  client server interface TI_DemExt_SetOperationCycleState
    operation DemExt_SetOperationCycleState: possible-error=TI_DemExt_SetOperationCycleState/E_NOT_OK
      arg OperationCycleId: implementation-data-type=DataTypes/UInt8, type=DataTypes/UInt8, direction=IN
      arg CycleState: implementation-data-type=Dem_OperationCycleStateType, type=Dem_OperationCycleStateType, direction=IN
    error E_NOT_OK: error-code=1
  client server interface TI_DemExt_SetStorageCondition
    operation DemExt_SetStorageCondition: possible-error=TI_DemExt_SetStorageCondition/E_NOT_OK
      arg StorageConditionID: implementation-data-type=DataTypes/UInt8, type=DataTypes/UInt8, direction=IN
      arg ConditionFulfilled: implementation-data-type=Boolean, type=Boolean, direction=IN
    error E_NOT_OK: error-code=1
  impl type SHealthDumpGetData: category=STRUCTURE
    element reserved: implementation-data-type=DataTypes/UInt8
  sender receiver interface HealthDumpGetData_Q: invalidation-policy{data-element=HealthDumpGetDataData, handle-invalid=DONT-INVALIDATE}
    data HealthDumpGetDataData: implementation-data-type=SHealthDumpGetData, sw-impl-policy=QUEUED, type=SHealthDumpGetData
  impl type SHealthDumpGetHdr: category=STRUCTURE
    element encrypt: implementation-data-type=DataTypes/UInt8
  sender receiver interface HealthDumpGetHdr_Q: invalidation-policy{data-element=HealthDumpGetHdrData, handle-invalid=DONT-INVALIDATE}
    data HealthDumpGetHdrData: implementation-data-type=SHealthDumpGetHdr, sw-impl-policy=QUEUED, type=SHealthDumpGetHdr
  impl type ESystemState: category=VALUE, base-type=uint8, compu {0=ESystemState_Off, 1=ESystemState_Startup, 2=ESystemState_Up, 3=ESystemState_FullRun, 4=ESystemState_PrepareShutdown, 5=ESystemState_Minimal, 6=ESystemState_Shutdown, 7=ESystemState_Last}, range raw 0..7
  impl type EDomainId: category=VALUE, base-type=uint8, compu {0=EDomainId_VP, 1=EDomainId_Cluster, 2=EDomainId_IVI, 3=EDomainId_Last}, range raw 0..3
  impl type SPowerSystemStateReqChange: category=STRUCTURE
    element state: implementation-data-type=ESystemState
    element domainId: implementation-data-type=EDomainId
  sender receiver interface PowerSystemStateReqChange: invalidation-policy{data-element=PowerSystemStateReqChangeData, handle-invalid=DONT-INVALIDATE}
    data PowerSystemStateReqChangeData: implementation-data-type=SPowerSystemStateReqChange, type=SPowerSystemStateReqChange
  impl type EDmnChangeReqStatus_t: category=VALUE, base-type=uint8, compu {0=EDmnChangeReqStatus_NoReq, 1=EDmnChangeReqStatus_WaitAwakeTime, 2=EDmnChangeReqStatus_WaitShutdonwTime, 3=EDmnChangeReqStatus_PrevReqPending, 4=EDmnChangeReqStatus_ReqSucceed, 5=EDmnChangeReqStatus_ReqFail, 6=EDmnChangeReqStatus_ReqTimedOut, 7=EDmnChangeReqStatus_DmnNotReady}, range raw 0..7
  client server interface if_CS_DmnSystemStateChange
    operation DmnSystemStateChangeReq: possible-error=if_CS_DmnSystemStateChange/E_NOT_OK
      arg DmnId: implementation-data-type=EDomainId, type=EDomainId, direction=IN
      arg DmnState: implementation-data-type=ESystemState, type=ESystemState, direction=IN
    operation DmnSystemStateChangeStatus
      arg DmnId: implementation-data-type=EDomainId, type=EDomainId, direction=IN
      arg DmnStatus: implementation-data-type=EDmnChangeReqStatus_t, type=EDmnChangeReqStatus_t, direction=OUT
    error E_NOT_OK: error-code=1
  client server interface if_CS_DmnMonitoring
    operation StartDomainMonitoring: possible-error=if_CS_DmnMonitoring/E_NOT_OK
      arg DmnID: implementation-data-type=EDomainId, type=EDomainId, direction=IN
    operation StopDomainMonitoring: possible-error=if_CS_DmnMonitoring/E_NOT_OK
      arg DmnID: implementation-data-type=EDomainId, type=EDomainId, direction=IN
    error E_NOT_OK: error-code=1
  client server interface UclSystemCallbacks
    operation ErrorNotification
      arg DLInst: implementation-data-type=DataTypes/UInt8, type=DataTypes/UInt8, direction=IN
      arg ErrorCode: implementation-data-type=SInt32, type=SInt32, direction=IN
    operation LinkStatusChanged
      arg DLInst: implementation-data-type=DataTypes/UInt8, type=DataTypes/UInt8, direction=IN
      arg Status: implementation-data-type=SInt32, type=SInt32, direction=IN
  impl type EUclLinkState_t: category=VALUE, base-type=uint8, compu {0=EUclLinkState_Not_Rcvd, 1=EUclLinkState_Down, 2=EUclLinkState_Up, 3=EUclLinkState_Last}, range raw 0..3
  impl type EDmnHealthState_t: category=VALUE, base-type=uint8, compu {0=EDmnHealth_Active, 1=EDmnHealth_UCL_Fatal_Error, 2=EDmnHealth_HB_Miss, 3=EDmnHealth_Fatal_Error, 4=EDmnHealth_Rcvd_Inv_SeqCnt, 5=EDmnHealth_First_HB_Rcv_Time_Expired, 6=EDmnHealth_First_LinkUp_Time_Expired, 7=EDmnHealth_Shutdown_Time_Expired, 8=EDmnHealth_Last}, range raw 0..8
  impl type EDmnOverallState_t: category=VALUE, base-type=uint8, compu {0=DMN_NOT_READY, 1=DMN_READY}, range raw 0..1
  impl type SDmnStatus: category=STRUCTURE
    6 x element, all with category=TYPE_REFERENCE:
      dmnId: implementation-data-type=EDomainId
      linkStatus: implementation-data-type=EUclLinkState_t
      uclErrCode: implementation-data-type=SInt32
      dmnHealthState: implementation-data-type=EDmnHealthState_t
      state: implementation-data-type=ESystemState
      dmnStatus: implementation-data-type=EDmnOverallState_t
  sender receiver interface if_SR_DmnInfo: invalidation-policy{data-element=SDmnStatus, handle-invalid=DONT-INVALIDATE}
    data SDmnStatus: implementation-data-type=SDmnStatus, type=SDmnStatus
  impl type SHealthDomainFatalError: category=STRUCTURE
    element domainId: implementation-data-type=EDomainId
    element compldx: implementation-data-type=UInt32
  sender receiver interface HealthDomainFatalError_Q: invalidation-policy{data-element=HealthDomainFatalErrorData, handle-invalid=DONT-INVALIDATE}
    data HealthDomainFatalErrorData: implementation-data-type=SHealthDomainFatalError, sw-impl-policy=QUEUED, type=SHealthDomainFatalError
  impl type SHealthDomainHeartbeat: category=STRUCTURE
    element domainId: implementation-data-type=EDomainId
    element seqCnt: implementation-data-type=UInt32
  sender receiver interface HealthDomainHeartbeat_Q: invalidation-policy{data-element=HealthDomainHeartbeatData, handle-invalid=DONT-INVALIDATE}
    data HealthDomainHeartbeatData: implementation-data-type=SHealthDomainHeartbeat, sw-impl-policy=QUEUED, type=SHealthDomainHeartbeat
  impl type data_u8_32: category=ARRAY
    element ArrayElement: category=VALUE, array-size=32, array-size-semantics=FIXED-SIZE, base-type=uint8
  impl type SHealthDumpData: category=STRUCTURE
    element chunkSize: implementation-data-type=UInt32
    element data: implementation-data-type=data_u8_32
  sender receiver interface HealthDumpData_Q: invalidation-policy{data-element=HealthDumpDataData, handle-invalid=DONT-INVALIDATE}
    data HealthDumpDataData: implementation-data-type=SHealthDumpData, sw-impl-policy=QUEUED, type=SHealthDumpData
  impl type SHealthDumpHdrInfo: category=STRUCTURE
    element fileSize: implementation-data-type=UInt32
  sender receiver interface HealthDumpHdrInfo_Q: invalidation-policy{data-element=HealthDumpHdrInfoData, handle-invalid=DONT-INVALIDATE}
    data HealthDumpHdrInfoData: implementation-data-type=SHealthDumpHdrInfo, sw-impl-policy=QUEUED, type=SHealthDumpHdrInfo
  impl type SPowerExtendShutdownTime: category=STRUCTURE
    element domainId: implementation-data-type=EDomainId
    element timeoutMs: implementation-data-type=UInt32
  sender receiver interface PowerExtendShutdownTime_Q: invalidation-policy{data-element=PowerExtendShutdownTimeData, handle-invalid=DONT-INVALIDATE}
    data PowerExtendShutdownTimeData: implementation-data-type=SPowerExtendShutdownTime, sw-impl-policy=QUEUED, type=SPowerExtendShutdownTime
  impl type SPowerKeepSystemAwake: category=STRUCTURE
    element domainId: implementation-data-type=EDomainId
    element timeoutMs: implementation-data-type=UInt32
  sender receiver interface PowerKeepSystemAwake_Q: invalidation-policy{data-element=PowerKeepSystemAwakeData, handle-invalid=DONT-INVALIDATE}
    data PowerKeepSystemAwakeData: implementation-data-type=SPowerKeepSystemAwake, sw-impl-policy=QUEUED, type=SPowerKeepSystemAwake
  impl type SPowerSystemState: category=STRUCTURE
    element domainId: implementation-data-type=EDomainId
    element state: implementation-data-type=ESystemState
  sender receiver interface PowerSystemState: invalidation-policy{data-element=PowerSystemStateData, handle-invalid=DONT-INVALIDATE}
    data PowerSystemStateData: implementation-data-type=SPowerSystemState, type=SPowerSystemState
  client server interface UclInitShutdown
    operation Impl_Initialize: possible-error=UclInitShutdown/E_NOT_OK
    operation Impl_Shutdown: possible-error=UclInitShutdown/E_NOT_OK
    error E_NOT_OK: error-code=1
  impl type data_u8_8: category=ARRAY
    element ArrayElement: category=VALUE, array-size=8, array-size-semantics=FIXED-SIZE, base-type=uint8
  impl type SHealthEventRecord: category=STRUCTURE
    element recordType: implementation-data-type=DataTypes/UInt8
    element recordLen: implementation-data-type=DataTypes/UInt8
    element recordData: implementation-data-type=data_u8_8
  sender receiver interface HealthEventRecord_Q: invalidation-policy{data-element=HealthEventRecordData, handle-invalid=DONT-INVALIDATE}
    data HealthEventRecordData: implementation-data-type=SHealthEventRecord, sw-impl-policy=QUEUED, type=SHealthEventRecord
  impl type EDidType: category=VALUE, base-type=uint8, compu {0=EDidType_Read, 1=EDidType_Write, 2=EDidType_Last}, range raw 0..2
  impl type data_u8_256: category=ARRAY
    element ArrayElement: category=VALUE, array-size=256, array-size-semantics=FIXED-SIZE, base-type=uint8
  impl type SDiagDIDRequest: category=STRUCTURE
    4 x element, all with category=TYPE_REFERENCE:
      did: implementation-data-type=UInt16
      didType: implementation-data-type=EDidType
      dataLen: implementation-data-type=UInt16
      data: implementation-data-type=data_u8_256
  sender receiver interface DiagDIDRequest_Q: invalidation-policy{data-element=DiagDIDRequestData, handle-invalid=DONT-INVALIDATE}
    data DiagDIDRequestData: implementation-data-type=SDiagDIDRequest, sw-impl-policy=QUEUED, type=SDiagDIDRequest
  impl type EIOCtrlOptType: category=VALUE, base-type=uint8, compu {0=EIOCtrlOptType_returnControlToECU, 1=EIOCtrlOptType_resetToDefault, 2=EIOCtrlOptType_freezeCurrentState, 3=EIOCtrlOptType_shortTermAdjustment, 4=EIOCtrlOptType_Last}, range raw 0..4
  impl type SDiagIOCtrlRequest: category=STRUCTURE
    4 x element, all with category=TYPE_REFERENCE:
      did: implementation-data-type=UInt16
      optionCtrl: implementation-data-type=EIOCtrlOptType
      dataLen: implementation-data-type=UInt16
      data: implementation-data-type=data_u8_256
  sender receiver interface DiagIOCtrlRequest_Q: invalidation-policy{data-element=DiagIOCtrlRequestData, handle-invalid=DONT-INVALIDATE}
    data DiagIOCtrlRequestData: implementation-data-type=SDiagIOCtrlRequest, sw-impl-policy=QUEUED, type=SDiagIOCtrlRequest
  impl type ERoutineType: category=VALUE, base-type=uint8, compu {0=ERoutineType_Start, 1=ERoutineType_Stop, 2=ERoutineType_QueryResults, 3=ERoutineType_Last}, range raw 0..3
  impl type SDiagRoutineRequest: category=STRUCTURE
    4 x element, all with category=TYPE_REFERENCE:
      routineId: implementation-data-type=UInt16
      routineType: implementation-data-type=ERoutineType
      dataLen: implementation-data-type=UInt16
      data: implementation-data-type=data_u8_256
  sender receiver interface DiagRoutineRequest_Q: invalidation-policy{data-element=DiagRoutineRequestData, handle-invalid=DONT-INVALIDATE}
    data DiagRoutineRequestData: implementation-data-type=SDiagRoutineRequest, sw-impl-policy=QUEUED, type=SDiagRoutineRequest
  impl type EIgnitionStatus: category=VALUE, base-type=uint8, compu {0=EIgnitionStatus_Off, 1=EIgnitionStatus_Acc, 2=EIgnitionStatus_Start, 3=EIgnitionStatus_Run, 4=EIgnitionStatus_Last}, range raw 0..4
  impl type SIgnState: category=STRUCTURE
    element state: implementation-data-type=EIgnitionStatus
  sender receiver interface IgnState_Q: invalidation-policy{data-element=IgnStateData, handle-invalid=DONT-INVALIDATE}
    data IgnStateData: implementation-data-type=SIgnState, sw-impl-policy=QUEUED, type=SIgnState
  client server interface if_CS_EcuAppM
    operation EcuAppM_SetWakeupSources
      arg WakeupSource: implementation-data-type=UInt32, type=UInt32, direction=IN
    operation Init
  impl type EcuM_UserType: category=VALUE, base-type=uint8, range raw 0..255
  5 x client server interface:
    TI_EcuMExt_ReleaseRUN
      operation ReleaseRUN: possible-error=TI_EcuMExt_ReleaseRUN/E_NOT_OK
        arg user: implementation-data-type=EcuM_UserType, type=EcuM_UserType, direction=IN
      error E_NOT_OK: error-code=1
    TI_EcuMExt_RequestRUN
      operation RequestRUN: possible-error=TI_EcuMExt_RequestRUN/E_NOT_OK
        arg user: implementation-data-type=EcuM_UserType, type=EcuM_UserType, direction=IN
      error E_NOT_OK: error-code=1
    TI_NvMExt_GetReadAllStatus
      operation NvmExt_GetNvMReadAllStatus
        arg Status: implementation-data-type=Boolean, type=Boolean, direction=OUT
    TI_NvMExt_SleepOperations
      operation NvMExt_CancelSleep: possible-error=TI_NvMExt_SleepOperations/E_NOT_OK
      operation NvMExt_ReadytoSleep: possible-error=TI_NvMExt_SleepOperations/E_NOT_OK
      operation NvMExt_RequestSleep: possible-error=TI_NvMExt_SleepOperations/E_NOT_OK
      error E_NOT_OK: error-code=1
    TI_NvmExt_StartNvmReadAll
      operation NvMExt_ReadAll
  impl type NvM_BlockIdType: category=VALUE, base-type=uint16, range raw 0..65535
  impl type NvM_RequestResultType: category=VALUE, base-type=uint8, range raw 0..255
  5 x client server interface:
    TI_NvMExt_GetErrorStatus
      operation NvMExt_GetErrorStatus: possible-error=TI_NvMExt_GetErrorStatus/E_NOT_OK
        arg NvmBlockId: implementation-data-type=NvM_BlockIdType, type=NvM_BlockIdType, direction=IN
        arg RequestResultPtr: implementation-data-type=NvM_RequestResultType, type=NvM_RequestResultType, direction=INOUT
      error E_NOT_OK: error-code=1
    TI_NvMExt_ReadBlock
      operation NvMExt_ReadBlock: possible-error=TI_NvMExt_ReadBlock/E_NOT_OK
        arg NvmBlockId: implementation-data-type=NvM_BlockIdType, type=NvM_BlockIdType, direction=IN
        arg NvMDstPtr: implementation-data-type=DataTypes/UInt8, type=DataTypes/UInt8, direction=INOUT
      error E_NOT_OK: error-code=1
    TI_NvMExt_RestoreBlockDefaults
      operation NvMExt_RestoreBlockDefaults: possible-error=TI_NvMExt_RestoreBlockDefaults/E_NOT_OK
        arg NvmBlockId: implementation-data-type=NvM_BlockIdType, type=NvM_BlockIdType, direction=IN
        arg NvMDstPtr: implementation-data-type=DataTypes/UInt8, type=DataTypes/UInt8, direction=INOUT
      error E_NOT_OK: error-code=1
    TI_NvMExt_WriteBlock
      operation NvMExt_WriteBlock: possible-error=TI_NvMExt_WriteBlock/E_NOT_OK
        arg NvmBlockId: implementation-data-type=NvM_BlockIdType, type=NvM_BlockIdType, direction=IN
        arg NvM_SrcPtr: implementation-data-type=DataTypes/UInt8, type=DataTypes/UInt8, direction=INOUT
      error E_NOT_OK: error-code=1
    TI_NvmExt_GetPendingStatus
      operation NvMExt_GetPendingStatus: possible-error=TI_NvmExt_GetPendingStatus/E_NOT_OK
        arg NvmBlockID: implementation-data-type=DataTypes/UInt8, type=DataTypes/UInt8, direction=IN
        arg Status: implementation-data-type=DataTypes/UInt8, type=DataTypes/UInt8, direction=OUT
      error E_NOT_OK: error-code=1
  sender receiver interface TI_NvMExt_WakeupStatus: invalidation-policy{data-element=WakeupFlag, handle-invalid=DONT-INVALIDATE}
    data WakeupFlag: implementation-data-type=Boolean, type=Boolean
  impl type HTimer:
    category=VALUE
    base-type=uint8
    compu {0=eWarningMask_Timerhandle, 1=eOWC_Timerhandle, 2=eNWD_Timerhandle, 3=eWarningBulbCheckMask_Timerhandle, 4=eInitWarning_TimerHandle, 5=eInitChimeTimerHandle, 6=eProgrammingTimerHandle, 7=eStubCounter_TimerHanlde, 8=eModeMgrDisplayPowerDownUp, 9=eModeMgrDisplayFaultAction, 10=eModeMgrDomanResetAction, 11=eModeMgrPowerFaultAction, 12=eEtm4SecTimer, 13=eEtm1200msecTimer, 14=eEtm3SecTimer, 15=eCallbackTimerOdoMdl, 16=eThrottleTimerOdoMdl, 17=eChangeupCallbackTimerodoMdl, 18=eTimerVehicleState, 19=eTimerVariantConfig, 20=WARNING_DISPLAY_TIMER_ID, 21=WARNING_HOLD_TIMER_ID, 22=WARNING_CYCLE_TIMER_ID, 23=WARNING_DISPLAYHOLD_TIMER_ID, 24=WARNING_ACK_TIMER_ID, 25=eTimerHandle_Sleep, 26=eInStartCount_TimerHandle, 27=eVehicleModeCount_TimerHandle, 28=e10secTimer, 29=e3secTimer, 30=e30secTimer, 31=e2_6secTimer, 32=eDcmApp5secTimer, 33=eDcmApp1secTimer, 34=eLidopen_OFFTimer, 35=eLidopen_ONTimer, 36=POPUP_DISPLAY_TIMER_ID, 37=POPUP_GRP_TAB_TIMER_ID, 38=eDrvRec5_6Timer, 39=eDrvRec3_6Timer, 40=eIDS_1SecTimer, 41=eIDS3_1SecTimer, 42=eIDS_3SecTimer, 43=ePerDispSet100msTimer, 44=eDrvRec1_2secTimer, 45=eDrvRec0_8secTimer, 46=eHMI_Initial_Blank_timer_ID, 47=eHMI_Fade_in_delay_timer_ID, 48=eKM6secTimer, 49=eKM5_8secTimer, 50=eKM0_6secTimer, 51=eKM0_2secTimer, 52=eIgnCANMode_3SecTimer, 53=eDem2_6secTimer, 54=eDem5secTimer, 55=e2FRheo5secTimer, 56=e2FSTSW5secTimer, 57=eLSTM3_Timer, 58=eLSTM4_Timer, 59=eDem_AFS_5sec_Timer, 60=WARNING_MSGTIMEOUT_1SEC_TIMER_ID, 61=eDCMApp_30Sec_Timer, 62=WRN_ACK_REDISPLAY_TIMER_ID, 63=eMenuScrollStart1sTimer, 64=eType4_6secTimer, 65=eDcmApp_0_35secTimer, 66=eDcmApp_0_35_1secTimer, 67=eRemoteCarFindCtrlStateTimer, 68=eBrake_Red_100msecTimer, 69=eStreeingSw_ReleaseTimer, 70=POPUP_SETTING_TIMER_ID, 71=eMenu100msTimer, 72=eBuzzerMiddleEast_6secs, 73=eBuzzerMiddleEast_6secs_2, 74=eMaxNumof16BitTimers, 75=eSleepMaxTimer, 76=eRentACarTimer, 77=eDoorWarn_Timer, 78=eSample32BitTimer, 79=eTimerMax}
    range raw 0..79
  5 x client server interface:
    TI_If_TmExt_Timer_GetElapsedTime
      operation Timer_GetElapsedTime
        arg hTimer: implementation-data-type=HTimer, type=HTimer, direction=IN
        arg ElapsedTime: implementation-data-type=UInt32, type=UInt32, direction=OUT
    TI_If_TmExt_Timer_IsElapsed
      operation Timer_IsElapsed
        arg hTimer: implementation-data-type=HTimer, type=HTimer, direction=IN
        arg Timeout: implementation-data-type=UInt32, type=UInt32, direction=IN
        arg IsElapsed: implementation-data-type=Boolean, type=Boolean, direction=OUT
    TI_If_TmExt_Timer_IsStarted
      operation Timer_IsStarted
        arg hTimer: implementation-data-type=HTimer, type=HTimer, direction=IN
        arg IsStarted: implementation-data-type=Boolean, type=Boolean, direction=OUT
    TI_If_TmExt_Timer_Start
      operation Timer_Start
        arg hTimer: implementation-data-type=HTimer, type=HTimer, direction=IN
    TI_If_TmExt_Timer_Stop
      operation Timer_Stop
        arg hTimer: implementation-data-type=HTimer, type=HTimer, direction=IN
package /E40_Platform_System_SystemPackage/Types/DataConstrs
  range UInt16_DataConstraint: raw 0..65535
  range UInt32_DataConstraint: raw 0..4294967295
  range Boolean_DataConstraint: raw 0..1
  range SInt32_DataConstraint: raw -2147483648..2147483647
  range UInt8_DataConstraint: raw 0..255
  range UInt8_DataConstraint: raw 0..255
  range SInt8_DataConstraint: raw -128..127
